VERSION ""

NS_ :

BS_:

BU_: L_3HKBD L_FHPTC L_ATCU L_2HKBD L_PCM L_ATCU_vMON L_EVNT L_HKBD L_RHPTC

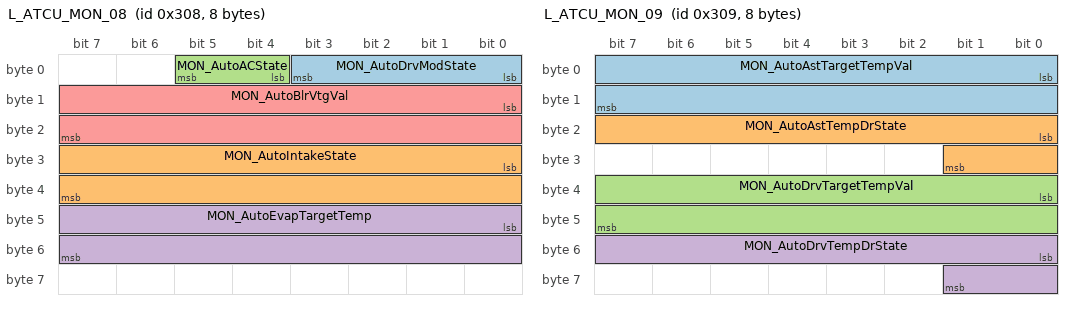
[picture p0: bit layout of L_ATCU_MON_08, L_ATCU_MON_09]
BO_ 776 L_ATCU_MON_08: 8 L_ATCU_vMON
 SG_ MON_AutoDrvModState : 0|4@1+ (1,0) [0|15] ""  L_ATCU
 SG_ MON_AutoIntakeState : 24|16@1+ (1,0) [0|65535] ""  L_ATCU
 SG_ MON_AutoACState : 4|2@1+ (1,0) [0|3] ""  L_ATCU
 SG_ MON_AutoEvapTargetTemp : 40|16@1+ (0.1,-20) [-20|40] ""  L_ATCU
 SG_ MON_AutoBlrVtgVal : 8|16@1+ (1,0) [0|65535] ""  L_ATCU

BO_ 777 L_ATCU_MON_09: 8 L_ATCU_vMON
 SG_ MON_AutoAstTargetTempVal : 0|16@1+ (0.1,-40) [-40|60] ""  L_ATCU
 SG_ MON_AutoAstTempDrState : 16|10@1+ (1,0) [0|1023] ""  L_ATCU
 SG_ MON_AutoDrvTargetTempVal : 32|16@1+ (0.1,-40) [-40|60] ""  L_ATCU
 SG_ MON_AutoDrvTempDrState : 48|10@1+ (1,0) [0|1023] "%"  L_ATCU

BO_ 68 L_HKBD_04: 8 L_HKBD
 SG_ HKBD_Fr_DrTempDnSw : 0|1@1+ (1,0) [0|0] ""  L_ATCU
 SG_ HKBD_Fr_DrTempUpSw : 1|1@1+ (1,0) [0|0] ""  L_ATCU
 SG_ HKBD_Fr_PsBlwDnSw : 11|1@1+ (1,0) [0|0] ""  L_ATCU
 SG_ HKBD_Fr_PsBlwDnOffSw : 12|1@1+ (1,0) [0|0] ""  L_ATCU
 SG_ HKBD_Fr_PsBlwUpSw : 13|1@1+ (1,0) [0|0] ""  L_ATCU
 SG_ HKBD_Fr_PsBlwSet : 14|4@1+ (1,0) [0|0] ""  L_ATCU
 SG_ HKBD_Fr_RrDrTempDnSw : 18|1@1+ (1,0) [0|0] ""  L_ATCU
 SG_ HKBD_Fr_RrDrTempUpSw : 19|1@1+ (1,0) [0|0] ""  L_ATCU
 SG_ HKBD_Fr_PsTempDnSw : 2|1@1+ (1,0) [0|0] ""  L_ATCU
 SG_ HKBD_Fr_RrDrBlwDnSw : 20|1@1+ (1,0) [0|0] ""  L_ATCU
 SG_ HKBD_Fr_RrDrBlwDnOffSw : 21|1@1+ (1,0) [0|0] ""  L_ATCU
 SG_ HKBD_Fr_RrDrBlwUpSw : 22|1@1+ (1,0) [0|0] ""  L_ATCU
 SG_ HKBD_Fr_RrDrBlwSet : 23|4@1+ (1,0) [0|0] ""  L_ATCU
 SG_ HKBD_Fr_RrDrModDnSw : 27|1@1+ (1,0) [0|0] ""  L_ATCU
 SG_ HKBD_Fr_RrDrModUpSw : 28|1@1+ (1,0) [0|0] ""  L_ATCU
 SG_ HKBD_Fr_RrDrModVntSw : 29|1@1+ (1,0) [0|0] ""  L_ATCU
 SG_ HKBD_Fr_PsTempUpSw : 3|1@1+ (1,0) [0|0] ""  L_ATCU
 SG_ HKBD_Fr_RrDrModFlrSw : 30|1@1+ (1,0) [0|0] ""  L_ATCU
 SG_ HKBD_Fr_RrDrModBiLvlSw : 31|1@1+ (1,0) [0|0] ""  L_ATCU
 SG_ HKBD_Fr_RrDrAutoSw : 32|1@1+ (1,0) [0|0] ""  L_ATCU
 SG_ HKBD_Fr_RrDrMultiAutoSw : 33|3@1+ (1,0) [0|0] ""  L_ATCU
 SG_ HKBD_Fr_RrOffSw : 36|1@1+ (1,0) [0|0] ""  L_ATCU
 SG_ HKBD_Fr_RrSyncSw : 37|1@1+ (1,0) [0|0] ""  L_ATCU
 SG_ HKBD_Fr_RLStHeatSw : 38|1@1+ (1,0) [0|0] ""  L_ATCU
 SG_ HKBD_Fr_RLStVentSw : 39|1@1+ (1,0) [0|0] ""  L_ATCU
 SG_ HKBD_Fr_DrBlwDnSw : 4|1@1+ (1,0) [0|0] ""  L_ATCU
 SG_ HKBD_Fr_RRStHeatSw : 40|1@1+ (1,0) [0|0] ""  L_ATCU
 SG_ HKBD_Fr_RRStVentSw : 41|1@1+ (1,0) [0|0] ""  L_ATCU
 SG_ HKBD_Fr_RLStTumblrSw : 42|2@1+ (1,0) [0|0] ""  L_ATCU
 SG_ HKBD_Fr_RRStTumblrSw : 44|2@1+ (1,0) [0|0] ""  L_ATCU
 SG_ HKBD_Fr_RrPsModDnSw : 46|1@1+ (1,0) [0|0] ""  L_ATCU
 SG_ HKBD_Fr_RrPsModUpSw : 47|1@1+ (1,0) [0|0] ""  L_ATCU
 SG_ HKBD_Fr_RrPsModVntSw : 48|1@1+ (1,0) [0|0] ""  L_ATCU
 SG_ HKBD_Fr_RrPsModFlrSw : 49|1@1+ (1,0) [0|0] ""  L_ATCU
 SG_ HKBD_Fr_DrBlwDnOffSw : 5|1@1+ (1,0) [0|0] ""  L_ATCU
 SG_ HKBD_Fr_RrLockSw : 50|1@1+ (1,0) [0|0] ""  L_ATCU
 SG_ HKBD_Fr_RrPsModBiLvlSw : 51|1@1+ (1,0) [0|0] ""  L_ATCU
 SG_ HKBD_Fr_RrDrModSw : 52|1@1+ (1,0) [0|0] ""  L_ATCU
 SG_ HKBD_Fr_RrPsModSw : 53|1@1+ (1,0) [0|0] ""  L_ATCU
 SG_ HKBD_Fr_RrPsBlwSet : 54|4@1+ (1,0) [0|0] ""  L_ATCU
 SG_ HKBD_Fr_RrPsBlwUpSw : 58|1@1+ (1,0) [0|0] ""  L_ATCU
 SG_ HKBD_Fr_RrPsBlwDnSw : 59|1@1+ (1,0) [0|0] ""  L_ATCU
 SG_ HKBD_Fr_DrBlwUpSw : 6|1@1+ (1,0) [0|0] ""  L_ATCU
 SG_ HKBD_Fr_RrPsBlwDnOffSw : 60|1@1+ (1,0) [0|0] ""  L_ATCU
 SG_ HKBD_Fr_RrPsTempDnSw : 61|1@1+ (1,0) [0|0] ""  L_ATCU
 SG_ HKBD_Fr_RrPsTempUpSw : 62|1@1+ (1,0) [0|0] ""  L_ATCU
 SG_ HKBD_Fr_DrBlwSet : 7|4@1+ (1,0) [0|0] ""  L_ATCU

BO_ 1032 L_EVNT_08: 8 L_EVNT
 SG_ L_EVNT_ATCUComFlt : 0|2@1+ (1,0) [0|0] ""  L_ATCU
 SG_ L_EVNT_DrvCntrHorComFlt : 10|2@1+ (1,0) [0|0] ""  L_ATCU
 SG_ L_EVNT_AstSdVertComFlt : 12|2@1+ (1,0) [0|0] ""  L_ATCU
 SG_ L_EVNT_AstSdHorComFlt : 14|2@1+ (1,0) [0|0] ""  L_ATCU
 SG_ L_EVNT_AstCntrVertComFlt : 16|2@1+ (1,0) [0|0] ""  L_ATCU
 SG_ L_EVNT_AstCntrHorComFlt : 18|2@1+ (1,0) [0|0] ""  L_ATCU
 SG_ L_EVNT_EVNTFlt : 2|2@1+ (1,0) [0|0] ""  L_ATCU
 SG_ L_EVNT_RrDrvCnslVertComFlt : 20|2@1+ (1,0) [0|0] ""  L_ATCU
 SG_ L_EVNT_RrDrvCnslHorComFlt : 22|2@1+ (1,0) [0|0] ""  L_ATCU
 SG_ L_EVNT_RrAstCnslVertComFlt : 24|2@1+ (1,0) [0|0] ""  L_ATCU
 SG_ L_EVNT_RrAstCnslHorComFlt : 26|2@1+ (1,0) [0|0] ""  L_ATCU
 SG_ L_EVNT_DrvSdVertIntFlt : 28|2@1+ (1,0) [0|0] ""  L_ATCU
 SG_ L_EVNT_DrvSdHorIntFlt : 30|2@1+ (1,0) [0|0] ""  L_ATCU
 SG_ L_EVNT_DrvCntrVertIntFlt : 32|2@1+ (1,0) [0|0] ""  L_ATCU
 SG_ L_EVNT_DrvCntrHorIntFlt : 34|2@1+ (1,0) [0|0] ""  L_ATCU
 SG_ L_EVNT_AstSdVertIntFlt : 36|2@1+ (1,0) [0|0] ""  L_ATCU
 SG_ L_EVNT_AstSdHorIntFlt : 38|2@1+ (1,0) [0|0] ""  L_ATCU
 SG_ L_EVNT_DrvSdVertComFlt : 4|2@1+ (1,0) [0|0] ""  L_ATCU
 SG_ L_EVNT_AstCntrVertIntFlt : 40|2@1+ (1,0) [0|0] ""  L_ATCU
 SG_ L_EVNT_AstCntrHorIntFlt : 42|2@1+ (1,0) [0|0] ""  L_ATCU
 SG_ L_EVNT_RrDrvCnslVertIntFlt : 44|2@1+ (1,0) [0|0] ""  L_ATCU
 SG_ L_EVNT_RrDrvCnslHorIntFlt : 46|2@1+ (1,0) [0|0] ""  L_ATCU
 SG_ L_EVNT_RrAstCnslVertIntFlt : 48|2@1+ (1,0) [0|0] ""  L_ATCU
 SG_ L_EVNT_RrAstCnslHorIntFlt : 50|2@1+ (1,0) [0|0] ""  L_ATCU
 SG_ L_EVNT_DrvSdVertExtFlt : 52|2@1+ (1,0) [0|0] ""  L_ATCU
 SG_ L_EVNT_DrvSdHorExtFlt : 54|2@1+ (1,0) [0|0] ""  L_ATCU
 SG_ L_EVNT_DrvCntrVertExtFlt : 56|2@1+ (1,0) [0|0] ""  L_ATCU
 SG_ L_EVNT_DrvCntrHorExtFlt : 58|2@1+ (1,0) [0|0] ""  L_ATCU
 SG_ L_EVNT_DrvSdHorComFlt : 6|2@1+ (1,0) [0|0] ""  L_ATCU
 SG_ L_EVNT_AstSdVertExtFlt : 60|2@1+ (1,0) [0|0] ""  L_ATCU
 SG_ L_EVNT_AstSdHorExtFlt : 62|2@1+ (1,0) [0|0] ""  L_ATCU
 SG_ L_EVNT_DrvCntrVertComFlt : 8|2@1+ (1,0) [0|0] ""  L_ATCU

BO_ 881 L_ATCU_Lib_33: 8 L_ATCU
 SG_ L_ATCU_Lib_StatMngr_2ndMngr : 0|64@1+ (1,0) [0|0] ""  L_ATCU_vMON

BO_ 69 L_HKBD_05: 8 L_HKBD
 SG_ HKBD_Fr_3rdRrTempDnSw : 0|1@1+ (1,0) [0|0] ""  L_ATCU
 SG_ HKBD_Fr_3rdRrTempUpSw : 1|1@1+ (1,0) [0|0] ""  L_ATCU
 SG_ HKBD_Fr_3rdRrModUpSw : 10|1@1+ (1,0) [0|0] ""  L_ATCU
 SG_ HKBD_Fr_3rdRrModVntSw : 11|1@1+ (1,0) [0|0] ""  L_ATCU
 SG_ HKBD_Fr_3rdRrModFlrSw : 12|1@1+ (1,0) [0|0] ""  L_ATCU
 SG_ HKBD_Fr_3rdRrAutoSw : 13|1@1+ (1,0) [0|0] ""  L_ATCU
 SG_ HKBD_Fr_3rdRrMultiAutoSw : 14|3@1+ (1,0) [0|0] ""  L_ATCU
 SG_ HKBD_Fr_3rdRrOffSw : 17|1@1+ (1,0) [0|0] ""  L_ATCU
 SG_ HKBD_Fr_3rdRrSyncSw : 18|1@1+ (1,0) [0|0] ""  L_ATCU
 SG_ HKBD_Fr_3rdRrLockSw : 19|1@1+ (1,0) [0|0] ""  L_ATCU
 SG_ HKBD_Fr_3rdRrBlwDnSw : 2|1@1+ (1,0) [0|0] ""  L_ATCU
 SG_ HKBD_Fr_3rdRrModBiLvlSw : 20|1@1+ (1,0) [0|0] ""  L_ATCU
 SG_ HKBD_FrRrTglSet : 21|2@1+ (1,0) [0|0] ""  L_ATCU
 SG_ HKBD_Fr_RrScrnSet : 23|2@1+ (1,0) [0|0] ""  L_ATCU
 SG_ HKBD_Fr_OnOffSet : 25|2@1+ (1,0) [0|0] ""  L_ATCU
 SG_ HKBD_Fr_RrOnOffSet : 27|2@1+ (1,0) [0|0] ""  L_ATCU
 SG_ HKBD_Fr_3rdRrOnOffSet : 29|2@1+ (1,0) [0|0] ""  L_ATCU
 SG_ HKBD_Fr_3rdRrBlwDnOffSw : 3|1@1+ (1,0) [0|0] ""  L_ATCU
 SG_ HKBD_Fr_RrPsAutoSw : 31|1@1+ (1,0) [0|0] ""  L_ATCU
 SG_ HKBD_Fr_RrPsMultiAutoSw : 32|3@1+ (1,0) [0|0] ""  L_ATCU
 SG_ HKBD_Fr_3rdRrModSw : 35|1@1+ (1,0) [0|0] ""  L_ATCU
 SG_ HKBD_Fr_RrModSet : 36|4@1+ (1,0) [0|0] ""  L_ATCU
 SG_ HKBD_Fr_3rdRrBlwUpSw : 4|1@1+ (1,0) [0|0] ""  L_ATCU
 SG_ HKBD_Fr_3rdModSet : 40|4@1+ (1,0) [0|0] ""  L_ATCU
 SG_ HKBD_Fr_DrblwUpMaxSw : 44|1@1+ (1,0) [0|0] ""  L_ATCU
 SG_ HKBD_Fr_PsblwUpMaxSw : 45|1@1+ (1,0) [0|0] ""  L_ATCU
 SG_ HKBD_Fr_3rdRrBlwSet : 5|4@1+ (1,0) [0|0] ""  L_ATCU
 SG_ HKBD_Fr_3rdRrModDnSw : 9|1@1+ (1,0) [0|0] ""  L_ATCU

BO_ 1033 L_EVNT_09: 8 L_EVNT
 SG_ L_EVNT_AstCntrVertExtFlt : 0|2@1+ (1,0) [0|0] ""  L_ATCU
 SG_ L_EVNT_RrAstCnslHorExtFlt : 10|2@1+ (1,0) [0|0] ""  L_ATCU
 SG_ L_EVNT_AstCntrHorExtFlt : 2|2@1+ (1,0) [0|0] ""  L_ATCU
 SG_ L_EVNT_AllResetOpSta : 36|2@1+ (1,0) [0|0] ""  L_ATCU
 SG_ L_EVNT_DrvSdVertResetOpSta : 38|2@1+ (1,0) [0|0] ""  L_ATCU
 SG_ L_EVNT_RrDrvCnslVertExtFlt : 4|2@1+ (1,0) [0|0] ""  L_ATCU
 SG_ L_EVNT_DrvSdHorResetOpSta : 40|2@1+ (1,0) [0|0] ""  L_ATCU
 SG_ L_EVNT_DrvCntrVertResetOpSta : 42|2@1+ (1,0) [0|0] ""  L_ATCU
 SG_ L_EVNT_DrvCntrHorResetOpSta : 44|2@1+ (1,0) [0|0] ""  L_ATCU
 SG_ L_EVNT_AstSdVertResetOpSta : 46|2@1+ (1,0) [0|0] ""  L_ATCU
 SG_ L_EVNT_AstSdHorResetOpSta : 48|2@1+ (1,0) [0|0] ""  L_ATCU
 SG_ L_EVNT_AstCntrVertResetOpSta : 50|2@1+ (1,0) [0|0] ""  L_ATCU
 SG_ L_EVNT_AstCntrHorResetOpSta : 52|2@1+ (1,0) [0|0] ""  L_ATCU
 SG_ L_EVNT_RrDrvCnslVertResetOpSta : 54|2@1+ (1,0) [0|0] ""  L_ATCU
 SG_ L_EVNT_RrDrvCnslHorResetOpSta : 56|2@1+ (1,0) [0|0] ""  L_ATCU
 SG_ L_EVNT_RrAstCnslVertResetOpSta : 58|2@1+ (1,0) [0|0] ""  L_ATCU
 SG_ L_EVNT_RrDrvCnslHorExtFlt : 6|2@1+ (1,0) [0|0] ""  L_ATCU
 SG_ L_EVNT_RrAstCnslHorResetOpSta : 60|2@1+ (1,0) [0|0] ""  L_ATCU
 SG_ L_EVNT_ResetOpSta : 62|2@1+ (1,0) [0|0] ""  L_ATCU
 SG_ L_EVNT_RrAstCnslVertExtFlt : 8|2@1+ (1,0) [0|0] ""  L_ATCU

BO_ 880 L_ATCU_Lib_32: 8 L_ATCU
 SG_ L_ATCU_Lib_StatMngr_2ndSafetynCool : 0|64@1+ (1,0) [0|0] ""  L_ATCU_vMON

BO_ 70 L_HKBD_06: 8 L_HKBD
 SG_ HKBD_SwBtnTyp : 0|40@1+ (1,0) [0|0] ""  L_ATCU
 SG_ L_HKBD_ResetOpSta : 62|2@1+ (1,0) [0|0] ""  L_ATCU

BO_ 883 L_ATCU_Lib_35: 8 L_ATCU
 SG_ L_ATCU_Lib_StatMngr_2ndAirQuality : 0|64@1+ (1,0) [0|0] ""  L_ATCU_vMON

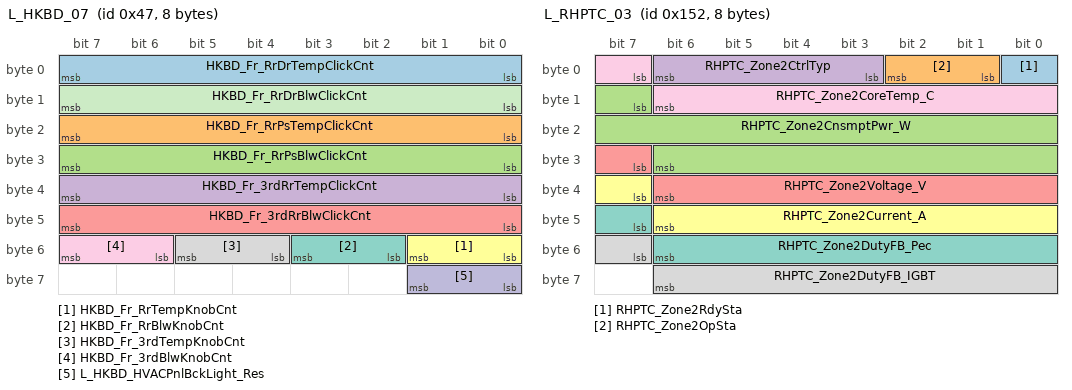
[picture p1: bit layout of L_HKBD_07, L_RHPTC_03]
BO_ 71 L_HKBD_07: 8 L_HKBD
 SG_ HKBD_Fr_RrDrTempClickCnt : 0|8@1+ (1,0) [0|0] ""  L_ATCU
 SG_ HKBD_Fr_RrPsTempClickCnt : 16|8@1+ (1,0) [0|0] ""  L_ATCU
 SG_ HKBD_Fr_RrPsBlwClickCnt : 24|8@1+ (1,0) [0|0] ""  L_ATCU
 SG_ HKBD_Fr_3rdRrTempClickCnt : 32|8@1+ (1,0) [0|0] ""  L_ATCU
 SG_ HKBD_Fr_3rdRrBlwClickCnt : 40|8@1+ (1,0) [0|0] ""  L_ATCU
 SG_ HKBD_Fr_RrTempKnobCnt : 48|2@1+ (1,0) [0|0] ""  L_ATCU
 SG_ HKBD_Fr_RrBlwKnobCnt : 50|2@1+ (1,0) [0|0] ""  L_ATCU
 SG_ HKBD_Fr_3rdTempKnobCnt : 52|2@1+ (1,0) [0|0] ""  L_ATCU
 SG_ HKBD_Fr_3rdBlwKnobCnt : 54|2@1+ (1,0) [0|0] ""  L_ATCU
 SG_ L_HKBD_HVACPnlBckLight_Res : 56|2@1+ (1,0) [0|0] ""  L_ATCU
 SG_ HKBD_Fr_RrDrBlwClickCnt : 8|8@1+ (1,0) [0|0] ""  L_ATCU

BO_ 882 L_ATCU_Lib_34: 8 L_ATCU
 SG_ L_ATCU_Lib_StatMngr_2ndConvenience : 0|64@1+ (1,0) [0|0] ""  L_ATCU_vMON

BO_ 339 L_RHPTC_04: 8 L_RHPTC
 SG_ RHPTC_Zone2Flt : 0|1@1+ (1,0) [0|0] ""  L_ATCU
 SG_ RHPTC_Zone2FltLVLow : 1|1@1+ (1,0) [0|0] ""  L_ATCU
 SG_ RHPTC_Zone2FailLVSnr : 10|1@1+ (1,0) [0|0] ""  L_ATCU
 SG_ RHPTC_Zone2FailCurrentSnr : 11|1@1+ (1,0) [0|0] ""  L_ATCU
 SG_ RHPTC_Zone2FailCoreTempSnr : 12|1@1+ (1,0) [0|0] ""  L_ATCU
 SG_ RHPTC_Zone2FailPcbTempSnr : 13|1@1+ (1,0) [0|0] ""  L_ATCU
 SG_ RHPTC_Zone2FailIGBT : 14|1@1+ (1,0) [0|0] ""  L_ATCU
 SG_ RHPTC_Zone2FailOpenLoad : 15|1@1+ (1,0) [0|0] ""  L_ATCU
 SG_ RHPTC_Zone2LtdOpCause : 16|8@1+ (1,0) [0|0] ""  L_ATCU
 SG_ RHPTC_Zone2FltLVHigh : 2|1@1+ (1,0) [0|0] ""  L_ATCU
 SG_ RHPTC_Zone2SwrVer : 24|8@1+ (1,0) [0|255] ""  L_ATCU
 SG_ RHPTC_Zone2FltHVLow : 3|1@1+ (1,0) [0|0] ""  L_ATCU
 SG_ RHPTC_Zone2FltHVHigh : 4|1@1+ (1,0) [0|0] ""  L_ATCU
 SG_ RHPTC_Zone2FltOverCurrent : 5|1@1+ (1,0) [0|0] ""  L_ATCU
 SG_ RHPTC_Zone2FltThermalShutDn : 6|1@1+ (1,0) [0|0] ""  L_ATCU
 SG_ RHPTC_Zone2FltPcbThermalShutDn : 7|1@1+ (1,0) [0|0] ""  L_ATCU
 SG_ RHPTC_Zone2FltMsgTmOutATCU : 8|1@1+ (1,0) [0|0] ""  L_ATCU
 SG_ RHPTC_Zone2FailHVSnr : 9|1@1+ (1,0) [0|0] ""  L_ATCU

BO_ 885 L_ATCU_Lib_37: 8 L_ATCU
 SG_ L_ATCU_Lib_StatMngr_2ndFuelEfficiency : 0|64@1+ (1,0) [0|0] ""  L_ATCU_vMON

BO_ 338 L_RHPTC_03: 8 L_RHPTC
 SG_ RHPTC_Zone2RdySta : 0|1@1+ (1,0) [0|0] ""  L_ATCU
 SG_ RHPTC_Zone2OpSta : 1|2@1+ (1,0) [0|0] ""  L_ATCU
 SG_ RHPTC_Zone2CnsmptPwr_W : 15|16@1+ (1,0) [0|10000] "W"  L_ATCU
 SG_ RHPTC_Zone2CtrlTyp : 3|4@1+ (1,0) [0|0] ""  L_ATCU
 SG_ RHPTC_Zone2Voltage_V : 31|8@1+ (4,0) [0|1000] "V"  L_ATCU
 SG_ RHPTC_Zone2Current_A : 39|8@1+ (0.2,0) [0|50] "A"  L_ATCU
 SG_ RHPTC_Zone2DutyFB_Pec : 47|8@1+ (0.5,0) [0|100] "%"  L_ATCU
 SG_ RHPTC_Zone2DutyFB_IGBT : 55|8@1+ (0.5,0) [0|100] "%"  L_ATCU
 SG_ RHPTC_Zone2CoreTemp_C : 7|8@1+ (1,-40) [-40|200] "¡É"  L_ATCU

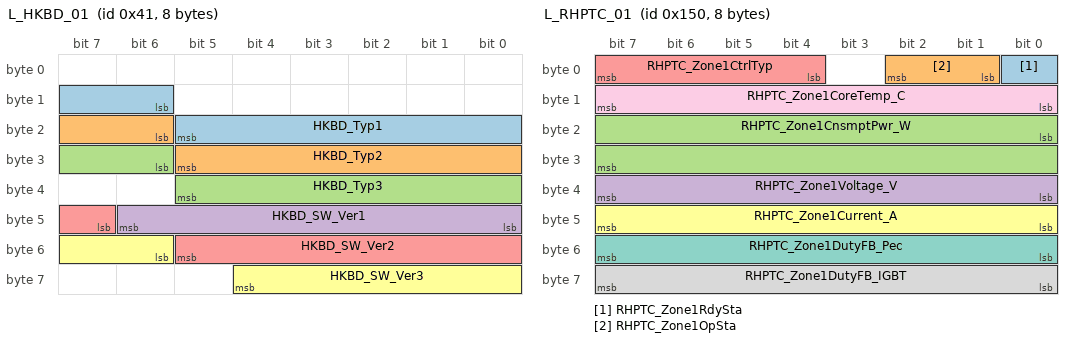
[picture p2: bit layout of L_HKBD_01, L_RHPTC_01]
BO_ 65 L_HKBD_01: 8 L_HKBD
 SG_ HKBD_Typ1 : 14|8@1+ (1,0) [0|0] ""  L_ATCU
 SG_ HKBD_Typ2 : 22|8@1+ (1,0) [0|0] ""  L_ATCU
 SG_ HKBD_Typ3 : 30|8@1+ (1,0) [0|0] ""  L_ATCU
 SG_ HKBD_SW_Ver1 : 40|7@1+ (1,0) [0|0] ""  L_ATCU_vMON
 SG_ HKBD_SW_Ver2 : 47|7@1+ (1,0) [0|0] ""  L_ATCU_vMON
 SG_ HKBD_SW_Ver3 : 54|7@1+ (1,0) [0|0] ""  L_ATCU_vMON

BO_ 884 L_ATCU_Lib_36: 8 L_ATCU
 SG_ L_ATCU_Lib_StatMngr_2ndETC : 0|64@1+ (1,0) [0|0] ""  L_ATCU_vMON

BO_ 337 L_RHPTC_02: 8 L_RHPTC
 SG_ RHPTC_Zone1Flt : 0|1@1+ (1,0) [0|0] ""  L_ATCU
 SG_ RHPTC_Zone1FltLVLow : 1|1@1+ (1,0) [0|0] ""  L_ATCU
 SG_ RHPTC_Zone1FailLVSnr : 10|1@1+ (1,0) [0|0] ""  L_ATCU
 SG_ RHPTC_Zone1FailCurrentSnr : 11|1@1+ (1,0) [0|0] ""  L_ATCU
 SG_ RHPTC_Zone1FailCoreTempSnr : 12|1@1+ (1,0) [0|0] ""  L_ATCU
 SG_ RHPTC_Zone1FailPcbTempSnr : 13|1@1+ (1,0) [0|0] ""  L_ATCU
 SG_ RHPTC_Zone1FailIGBT : 14|1@1+ (1,0) [0|0] ""  L_ATCU
 SG_ RHPTC_Zone1FailOpenLoad : 15|1@1+ (1,0) [0|0] ""  L_ATCU
 SG_ RHPTC_Zone1LtdOpCause : 16|8@1+ (1,0) [0|0] ""  L_ATCU
 SG_ RHPTC_Zone1FltLVHigh : 2|1@1+ (1,0) [0|0] ""  L_ATCU
 SG_ RHPTC_Zone1SwVer : 24|8@1+ (1,0) [0|255] ""  L_ATCU
 SG_ RHPTC_Zone1FltHVLow : 3|1@1+ (1,0) [0|0] ""  L_ATCU
 SG_ RHPTC_CnsmptPwrTtl_W : 32|16@1+ (1,0) [0|10000] "W"  L_ATCU
 SG_ RHPTC_Zone1FltHVHigh : 4|1@1+ (1,0) [0|0] ""  L_ATCU
 SG_ RHPTC_IntlkSta : 48|2@1+ (1,0) [0|0] ""  L_ATCU
 SG_ RHPTC_Zone1FltOverCurrent : 5|1@1+ (1,0) [0|0] ""  L_ATCU
 SG_ RHPTC_Zone1FltThermalShutDn : 6|1@1+ (1,0) [0|0] ""  L_ATCU
 SG_ RHPTC_Zone1FltPcbThermalShutDn : 7|1@1+ (1,0) [0|0] ""  L_ATCU
 SG_ RHPTC_Zone1FltMsgTmOutATCU : 8|1@1+ (1,0) [0|0] ""  L_ATCU
 SG_ RHPTC_Zone1FailHVSnr : 9|1@1+ (1,0) [0|0] ""  L_ATCU

BO_ 66 L_HKBD_02: 8 L_HKBD
 SG_ HKBD_Fr_DrModDnSw : 0|1@1+ (1,0) [0|0] ""  L_ATCU
 SG_ HKBD_Fr_DrModUpSw : 1|1@1+ (1,0) [0|0] ""  L_ATCU
 SG_ HKBD_Fr_DrMultiAutoSw : 10|3@1+ (1,0) [0|0] ""  L_ATCU
 SG_ HKBD_Fr_PsAutoSw : 13|1@1+ (1,0) [0|0] ""  L_ATCU
 SG_ HKBD_Fr_PsMultiAutoSw : 14|3@1+ (1,0) [0|0] ""  L_ATCU
 SG_ HKBD_Fr_AcSw : 17|1@1+ (1,0) [0|0] ""  L_ATCU
 SG_ HKBD_Fr_DefSw : 18|1@1+ (1,0) [0|0] ""  L_ATCU
 SG_ HKBD_Fr_RecSw : 19|1@1+ (1,0) [0|0] ""  L_ATCU
 SG_ HKBD_Fr_DrModVntSw : 2|1@1+ (1,0) [0|0] ""  L_ATCU
 SG_ HKBD_Fr_FreSw : 20|1@1+ (1,0) [0|0] ""  L_ATCU
 SG_ HKBD_Fr_IntakeTglSw : 21|1@1+ (1,0) [0|0] ""  L_ATCU
 SG_ HKBD_Fr_OffSw : 22|1@1+ (1,0) [0|0] ""  L_ATCU
 SG_ HKBD_Fr_SyncSw : 23|1@1+ (1,0) [0|0] ""  L_ATCU
 SG_ HKBD_Fr_RrDefInd : 24|1@1+ (1,0) [0|0] ""  L_ATCU
 SG_ HKBD_Fr_RrDefSw : 25|1@1+ (1,0) [0|0] ""  L_ATCU
 SG_ HKBD_Fr_ArclnSw : 26|1@1+ (1,0) [0|0] ""  L_ATCU
 SG_ HKBD_Fr_DrOnlySw : 27|1@1+ (1,0) [0|0] ""  L_ATCU
 SG_ HKBD_Fr_ClimateSw : 28|1@1+ (1,0) [0|0] ""  L_ATCU
 SG_ HKBD_Fr_PerfumeSw : 29|1@1+ (1,0) [0|0] ""  L_ATCU
 SG_ HKBD_Fr_DrModFlrSw : 3|1@1+ (1,0) [0|0] ""  L_ATCU
 SG_ HKBD_Fr_HptIntnstySta : 30|4@1+ (1,0) [0|0] ""  L_ATCU
 SG_ HKBD_Fr_StrWhlHeatSw : 34|1@1+ (1,0) [0|0] ""  L_ATCU
 SG_ HKBD_FLStHeatSw : 35|1@1+ (1,0) [0|0] ""  L_ATCU
 SG_ HKBD_FLStVentSw : 36|1@1+ (1,0) [0|0] ""  L_ATCU
 SG_ HKBD_FRStHeatSw : 37|1@1+ (1,0) [0|0] ""  L_ATCU
 SG_ HKBD_FRStVentSw : 38|1@1+ (1,0) [0|0] ""  L_ATCU
 SG_ HKBD_FLStTumblrSw : 39|2@1+ (1,0) [0|0] ""  L_ATCU
 SG_ HKBD_Fr_DrModDefSw : 4|1@1+ (1,0) [0|0] ""  L_ATCU
 SG_ HKBD_FRStTumblrSw : 41|2@1+ (1,0) [0|0] ""  L_ATCU
 SG_ HKBD_Fr_FrWndShldHtSw : 43|1@1+ (1,0) [0|0] ""  L_ATCU
 SG_ HKBD_Fr_DrAutoDnSw : 44|1@1+ (1,0) [0|0] ""  L_ATCU
 SG_ HKBD_Fr_DrAutoUpSw : 45|1@1+ (1,0) [0|0] ""  L_ATCU
 SG_ HKBD_Fr_DrModSw : 46|1@1+ (1,0) [0|0] ""  L_ATCU
 SG_ HKBD_Fr_PsModSw : 47|1@1+ (1,0) [0|0] ""  L_ATCU
 SG_ HKBD_DisplayTheme : 48|2@1+ (1,0) [0|0] ""  L_ATCU
 SG_ HKBD_Fr_PsModDnSw : 5|1@1+ (1,0) [0|0] ""  L_ATCU
 SG_ HKBD_Fr_SmartZoneSW : 50|1@1+ (1,0) [0|0] ""  L_ATCU
 SG_ HKBD_Fr_ModSet : 51|4@1+ (1,0) [0|0] ""  L_ATCU
 SG_ HKBD_Fr_MTCTempLvlSet : 55|5@1+ (1,0) [0|0] ""  L_ATCU
 SG_ HKBD_Fr_PsModUpSw : 6|1@1+ (1,0) [0|0] ""  L_ATCU
 SG_ HKBD_Fr_PsModVntSw : 7|1@1+ (1,0) [0|0] ""  L_ATCU
 SG_ HKBD_Fr_PsModFlrSw : 8|1@1+ (1,0) [0|0] ""  L_ATCU
 SG_ HKBD_Fr_DrAutoSw : 9|1@1+ (1,0) [0|0] ""  L_ATCU

BO_ 336 L_RHPTC_01: 8 L_RHPTC
 SG_ RHPTC_Zone1RdySta : 0|1@1+ (1,0) [0|0] ""  L_ATCU
 SG_ RHPTC_Zone1OpSta : 1|2@1+ (1,0) [0|0] ""  L_ATCU
 SG_ RHPTC_Zone1CnsmptPwr_W : 16|16@1+ (1,0) [0|10000] "W"  L_ATCU
 SG_ RHPTC_Zone1Voltage_V : 32|8@1+ (4,0) [0|1000] "V"  L_ATCU
 SG_ RHPTC_Zone1CtrlTyp : 4|4@1+ (1,0) [0|0] ""  L_ATCU
 SG_ RHPTC_Zone1Current_A : 40|8@1+ (0.2,0) [0|50] "A"  L_ATCU
 SG_ RHPTC_Zone1DutyFB_Pec : 48|8@1+ (0.5,0) [0|100] "%"  L_ATCU
 SG_ RHPTC_Zone1DutyFB_IGBT : 56|8@1+ (0.5,0) [0|100] "%"  L_ATCU
 SG_ RHPTC_Zone1CoreTemp_C : 8|8@1+ (1,-40) [-40|200] "¡É"  L_ATCU

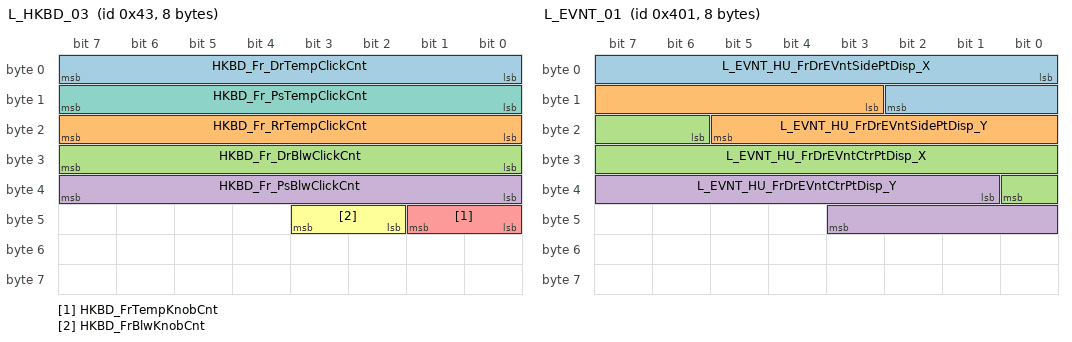
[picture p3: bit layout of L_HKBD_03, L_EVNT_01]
BO_ 67 L_HKBD_03: 8 L_HKBD
 SG_ HKBD_Fr_DrTempClickCnt : 0|8@1+ (1,0) [0|0] ""  L_ATCU
 SG_ HKBD_Fr_RrTempClickCnt : 16|8@1+ (1,0) [0|0] ""  L_ATCU
 SG_ HKBD_Fr_DrBlwClickCnt : 24|8@1+ (1,0) [0|0] ""  L_ATCU
 SG_ HKBD_Fr_PsBlwClickCnt : 32|8@1+ (1,0) [0|0] ""  L_ATCU
 SG_ HKBD_FrTempKnobCnt : 40|2@1+ (1,0) [0|0] ""  L_ATCU
 SG_ HKBD_FrBlwKnobCnt : 42|2@1+ (1,0) [0|0] ""  L_ATCU
 SG_ HKBD_Fr_PsTempClickCnt : 8|8@1+ (1,0) [0|0] ""  L_ATCU

BO_ 886 L_ATCU_Lib_38: 8 L_ATCU
 SG_ L_ATCU_Lib_MEM_ROMWriteCnt : 0|32@1+ (1,0) [0|0] ""  L_ATCU_vMON

BO_ 1025 L_EVNT_01: 8 L_EVNT
 SG_ L_EVNT_HU_FrDrEVntSidePtDisp_X : 0|11@1+ (1,0) [0|0] ""  L_ATCU
 SG_ L_EVNT_HU_FrDrEVntSidePtDisp_Y : 11|11@1+ (1,0) [0|0] ""  L_ATCU
 SG_ L_EVNT_HU_FrDrEVntCtrPtDisp_X : 22|11@1+ (1,0) [0|0] ""  L_ATCU
 SG_ L_EVNT_HU_FrDrEVntCtrPtDisp_Y : 33|11@1+ (1,0) [0|0] ""  L_ATCU

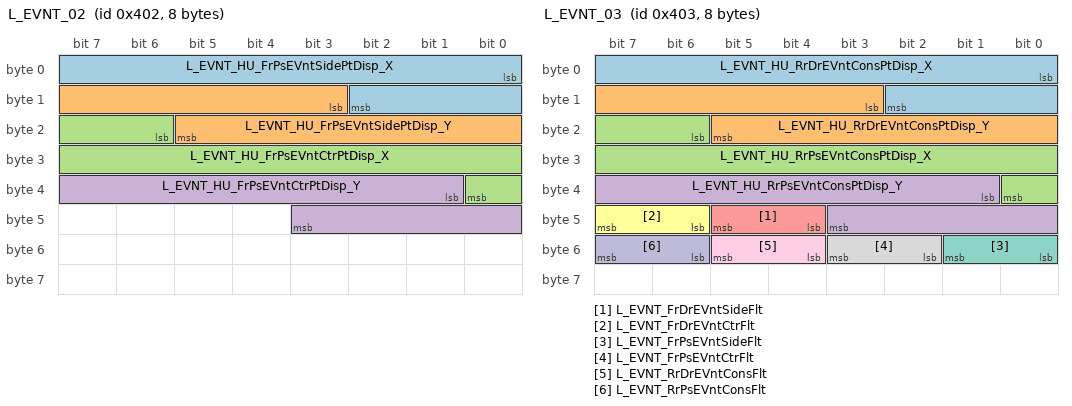
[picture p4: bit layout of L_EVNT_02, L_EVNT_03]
BO_ 1026 L_EVNT_02: 8 L_EVNT
 SG_ L_EVNT_HU_FrPsEVntSidePtDisp_X : 0|11@1+ (1,0) [0|0] ""  L_ATCU
 SG_ L_EVNT_HU_FrPsEVntSidePtDisp_Y : 11|11@1+ (1,0) [0|0] ""  L_ATCU
 SG_ L_EVNT_HU_FrPsEVntCtrPtDisp_X : 22|11@1+ (1,0) [0|0] ""  L_ATCU
 SG_ L_EVNT_HU_FrPsEVntCtrPtDisp_Y : 33|11@1+ (1,0) [0|0] ""  L_ATCU

BO_ 1027 L_EVNT_03: 8 L_EVNT
 SG_ L_EVNT_HU_RrDrEVntConsPtDisp_X : 0|11@1+ (1,0) [0|0] ""  L_ATCU
 SG_ L_EVNT_HU_RrDrEVntConsPtDisp_Y : 11|11@1+ (1,0) [0|0] ""  L_ATCU
 SG_ L_EVNT_HU_RrPsEVntConsPtDisp_X : 22|11@1+ (1,0) [0|0] ""  L_ATCU
 SG_ L_EVNT_HU_RrPsEVntConsPtDisp_Y : 33|11@1+ (1,0) [0|0] ""  L_ATCU
 SG_ L_EVNT_FrDrEVntSideFlt : 44|2@1+ (1,0) [0|0] ""  L_ATCU
 SG_ L_EVNT_FrDrEVntCtrFlt : 46|2@1+ (1,0) [0|0] ""  L_ATCU
 SG_ L_EVNT_FrPsEVntSideFlt : 48|2@1+ (1,0) [0|0] ""  L_ATCU
 SG_ L_EVNT_FrPsEVntCtrFlt : 50|2@1+ (1,0) [0|0] ""  L_ATCU
 SG_ L_EVNT_RrDrEVntConsFlt : 52|2@1+ (1,0) [0|0] ""  L_ATCU
 SG_ L_EVNT_RrPsEVntConsFlt : 54|2@1+ (1,0) [0|0] ""  L_ATCU

BO_ 72 L_HKBD_08: 8 L_HKBD
 SG_ HKBD_Fr_IncarRaw : 0|10@1+ (0.01,0) [0|0] "V"  L_ATCU

BO_ 1028 L_EVNT_04: 8 L_EVNT
 SG_ L_EVNT_FrDrEVntModeSet_Disp : 0|4@1+ (1,0) [0|0] ""  L_ATCU
 SG_ L_EVNT_RrPsEVntModeSet_Disp : 12|4@1+ (1,0) [0|0] ""  L_ATCU
 SG_ L_EVNT_FrDrEVntSideOpnClsDisp : 16|2@1+ (1,0) [0|0] ""  L_ATCU
 SG_ L_EVNT_FrDrEVntCtrOpnClsDisp : 18|2@1+ (1,0) [0|0] ""  L_ATCU
 SG_ L_EVNT_FrPsEVntSideOpnClsDisp : 20|2@1+ (1,0) [0|0] ""  L_ATCU
 SG_ L_EVNT_FrPsEVntCtrOpnClsDisp : 22|2@1+ (1,0) [0|0] ""  L_ATCU
 SG_ L_EVNT_RrDrEVntConsOpnClsDisp : 24|2@1+ (1,0) [0|0] ""  L_ATCU
 SG_ L_EVNT_RrPsEVntConsOpnClsDisp : 26|2@1+ (1,0) [0|0] ""  L_ATCU
 SG_ L_EVNT_EVntTouchInform_HU : 28|2@1+ (1,0) [0|0] ""  L_ATCU
 SG_ L_EVNT_EVntTouchInform_CTS : 30|2@1+ (1,0) [0|0] ""  L_ATCU
 SG_ L_EVNT_FrtEvntFocusLvlSta : 32|3@1+ (1,0) [0|0] ""  L_ATCU
 SG_ L_EVNT_RrEvntFocusLvlSta : 35|3@1+ (1,0) [0|0] ""  L_ATCU
 SG_ L_EVNT_DrVntOpt : 38|2@1+ (1,0) [0|0] ""  L_ATCU
 SG_ L_EVNT_FrPsEVntModeSet_Disp : 4|4@1+ (1,0) [0|0] ""  L_ATCU
 SG_ L_EVNT_AstVntOpt : 40|2@1+ (1,0) [0|0] ""  L_ATCU
 SG_ L_EVNT_RrDrVntOpt : 42|2@1+ (1,0) [0|0] ""  L_ATCU
 SG_ L_EVNT_RrAstVntOpt : 44|2@1+ (1,0) [0|0] ""  L_ATCU
 SG_ L_EVNT_EVntAutoAirFlowHotKeyOpt : 46|2@1+ (1,0) [0|0] ""  L_ATCU
 SG_ L_EVNT_RrDrEVntModeSet_Disp : 8|4@1+ (1,0) [0|0] ""  L_ATCU

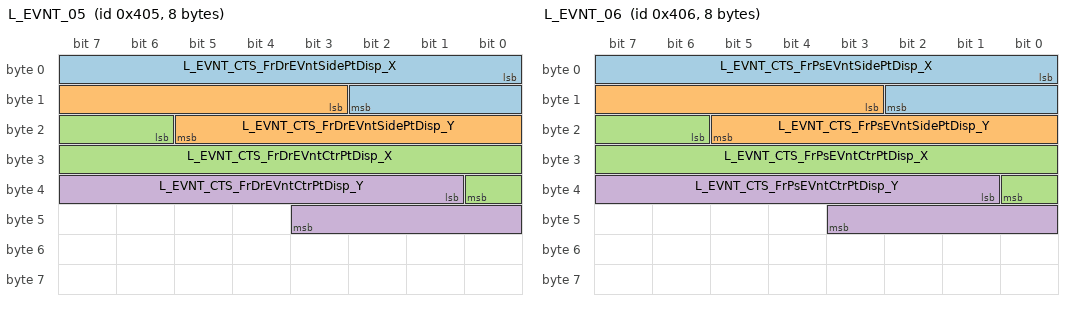
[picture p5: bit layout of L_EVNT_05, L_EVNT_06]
BO_ 1029 L_EVNT_05: 8 L_EVNT
 SG_ L_EVNT_CTS_FrDrEVntSidePtDisp_X : 0|11@1+ (1,0) [0|0] ""  L_ATCU
 SG_ L_EVNT_CTS_FrDrEVntSidePtDisp_Y : 11|11@1+ (1,0) [0|0] ""  L_ATCU
 SG_ L_EVNT_CTS_FrDrEVntCtrPtDisp_X : 22|11@1+ (1,0) [0|0] ""  L_ATCU
 SG_ L_EVNT_CTS_FrDrEVntCtrPtDisp_Y : 33|11@1+ (1,0) [0|0] ""  L_ATCU

BO_ 1030 L_EVNT_06: 8 L_EVNT
 SG_ L_EVNT_CTS_FrPsEVntSidePtDisp_X : 0|11@1+ (1,0) [0|0] ""  L_ATCU
 SG_ L_EVNT_CTS_FrPsEVntSidePtDisp_Y : 11|11@1+ (1,0) [0|0] ""  L_ATCU
 SG_ L_EVNT_CTS_FrPsEVntCtrPtDisp_X : 22|11@1+ (1,0) [0|0] ""  L_ATCU
 SG_ L_EVNT_CTS_FrPsEVntCtrPtDisp_Y : 33|11@1+ (1,0) [0|0] ""  L_ATCU

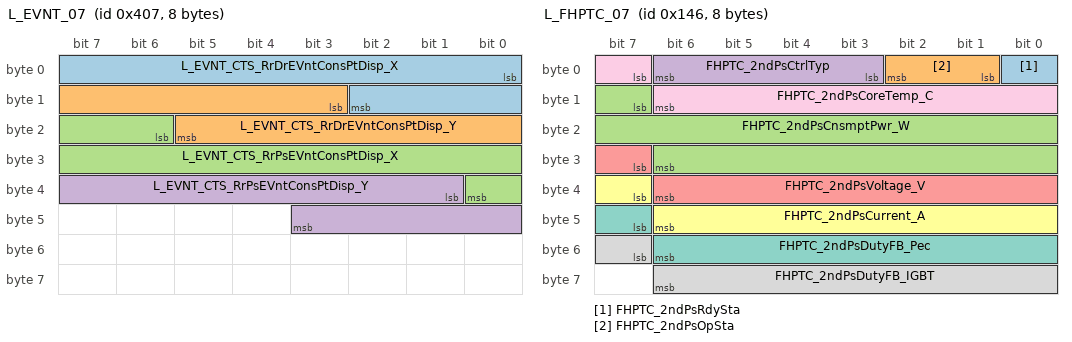
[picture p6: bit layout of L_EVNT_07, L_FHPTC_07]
BO_ 1031 L_EVNT_07: 8 L_EVNT
 SG_ L_EVNT_CTS_RrDrEVntConsPtDisp_X : 0|11@1+ (1,0) [0|0] ""  L_ATCU
 SG_ L_EVNT_CTS_RrDrEVntConsPtDisp_Y : 11|11@1+ (1,0) [0|0] ""  L_ATCU
 SG_ L_EVNT_CTS_RrPsEVntConsPtDisp_X : 22|11@1+ (1,0) [0|0] ""  L_ATCU
 SG_ L_EVNT_CTS_RrPsEVntConsPtDisp_Y : 33|11@1+ (1,0) [0|0] ""  L_ATCU

BO_ 326 L_FHPTC_07: 8 L_FHPTC
 SG_ FHPTC_2ndPsRdySta : 0|1@1+ (1,0) [0|0] ""  L_ATCU
 SG_ FHPTC_2ndPsOpSta : 1|2@1+ (1,0) [0|0] ""  L_ATCU
 SG_ FHPTC_2ndPsCnsmptPwr_W : 15|16@1+ (1,0) [0|10000] "W"  L_ATCU
 SG_ FHPTC_2ndPsCtrlTyp : 3|4@1+ (1,0) [0|0] ""  L_ATCU
 SG_ FHPTC_2ndPsVoltage_V : 31|8@1+ (4,0) [0|1000] "V"  L_ATCU
 SG_ FHPTC_2ndPsCurrent_A : 39|8@1+ (0.2,0) [0|50] "A"  L_ATCU
 SG_ FHPTC_2ndPsDutyFB_Pec : 47|8@1+ (0.5,0) [0|100] "%"  L_ATCU
 SG_ FHPTC_2ndPsDutyFB_IGBT : 55|8@1+ (0.5,0) [0|100] "%"  L_ATCU
 SG_ FHPTC_2ndPsCoreTemp_C : 7|8@1+ (1,-40) [-40|200] "¡É"  L_ATCU

BO_ 864 L_ATCU_Lib_16: 8 L_ATCU
 SG_ L_ATCU_Lib_MngrDEFBuf0 : 0|3@1+ (1,0) [0|7] ""  L_ATCU_vMON
 SG_ L_ATCU_Lib_MngrACBuf0 : 11|4@1+ (1,0) [0|15] ""  L_ATCU_vMON
 SG_ L_ATCU_Lib_MngrACBuf1 : 16|4@1+ (1,0) [0|15] ""  L_ATCU_vMON
 SG_ L_ATCU_Lib_MngrACBuf2 : 20|4@1+ (1,0) [0|15] ""  L_ATCU_vMON
 SG_ L_ATCU_Lib_MngrACBuf3 : 24|4@1+ (1,0) [0|15] ""  L_ATCU_vMON
 SG_ L_ATCU_Lib_MngrACBuf4 : 28|4@1+ (1,0) [0|15] ""  L_ATCU_vMON
 SG_ L_ATCU_Lib_MngrDEFBuf1 : 3|3@1+ (1,0) [0|7] ""  L_ATCU_vMON
 SG_ L_ATCU_Lib_MngrACBuf5 : 32|4@1+ (1,0) [0|15] ""  L_ATCU_vMON
 SG_ L_ATCU_Lib_MngrACBuf6 : 36|4@1+ (1,0) [0|15] ""  L_ATCU_vMON
 SG_ L_ATCU_Lib_MngrACBuf7 : 40|4@1+ (1,0) [0|15] ""  L_ATCU_vMON
 SG_ L_ATCU_Lib_MngrDEFBufLow1 : 44|2@1+ (1,0) [0|3] ""  L_ATCU_vMON
 SG_ L_ATCU_Lib_MngrTempBufLow1 : 48|2@1+ (1,0) [0|3] ""  L_ATCU_vMON
 SG_ L_ATCU_Lib_MngrTempBufLow0 : 50|2@1+ (1,0) [0|3] ""  L_ATCU_vMON
 SG_ L_ATCU_Lib_MngrIntakeBufHi0 : 52|2@1+ (1,0) [0|3] ""  L_ATCU_vMON
 SG_ L_ATCU_Lib_MngrIntakeBufHi1 : 54|2@1+ (1,0) [0|3] ""  L_ATCU_vMON
 SG_ L_ATCU_Lib_MngrIntakeBufLow2 : 56|2@1+ (1,0) [0|3] ""  L_ATCU_vMON
 SG_ L_ATCU_Lib_MngrDEFBufLow0 : 6|2@1+ (1,0) [0|3] ""  L_ATCU_vMON
 SG_ L_ATCU_Lib_MngrDEFBuf2 : 8|3@1+ (1,0) [0|7] ""  L_ATCU_vMON

CM_ BO_ 864 "[PE] Periodic and On Event";
CM_ SG_ 864 L_ATCU_Lib_MngrDEFBuf0 "ATCU Library DEF Manager Buffer 0";
CM_ SG_ 864 L_ATCU_Lib_MngrACBuf0 "ATCU Library AC Manager Buffer 0";
CM_ SG_ 864 L_ATCU_Lib_MngrACBuf1 "ATCU Library AC Manager Buffer 1";
CM_ SG_ 864 L_ATCU_Lib_MngrACBuf2 "ATCU Library AC Manager Buffer 2";
CM_ SG_ 864 L_ATCU_Lib_MngrACBuf3 "ATCU Library AC Manager Buffer 3";
CM_ SG_ 864 L_ATCU_Lib_MngrACBuf4 "ATCU Library AC Manager Buffer 4";
CM_ SG_ 864 L_ATCU_Lib_MngrDEFBuf1 "ATCU Library DEF Manager Buffer 1";
CM_ SG_ 864 L_ATCU_Lib_MngrACBuf5 "ATCU Library AC Manager Buffer 5";
CM_ SG_ 864 L_ATCU_Lib_MngrACBuf6 "ATCU Library AC Manager Buffer 6";
CM_ SG_ 864 L_ATCU_Lib_MngrACBuf7 "ATCU Library AC Manager Buffer 7";
CM_ SG_ 864 L_ATCU_Lib_MngrDEFBufLow1 "ATCU Library DEF Manager Lower Limit Buffer 1";
CM_ SG_ 864 L_ATCU_Lib_MngrTempBufLow1 "ATCU Library Temp Manager Lower Limit Buffer 1";
CM_ SG_ 864 L_ATCU_Lib_MngrTempBufLow0 "ATCU Library Temp Manager Lower Limit Buffer 0";
CM_ SG_ 864 L_ATCU_Lib_MngrIntakeBufHi0 "ATCU Library Intake Manager Upper Limit Buffer 0";
CM_ SG_ 864 L_ATCU_Lib_MngrIntakeBufHi1 "ATCU Library Intake Manager Upper Limit Buffer 1";
CM_ SG_ 864 L_ATCU_Lib_MngrIntakeBufLow2 "ATCU Library Intake Manager Lower Limit Buffer 2";
CM_ SG_ 864 L_ATCU_Lib_MngrDEFBufLow0 "ATCU Library DEF Manager Lower Limit Buffer 0";
CM_ SG_ 864 L_ATCU_Lib_MngrDEFBuf2 "ATCU Library DEF Manager Buffer 2";
CM_ BO_ 880 "[PE] Periodic and On Event";
CM_ SG_ 880 L_ATCU_Lib_StatMngr_2ndSafetynCool "ATCU StateManagement Control Data (2ndSafetynCool)";
CM_ BO_ 881 "[PE] Periodic and On Event";
CM_ SG_ 881 L_ATCU_Lib_StatMngr_2ndMngr "ATCU StateManagement Control Data (2ndMngr)";
CM_ BO_ 882 "[PE] Periodic and On Event";
CM_ SG_ 882 L_ATCU_Lib_StatMngr_2ndConvenience "ATCU StateManagement Control Data (2ndConvenience)";
CM_ BO_ 883 "[PE] Periodic and On Event";
CM_ SG_ 883 L_ATCU_Lib_StatMngr_2ndAirQuality "ATCU StateManagement Control Data (2ndAirQuality)";
CM_ BO_ 884 "[PE] Periodic and On Event";
CM_ SG_ 884 L_ATCU_Lib_StatMngr_2ndETC "ATCU StateManagement Control Data (2ndETC)";
CM_ BO_ 885 "[PE] Periodic and On Event";
CM_ SG_ 885 L_ATCU_Lib_StatMngr_2ndFuelEfficiency "ATCU StateManagement Control Data (2ndFuelEfficiency)";
CM_ BO_ 886 "[PE] Periodic and On Event";
CM_ SG_ 886 L_ATCU_Lib_MEM_ROMWriteCnt "ATCU Memory ROM Write Count Data";
CM_ BO_ 776 "[PE] Periodic and On Event";
CM_ SG_ 776 MON_AutoDrvModState "ATCU Monitoring Test mode AutoLogic:Mode";
CM_ SG_ 776 MON_AutoIntakeState "ATCU Monitoring Test mode AutoLogic:Intake";
CM_ SG_ 776 MON_AutoACState "ATCU Monitoring Test mode AutoLogic:AC";
CM_ SG_ 776 MON_AutoEvapTargetTemp "ATCU Monitoring Test mode AutoLogic:Evap Target Temp";
CM_ SG_ 776 MON_AutoBlrVtgVal "ATCU Monitoring Test mode AutoLogic:Blower Voltage";
CM_ BO_ 777 "[PE] Periodic and On Event";
CM_ SG_ 777 MON_AutoAstTargetTempVal "ATCU Monitoring Test mode AutoLogic:Assistside Target Temp";
CM_ SG_ 777 MON_AutoAstTempDrState "ATCU Monitoring Test mode AutoLogic:Assistside Temp Door";
CM_ SG_ 777 MON_AutoDrvTargetTempVal "ATCU Monitoring Test mode AutoLogic:Driverside Target Temp";
CM_ SG_ 777 MON_AutoDrvTempDrState "ATCU Monitoring Test mode AutoLogic:Driverside Temp Door";
CM_ BO_ 1025 "[PE] Periodic and On Event";
CM_ SG_ 1025 L_EVNT_HU_FrDrEVntSidePtDisp_X "Front Driver Electric Vent Side Touch Point  X Value Display Feedback";
CM_ SG_ 1025 L_EVNT_HU_FrDrEVntSidePtDisp_Y "Front Driver Electric Vent Side Touch Point  Y Value Display Feedback";
CM_ SG_ 1025 L_EVNT_HU_FrDrEVntCtrPtDisp_X "Front Driver Electric Vent Center Touch Point  X Value Display Feedback";
CM_ SG_ 1025 L_EVNT_HU_FrDrEVntCtrPtDisp_Y "Front Driver Electric Vent Center Touch Point  Y Value Display Feedback";
CM_ BO_ 1026 "[PE] Periodic and On Event";
CM_ SG_ 1026 L_EVNT_HU_FrPsEVntSidePtDisp_X "Front Passenger Electric Vent Side Touch Point  X Value Display Feedback";
CM_ SG_ 1026 L_EVNT_HU_FrPsEVntSidePtDisp_Y "Front Passenger Electric Vent Side Touch Point  Y Value Display Feedback";
CM_ SG_ 1026 L_EVNT_HU_FrPsEVntCtrPtDisp_X "Front Passenger Electric Center Vent Touch Point  X Value Display Feedback";
CM_ SG_ 1026 L_EVNT_HU_FrPsEVntCtrPtDisp_Y "Front Passenger Electric Center Vent Touch Point  Y Value Display Feedback";
CM_ BO_ 1027 "[PE] Periodic and On Event";
CM_ SG_ 1027 L_EVNT_HU_RrDrEVntConsPtDisp_X "Rear Driver Electric Vent Console Touch Point  X Value Display Feedback";
CM_ SG_ 1027 L_EVNT_HU_RrDrEVntConsPtDisp_Y "Rear Driver Electric Vent Console Touch Point  Y Value Display Feedback";
CM_ SG_ 1027 L_EVNT_HU_RrPsEVntConsPtDisp_X "Rear Passenger Electric Vent Console Touch Point  X Value Display Feedback";
CM_ SG_ 1027 L_EVNT_HU_RrPsEVntConsPtDisp_Y "Rear Passenger Electric Vent Console Touch Point  Y Value Display Feedback";
CM_ SG_ 1027 L_EVNT_FrDrEVntSideFlt "Front Driver Electric Vent Side Fault Status";
CM_ SG_ 1027 L_EVNT_FrDrEVntCtrFlt "Front Driver Electric Vent Center Fault Status";
CM_ SG_ 1027 L_EVNT_FrPsEVntSideFlt "Front Passenger Electric Vent Side Fault Status";
CM_ SG_ 1027 L_EVNT_FrPsEVntCtrFlt "Front Passenger Electric Vent Center Fault Status";
CM_ SG_ 1027 L_EVNT_RrDrEVntConsFlt "Front Rear (2nd) Driver Electric Vent Console Fault Status";
CM_ SG_ 1027 L_EVNT_RrPsEVntConsFlt "Front Rear (2nd) Passenger Electric Vent Console Fault Status";
CM_ BO_ 1028 "[PE] Periodic and On Event";
CM_ SG_ 1028 L_EVNT_FrDrEVntModeSet_Disp "Front Driver Electric Vent Mode Display";
CM_ SG_ 1028 L_EVNT_RrPsEVntModeSet_Disp "Rear Passenger Electric Vent Mode Display";
CM_ SG_ 1028 L_EVNT_FrDrEVntSideOpnClsDisp "Front Driver Electric Vent Side Open Close Display";
CM_ SG_ 1028 L_EVNT_FrDrEVntCtrOpnClsDisp "Front Driver Electric Vent Center Open Close Display";
CM_ SG_ 1028 L_EVNT_FrPsEVntSideOpnClsDisp "Front Passenger Electric Vent Side Open Close Display";
CM_ SG_ 1028 L_EVNT_FrPsEVntCtrOpnClsDisp "Front Passenger Electric Vent Center Open Close Display";
CM_ SG_ 1028 L_EVNT_RrDrEVntConsOpnClsDisp "Rear Driver Electric Vent Console Open Close Display";
CM_ SG_ 1028 L_EVNT_RrPsEVntConsOpnClsDisp "Rear Passenger Electric Vent Open Console Close Display";
CM_ SG_ 1028 L_EVNT_EVntTouchInform_HU "Reply signal indicating whether to allow duplicate input signals for preventing overlapping of electric vent input signals";
CM_ SG_ 1028 L_EVNT_EVntTouchInform_CTS "Reply signal indicating whether to allow duplicate input signals for preventing overlapping of electric vent input signals";
CM_ SG_ 1028 L_EVNT_FrtEvntFocusLvlSta "status setting of front Electric Vent focus mode height level";
CM_ SG_ 1028 L_EVNT_RrEvntFocusLvlSta "status feedback of Rear Electric Vent focus mode height level";
CM_ SG_ 1028 L_EVNT_DrVntOpt "L_EVNT_DriverVentOption";
CM_ SG_ 1028 L_EVNT_FrPsEVntModeSet_Disp "Front Passenger Electric Vent Mode Display";
CM_ SG_ 1028 L_EVNT_AstVntOpt "L_EVNT_AssistVentOption";
CM_ SG_ 1028 L_EVNT_RrDrVntOpt "L_EVNT_RearDriverVentOption";
CM_ SG_ 1028 L_EVNT_RrAstVntOpt "L_EVNT_RearAssistVentOption";
CM_ SG_ 1028 L_EVNT_EVntAutoAirFlowHotKeyOpt "L_EVNT_EVntAutoAirFlowHotKeyOpt";
CM_ SG_ 1028 L_EVNT_RrDrEVntModeSet_Disp "Rear Driver Electric Vent Mode Display";
CM_ BO_ 1029 "[PE] Periodic and On Event";
CM_ SG_ 1029 L_EVNT_CTS_FrDrEVntSidePtDisp_X "Front Driver Electric Vent Side Touch Point  X Value Display Feedback";
CM_ SG_ 1029 L_EVNT_CTS_FrDrEVntSidePtDisp_Y "Front Driver Electric Vent Side Touch Point  Y Value Display Feedback";
CM_ SG_ 1029 L_EVNT_CTS_FrDrEVntCtrPtDisp_X "Front Driver Electric Vent Center Touch Point  X Value Display Feedback";
CM_ SG_ 1029 L_EVNT_CTS_FrDrEVntCtrPtDisp_Y "Front Driver Electric Vent Center Touch Point  Y Value Display Feedback";
CM_ BO_ 1030 "[PE] Periodic and On Event";
CM_ SG_ 1030 L_EVNT_CTS_FrPsEVntSidePtDisp_X "Front Passenger Electric Vent Side Touch Point  X Value Display Feedback";
CM_ SG_ 1030 L_EVNT_CTS_FrPsEVntSidePtDisp_Y "Front Passenger Electric Vent Side Touch Point  Y Value Display Feedback";
CM_ SG_ 1030 L_EVNT_CTS_FrPsEVntCtrPtDisp_X "Front Passenger Electric Center Vent Touch Point  X Value Display Feedback";
CM_ SG_ 1030 L_EVNT_CTS_FrPsEVntCtrPtDisp_Y "Front Passenger Electric Center Vent Touch Point  Y Value Display Feedback";
CM_ BO_ 1031 "[PE] Periodic and On Event";
CM_ SG_ 1031 L_EVNT_CTS_RrDrEVntConsPtDisp_X "Rear Driver Electric Vent Console Touch Point  X Value Display Feedback";
CM_ SG_ 1031 L_EVNT_CTS_RrDrEVntConsPtDisp_Y "Rear Driver Electric Vent Console Touch Point  Y Value Display Feedback";
CM_ SG_ 1031 L_EVNT_CTS_RrPsEVntConsPtDisp_X "Rear Passenger Electric Vent Console Touch Point  X Value Display Feedback";
CM_ SG_ 1031 L_EVNT_CTS_RrPsEVntConsPtDisp_Y "Rear Passenger Electric Vent Console Touch Point  Y Value Display Feedback";
CM_ BO_ 1032 "[PE] Periodic and On Event";
CM_ SG_ 1032 L_EVNT_ATCUComFlt "ATCU fault decision of EVNT";
CM_ SG_ 1032 L_EVNT_DrvCntrHorComFlt "LIN-Bus Off DrvierCenter Left/Right - Actuator";
CM_ SG_ 1032 L_EVNT_AstSdVertComFlt "LIN-Bus Off PassengerSide Up/Down -Actuator";
CM_ SG_ 1032 L_EVNT_AstSdHorComFlt "LIN-Bus Off PassengerSide Left/Right - Actuator";
CM_ SG_ 1032 L_EVNT_AstCntrVertComFlt "LIN-Bus Off PassengerCenter Up/Down - Actuator";
CM_ SG_ 1032 L_EVNT_AstCntrHorComFlt "LIN-Bus Off PassengerCenter Left/Right - Actuator";
CM_ SG_ 1032 L_EVNT_EVNTFlt "EVNT fault decision of ATCU";
CM_ SG_ 1032 L_EVNT_RrDrvCnslVertComFlt "LIN-Bus Off RearDrvierCenter Up/Down -Actuator";
CM_ SG_ 1032 L_EVNT_RrDrvCnslHorComFlt "LIN-Bus Off RearDrvierCenter Left/Right -Actuator";
CM_ SG_ 1032 L_EVNT_RrAstCnslVertComFlt "LIN-Bus Off RearPassengerCenter Up/Down -Actuator";
CM_ SG_ 1032 L_EVNT_RrAstCnslHorComFlt "LIN-Bus Off RearPassengerCenter Left/Right -Actuator";
CM_ SG_ 1032 L_EVNT_DrvSdVertIntFlt "DrvierSide Up/Down - Actuator(Internal Error Flag)";
CM_ SG_ 1032 L_EVNT_DrvSdHorIntFlt "DrvierSide Left/Right -Actuator(Internal Error Flag)";
CM_ SG_ 1032 L_EVNT_DrvCntrVertIntFlt "DrvierCenter Up/Down -Actuator(Internal Error Flag)";
CM_ SG_ 1032 L_EVNT_DrvCntrHorIntFlt "DrvierCenter Left/Right - Actuator(Internal Error Flag)";
CM_ SG_ 1032 L_EVNT_AstSdVertIntFlt "PassengerSide Up/Down -Actuator(Internal Error Flag)";
CM_ SG_ 1032 L_EVNT_AstSdHorIntFlt "PassengerSide Left/Right - Actuator(Internal Error Flag)";
CM_ SG_ 1032 L_EVNT_DrvSdVertComFlt "LIN-Bus Off DrvierSide Up/Down - Actuator";
CM_ SG_ 1032 L_EVNT_AstCntrVertIntFlt "PassengerCenter Up/Down - Actuator(Internal Error Flag)";
CM_ SG_ 1032 L_EVNT_AstCntrHorIntFlt "PassengerCenter Left/Right - Actuator(Internal Error Flag)";
CM_ SG_ 1032 L_EVNT_RrDrvCnslVertIntFlt "RearDrvierCenter Up/Down -Actuator(Internal Error Flag)";
CM_ SG_ 1032 L_EVNT_RrDrvCnslHorIntFlt "RearDrvierCenter Left/Right -Actuator(Internal Error Flag)";
CM_ SG_ 1032 L_EVNT_RrAstCnslVertIntFlt "RearPassengerCenter Up/Down -Actuator(Internal Error Flag)";
CM_ SG_ 1032 L_EVNT_RrAstCnslHorIntFlt "RearPassengerCenter Left/Right -Actuator(Internal Error Flag)";
CM_ SG_ 1032 L_EVNT_DrvSdVertExtFlt "DrvierSide Up/Down - Actuator(External Error Flag)";
CM_ SG_ 1032 L_EVNT_DrvSdHorExtFlt "DrvierSide Left/Right -Actuator(External Error Flag)";
CM_ SG_ 1032 L_EVNT_DrvCntrVertExtFlt "DrvierCenter Up/Down -Actuator(External Error Flag)";
CM_ SG_ 1032 L_EVNT_DrvCntrHorExtFlt "DrvierCenter Left/Right - Actuator(External Error Flag)";
CM_ SG_ 1032 L_EVNT_DrvSdHorComFlt "LIN-Bus Off DrvierSide Left/Right -Actuator";
CM_ SG_ 1032 L_EVNT_AstSdVertExtFlt "PassengerSide Up/Down -Actuator(External Error Flag)";
CM_ SG_ 1032 L_EVNT_AstSdHorExtFlt "PassengerSide Left/Right - Actuator(External Error Flag)";
CM_ SG_ 1032 L_EVNT_DrvCntrVertComFlt "LIN-Bus Off DrvierCenter Up/Down -Actuator";
CM_ BO_ 1033 "[PE] Periodic and On Event";
CM_ SG_ 1033 L_EVNT_AstCntrVertExtFlt "PassengerCenter Up/Down - Actuator(External Error Flag)";
CM_ SG_ 1033 L_EVNT_RrAstCnslHorExtFlt "RearPassengerCenter Left/Right -Actuator(External Error Flag)";
CM_ SG_ 1033 L_EVNT_AstCntrHorExtFlt "PassengerCenter Left/Right - Actuator(External Error Flag)";
CM_ SG_ 1033 L_EVNT_AllResetOpSta "This signal indicates whether the reset operation has been completed or not";
CM_ SG_ 1033 L_EVNT_DrvSdVertResetOpSta "This signal indicates whether the reset operation has been completed or not";
CM_ SG_ 1033 L_EVNT_RrDrvCnslVertExtFlt "RearDrvierCenter Up/Down -Actuator(External Error Flag)";
CM_ SG_ 1033 L_EVNT_DrvSdHorResetOpSta "This signal indicates whether the reset operation has been completed or not";
CM_ SG_ 1033 L_EVNT_DrvCntrVertResetOpSta "This signal indicates whether the reset operation has been completed or not";
CM_ SG_ 1033 L_EVNT_DrvCntrHorResetOpSta "This signal indicates whether the reset operation has been completed or not";
CM_ SG_ 1033 L_EVNT_AstSdVertResetOpSta "This signal indicates whether the reset operation has been completed or not";
CM_ SG_ 1033 L_EVNT_AstSdHorResetOpSta "This signal indicates whether the reset operation has been completed or not";
CM_ SG_ 1033 L_EVNT_AstCntrVertResetOpSta "This signal indicates whether the reset operation has been completed or not";
CM_ SG_ 1033 L_EVNT_AstCntrHorResetOpSta "This signal indicates whether the reset operation has been completed or not";
CM_ SG_ 1033 L_EVNT_RrDrvCnslVertResetOpSta "This signal indicates whether the reset operation has been completed or not";
CM_ SG_ 1033 L_EVNT_RrDrvCnslHorResetOpSta "This signal indicates whether the reset operation has been completed or not";
CM_ SG_ 1033 L_EVNT_RrAstCnslVertResetOpSta "This signal indicates whether the reset operation has been completed or not";
CM_ SG_ 1033 L_EVNT_RrDrvCnslHorExtFlt "RearDrvierCenter Left/Right -Actuator(External Error Flag)";
CM_ SG_ 1033 L_EVNT_RrAstCnslHorResetOpSta "This signal indicates whether the reset operation has been completed or not";
CM_ SG_ 1033 L_EVNT_ResetOpSta "This signal indicates whether the reset operation has been completed or not";
CM_ SG_ 1033 L_EVNT_RrAstCnslVertExtFlt "RearPassengerCenter Up/Down -Actuator(External Error Flag)";
CM_ BO_ 326 "[P] Periodic";
CM_ SG_ 326 FHPTC_2ndPsRdySta "FHPTC_2ndPassengerReadyStatus";
CM_ SG_ 326 FHPTC_2ndPsOpSta "FHPTC_2ndPassengerOperationStatus";
CM_ SG_ 326 FHPTC_2ndPsCnsmptPwr_W "FHPTC_2ndPassengerConsumptionPower_W";
CM_ SG_ 326 FHPTC_2ndPsCtrlTyp "FHPTC_2ndPassengerControlType";
CM_ SG_ 326 FHPTC_2ndPsVoltage_V "FHPTC_2ndPassengerVoltage_V";
CM_ SG_ 326 FHPTC_2ndPsCurrent_A "FHPTC_2ndPassengerCurrent_A";
CM_ SG_ 326 FHPTC_2ndPsDutyFB_Pec "FHPTC_2ndPassengerDutyFB_Percentile";
CM_ SG_ 326 FHPTC_2ndPsDutyFB_IGBT "FHPTC_2ndPassengerDutyFeedBack_IGBT";
CM_ SG_ 326 FHPTC_2ndPsCoreTemp_C "FHPTC_2ndPassengerCoreTemp_C";
CM_ BO_ 65 "[PE] Periodic and On Event";
CM_ SG_ 65 HKBD_Typ1 "HKBD_Type1";
CM_ SG_ 65 HKBD_Typ2 "HKBD_Type2";
CM_ SG_ 65 HKBD_Typ3 "HKBD_Type3";
CM_ SG_ 65 HKBD_SW_Ver1 "HKBD_SoftWare_Version1";
CM_ SG_ 65 HKBD_SW_Ver2 "HKBD_SoftWare_Version2";
CM_ SG_ 65 HKBD_SW_Ver3 "HKBD_SoftWare_Version3";
CM_ BO_ 66 "[PE] Periodic and On Event";
CM_ SG_ 66 HKBD_Fr_DrModDnSw "HKBD_Front_DriverModeDownSwitch";
CM_ SG_ 66 HKBD_Fr_DrModUpSw "HKBD_Front_DriverModeUpSwitch";
CM_ SG_ 66 HKBD_Fr_DrMultiAutoSw "HKBD_Front_DriverMultiAutoSiwtch";
CM_ SG_ 66 HKBD_Fr_PsAutoSw "HKBD_Front_PassengerAutoSwitch";
CM_ SG_ 66 HKBD_Fr_PsMultiAutoSw "HKBD_Front_PassengerMultiAutoSwitch";
CM_ SG_ 66 HKBD_Fr_AcSw "HKBD_Front_ACSwitch";
CM_ SG_ 66 HKBD_Fr_DefSw "HKBD_Front_DEFSwitch";
CM_ SG_ 66 HKBD_Fr_RecSw "HKBD_Front_RecirculationSwitch";
CM_ SG_ 66 HKBD_Fr_DrModVntSw "HKBD_Front_DriverModeVentSwitch";
CM_ SG_ 66 HKBD_Fr_FreSw "HKBD_Front_FreshSwitch";
CM_ SG_ 66 HKBD_Fr_IntakeTglSw "HKBD_Front_IntakeToggleSwitch";
CM_ SG_ 66 HKBD_Fr_OffSw "HKBD_Front_OffSwitch";
CM_ SG_ 66 HKBD_Fr_SyncSw "HKBD_Front_SyncSwitch";
CM_ SG_ 66 HKBD_Fr_RrDefInd "HKBD_Front_RearDEFIndicator";
CM_ SG_ 66 HKBD_Fr_RrDefSw "HKBD_Front_RearDEFSwitch";
CM_ SG_ 66 HKBD_Fr_ArclnSw "HKBD_Front_AirCleaningIndicatorSwitch";
CM_ SG_ 66 HKBD_Fr_DrOnlySw "HKBD_Front_DriverOnlySwitch";
CM_ SG_ 66 HKBD_Fr_ClimateSw "HKBD_Front_ClimateSwitch";
CM_ SG_ 66 HKBD_Fr_PerfumeSw "HKBD_Front_PerfumeSwitch";
CM_ SG_ 66 HKBD_Fr_DrModFlrSw "HKBD_Front_DriverModeFloorSwitch";
CM_ SG_ 66 HKBD_Fr_HptIntnstySta "HKBD_Front_HapticIntensityState";
CM_ SG_ 66 HKBD_Fr_StrWhlHeatSw "HKBD_Front_SteeringWheelHeatSwitch";
CM_ SG_ 66 HKBD_FLStHeatSw "HKBD_FrontLeftSeatHeatSwitch";
CM_ SG_ 66 HKBD_FLStVentSw "HKBD_FrontLeftSeatVentSwitch";
CM_ SG_ 66 HKBD_FRStHeatSw "HBKD_FrontRightSeatHeatSwitch";
CM_ SG_ 66 HKBD_FRStVentSw "HKBD_FrontRightSeatVentSwitch";
CM_ SG_ 66 HKBD_FLStTumblrSw "HKBD_FrontLeftSeatTumblerSwitch";
CM_ SG_ 66 HKBD_Fr_DrModDefSw "HKBD_Front_DriverModeDEFSwitch";
CM_ SG_ 66 HKBD_FRStTumblrSw "HKBD_FrontRightSeatTumblerSwitch";
CM_ SG_ 66 HKBD_Fr_FrWndShldHtSw "HKBD_Front_FrontWindShieldHeatSwitch";
CM_ SG_ 66 HKBD_Fr_DrAutoDnSw "HKBD_Front_DriverAutoDownSwitch";
CM_ SG_ 66 HKBD_Fr_DrAutoUpSw "HKBD_Front_DriverAutoUpSwitch";
CM_ SG_ 66 HKBD_Fr_DrModSw "HKBD_Front_DriverModeSwitch";
CM_ SG_ 66 HKBD_Fr_PsModSw "HKBD_Front_PassengerModeSwitch";
CM_ SG_ 66 HKBD_DisplayTheme "HKBD_DisplayTheme (Black/White)";
CM_ SG_ 66 HKBD_Fr_PsModDnSw "HKBD_Front_PassengerModeDownSwitch";
CM_ SG_ 66 HKBD_Fr_SmartZoneSW "HKBD_Fr_SmartZoneSwitch";
CM_ SG_ 66 HKBD_Fr_ModSet "HKBD_Front_ModeSet";
CM_ SG_ 66 HKBD_Fr_MTCTempLvlSet "HKBD_Front_MTCTempLevelSet";
CM_ SG_ 66 HKBD_Fr_PsModUpSw "HKBD_Front_PassengerModeUpSwitch";
CM_ SG_ 66 HKBD_Fr_PsModVntSw "HKBD_Front_PassengerModeVentSwitch";
CM_ SG_ 66 HKBD_Fr_PsModFlrSw "HKBD_Front_PasengerModeFloorSwitch";
CM_ SG_ 66 HKBD_Fr_DrAutoSw "HKBD_Front_DriverAutoSwitch";
CM_ BO_ 67 "[EC] On Event and On Change";
CM_ SG_ 67 HKBD_Fr_DrTempClickCnt "HKBD_Front_DriverTemperatureClickCount";
CM_ SG_ 67 HKBD_Fr_RrTempClickCnt "HKBD_Front_RearTemperatureClickCount";
CM_ SG_ 67 HKBD_Fr_DrBlwClickCnt "HKBD_Front_DriverBlowerClickCount";
CM_ SG_ 67 HKBD_Fr_PsBlwClickCnt "HKBD_Front_PassengerBlowerClickCount";
CM_ SG_ 67 HKBD_FrTempKnobCnt "HKBD_FrontTempKnobCount (for knobs rotate count)";
CM_ SG_ 67 HKBD_FrBlwKnobCnt "HKBD_FrontBlowerKnobCount (for knobs rotate count)";
CM_ SG_ 67 HKBD_Fr_PsTempClickCnt "HKBD_Front_PassengerTemperatureClickCount";
CM_ BO_ 68 "[PE] Periodic and On Event";
CM_ SG_ 68 HKBD_Fr_DrTempDnSw "HKBD_Front_DriverTemperatureDownSwitch";
CM_ SG_ 68 HKBD_Fr_DrTempUpSw "HKBD_Front_DriverTemperatureUpSwitch";
CM_ SG_ 68 HKBD_Fr_PsBlwDnSw "HKBD_Front_PassengerBlowerDownSwitch";
CM_ SG_ 68 HKBD_Fr_PsBlwDnOffSw "HKBD_Front_PasengerBlowerDownOffSwitch";
CM_ SG_ 68 HKBD_Fr_PsBlwUpSw "HKBD_Front_PassengerBlowerUpSwitch";
CM_ SG_ 68 HKBD_Fr_PsBlwSet "HKBD_Front_PassengerBlowerSet";
CM_ SG_ 68 HKBD_Fr_RrDrTempDnSw "HKBD_Front_RearDriverTemperatureDownSwitch";
CM_ SG_ 68 HKBD_Fr_RrDrTempUpSw "HKBD_Front_RearDriverTemperatureUpSwitch";
CM_ SG_ 68 HKBD_Fr_PsTempDnSw "HKBD_Front_PassengerTemperatureDownSwitch";
CM_ SG_ 68 HKBD_Fr_RrDrBlwDnSw "HKBD_Front_RearDriverBlowerDownSwitch";
CM_ SG_ 68 HKBD_Fr_RrDrBlwDnOffSw "HKBD_Front_RearDriverBlowerDownOffSwitch";
CM_ SG_ 68 HKBD_Fr_RrDrBlwUpSw "HKBD_Front_RearDriverBlowerUpSwitch";
CM_ SG_ 68 HKBD_Fr_RrDrBlwSet "HKBD_Front_RearDriverBlowerSet";
CM_ SG_ 68 HKBD_Fr_RrDrModDnSw "HKBD_Front_RearDriverModeDownSiwtch";
CM_ SG_ 68 HKBD_Fr_RrDrModUpSw "HKBD_Front_RearDriverModeUpSwitch";
CM_ SG_ 68 HKBD_Fr_RrDrModVntSw "HKBD_Front_RearDriverModeVentSwitch";
CM_ SG_ 68 HKBD_Fr_PsTempUpSw "HKBD_Front_PassengerTemperatureUpSwitch";
CM_ SG_ 68 HKBD_Fr_RrDrModFlrSw "HKBD_Front_RearDriverModeFloorSwitch";
CM_ SG_ 68 HKBD_Fr_RrDrModBiLvlSw "HKBD_Front_RearDriverModeBiLevelSwitch";
CM_ SG_ 68 HKBD_Fr_RrDrAutoSw "HKBD_Front_RearDriverAutoSwitch";
CM_ SG_ 68 HKBD_Fr_RrDrMultiAutoSw "HKBD_Front_RearDriverMultiAutoSwitch";
CM_ SG_ 68 HKBD_Fr_RrOffSw "HKBD_Front_RearOffSwitch";
CM_ SG_ 68 HKBD_Fr_RrSyncSw "HKBD_Front_RearSyncSwitch";
CM_ SG_ 68 HKBD_Fr_RLStHeatSw "HKBD_Front_RearLeftSeatHeatSwitch";
CM_ SG_ 68 HKBD_Fr_RLStVentSw "HKBD_Front_RearLeftSeatVentSwitch";
CM_ SG_ 68 HKBD_Fr_DrBlwDnSw "HKBD_Front_DriverBLowerDownSwitch";
CM_ SG_ 68 HKBD_Fr_RRStHeatSw "HKBD_Front_RearRightSeatHeatSwitch";
CM_ SG_ 68 HKBD_Fr_RRStVentSw "HKBD_Front_RearRightSeatVentSwitch";
CM_ SG_ 68 HKBD_Fr_RLStTumblrSw "HKBD_Front_RearLeftSeatTumblerSwitch";
CM_ SG_ 68 HKBD_Fr_RRStTumblrSw "HKBD_Front_RearRightSeatTumblerSwitch";
CM_ SG_ 68 HKBD_Fr_RrPsModDnSw "HKBD_Front_RearPassengerModeDownSwitch";
CM_ SG_ 68 HKBD_Fr_RrPsModUpSw "HKBD_Front_RearPassengerModeUpSwitch";
CM_ SG_ 68 HKBD_Fr_RrPsModVntSw "HKBD_Front_RearPassengerModeVentSwitch";
CM_ SG_ 68 HKBD_Fr_RrPsModFlrSw "HKBD_Front_RearPassengerModeFloorSwitch";
CM_ SG_ 68 HKBD_Fr_DrBlwDnOffSw "HKBD_Front_DriverBlowerDownOffSwitch";
CM_ SG_ 68 HKBD_Fr_RrLockSw "HKBD_Front_RearLockSwitch";
CM_ SG_ 68 HKBD_Fr_RrPsModBiLvlSw "HKBD_Front_RearPassengerrModeBiLevelSwitch";
CM_ SG_ 68 HKBD_Fr_RrDrModSw "HKBD_Front_RearDriverModeSwitch";
CM_ SG_ 68 HKBD_Fr_RrPsModSw "HKBD_Front_RearPassengerModeSwitch";
CM_ SG_ 68 HKBD_Fr_RrPsBlwSet "HKBD_Front_RearPassengerBlowerSet";
CM_ SG_ 68 HKBD_Fr_RrPsBlwUpSw "HKBD_Front_RearPassengerBlowerUpSwitch";
CM_ SG_ 68 HKBD_Fr_RrPsBlwDnSw "HKBD_Front_RearPassengerBlowerDownSwitch";
CM_ SG_ 68 HKBD_Fr_DrBlwUpSw "HKBD_Front_DriverBlowerUpSwitch";
CM_ SG_ 68 HKBD_Fr_RrPsBlwDnOffSw "HKBD_Front_RearPassengerBlowerDownOffSwitch";
CM_ SG_ 68 HKBD_Fr_RrPsTempDnSw "HKBD_Front_RearPassengerTemperatureDownSwitch";
CM_ SG_ 68 HKBD_Fr_RrPsTempUpSw "HKBD_Front_RearPassengerTemperatureUpSwitch";
CM_ SG_ 68 HKBD_Fr_DrBlwSet "HKBD_Front_DriverBlowerSet";
CM_ BO_ 69 "[PE] Periodic and On Event";
CM_ SG_ 69 HKBD_Fr_3rdRrTempDnSw "HKBD_Front_3rdRearTemperatureDownSwitch";
CM_ SG_ 69 HKBD_Fr_3rdRrTempUpSw "HKBD_Front_3rdRearTemperatureUpSwitch";
CM_ SG_ 69 HKBD_Fr_3rdRrModUpSw "HKBD_Front_3rdRearModeUpSwitch";
CM_ SG_ 69 HKBD_Fr_3rdRrModVntSw "HKBD_Front_3rdRearModeVentSwitch";
CM_ SG_ 69 HKBD_Fr_3rdRrModFlrSw "HKBD_Front_3rdRearModeFloorSwitch";
CM_ SG_ 69 HKBD_Fr_3rdRrAutoSw "HKBD_Front_3rdRearAutoSwitch";
CM_ SG_ 69 HKBD_Fr_3rdRrMultiAutoSw "HKBD_Front_3rdRearMultiAutoSwitch";
CM_ SG_ 69 HKBD_Fr_3rdRrOffSw "HKBD_Front_3rdRearOffSwitch";
CM_ SG_ 69 HKBD_Fr_3rdRrSyncSw "HKBD_Front_3rdRearSyncSwitch";
CM_ SG_ 69 HKBD_Fr_3rdRrLockSw "HKBD_Front_3rdRearLockSwitch";
CM_ SG_ 69 HKBD_Fr_3rdRrBlwDnSw "HKBD_Front_3rdRearBlowerDownSwitch";
CM_ SG_ 69 HKBD_Fr_3rdRrModBiLvlSw "HKBD_Front_3rdRearModeBiLevelSwitch";
CM_ SG_ 69 HKBD_FrRrTglSet "HKBD_FrontRearToggleSet";
CM_ SG_ 69 HKBD_Fr_RrScrnSet "HKBD_FrontRearScreenSet";
CM_ SG_ 69 HKBD_Fr_OnOffSet "HKBD_Front_OnOffSet";
CM_ SG_ 69 HKBD_Fr_RrOnOffSet "HKBD_Front_RearOnOffSet";
CM_ SG_ 69 HKBD_Fr_3rdRrOnOffSet "HKBD_Front_3rdRearOnOffSet";
CM_ SG_ 69 HKBD_Fr_3rdRrBlwDnOffSw "HKBD_Front_3rdRearBlowerDownOffSwitch";
CM_ SG_ 69 HKBD_Fr_RrPsAutoSw "HKBD_Front_RearPassengerAutoSwitch";
CM_ SG_ 69 HKBD_Fr_RrPsMultiAutoSw "HKBD_Front_RearPassengerMultiAutoSwitch";
CM_ SG_ 69 HKBD_Fr_3rdRrModSw "HKBD_Front_3rdRearModeSwitch";
CM_ SG_ 69 HKBD_Fr_RrModSet "HKBD_Front_ModeSet";
CM_ SG_ 69 HKBD_Fr_3rdRrBlwUpSw "HKBD_Front_3rdRearBlowerUpSwitch";
CM_ SG_ 69 HKBD_Fr_3rdModSet "HKBD_Front_ModeSet";
CM_ SG_ 69 HKBD_Fr_DrblwUpMaxSw "HKBD_Fr_DrblwUpMaxSw";
CM_ SG_ 69 HKBD_Fr_PsblwUpMaxSw "HKBD_Fr_PsblwUpMaxSw";
CM_ SG_ 69 HKBD_Fr_3rdRrBlwSet "HKBD_Front_3rdRearBlowerSet";
CM_ SG_ 69 HKBD_Fr_3rdRrModDnSw "HKBD_Front_3rdRearModeDownSwitch";
CM_ BO_ 70 "[PE] Periodic and On Event";
CM_ SG_ 70 HKBD_SwBtnTyp "HKBD_SwitchButtonType";
CM_ SG_ 70 L_HKBD_ResetOpSta "This signal indicates whether the reset operation has been completed or not";
CM_ BO_ 71 "[EC] On Event and On Change";
CM_ SG_ 71 HKBD_Fr_RrDrTempClickCnt "HKBD_Front_RearDriverTemperatureClickCount";
CM_ SG_ 71 HKBD_Fr_RrPsTempClickCnt "HKBD_Front_RearPassengerTemperatureClickCount";
CM_ SG_ 71 HKBD_Fr_RrPsBlwClickCnt "HKBD_Front_RearPassengerBlowerClickCount";
CM_ SG_ 71 HKBD_Fr_3rdRrTempClickCnt "HKBD_Front_3rdRearTepmperatureClickCount";
CM_ SG_ 71 HKBD_Fr_3rdRrBlwClickCnt "HKBD_Front_3rdRearBlowerClickCount";
CM_ SG_ 71 HKBD_Fr_RrTempKnobCnt "HKBD_Front_RearTemperatureKnobCount (for knobs rotate count)";
CM_ SG_ 71 HKBD_Fr_RrBlwKnobCnt "HKBD_Front_RearBlowerKnobCount (for knobs rotate count)";
CM_ SG_ 71 HKBD_Fr_3rdTempKnobCnt "HKBD_Front_3rdTemperatureKnobCount (for knobs rotate count)";
CM_ SG_ 71 HKBD_Fr_3rdBlwKnobCnt "HKBD_Front_3rdBlowerKnobCount (for knobs rotate count)";
CM_ SG_ 71 L_HKBD_HVACPnlBckLight_Res "Vehicle API HVAC Control Panel BackLight Response";
CM_ SG_ 71 HKBD_Fr_RrDrBlwClickCnt "HKBD_Front_RearDriverBlowerClickCount";
CM_ BO_ 72 "[P] Periodic";
CM_ SG_ 72 HKBD_Fr_IncarRaw "HKBD_Front_IncarSensorRawValue";
CM_ BO_ 336 "[P] Periodic";
CM_ SG_ 336 RHPTC_Zone1RdySta "RHPTC_Zone1ReadyStatus (Zone1 : Dr or Roof)";
CM_ SG_ 336 RHPTC_Zone1OpSta "RHPTC_Zone1OperationStatus (Zone1 : Dr or Roof)";
CM_ SG_ 336 RHPTC_Zone1CnsmptPwr_W "RHPTC_Zone1ConsumptionPower_W (Zone1 : Dr or Roof)";
CM_ SG_ 336 RHPTC_Zone1Voltage_V "RHPTC_Zone1Voltage_V (Zone1 : Dr or Roof)";
CM_ SG_ 336 RHPTC_Zone1CtrlTyp "RHPTC_Zone1ControlType (Zone1 : Dr or Roof)";
CM_ SG_ 336 RHPTC_Zone1Current_A "RHPTC_Zone1Current_A (Zone1 : Dr or Roof)";
CM_ SG_ 336 RHPTC_Zone1DutyFB_Pec "RHPTC_Zone1DutyFeedBack_Percentile (Zone1 : Dr or Roof)";
CM_ SG_ 336 RHPTC_Zone1DutyFB_IGBT "RHPTC_Zone1DutyFeedBack_IGBT (Zone1 : Dr or Roof)";
CM_ SG_ 336 RHPTC_Zone1CoreTemp_C "RHPTC_Zone1CoreTemp_C (Zone1 : Dr or Roof)";
CM_ BO_ 337 "[P] Periodic";
CM_ SG_ 337 RHPTC_Zone1Flt "RHPTC_Zone1Fault (Zone1 : Dr or Roof)";
CM_ SG_ 337 RHPTC_Zone1FltLVLow "RHPTC_Zone1FaultLVLow (Zone1 : Dr or Roof)";
CM_ SG_ 337 RHPTC_Zone1FailLVSnr "RHPTC_Zone1FailLowVoltageSensor (Zone1 : Dr or Roof)";
CM_ SG_ 337 RHPTC_Zone1FailCurrentSnr "RHPTC_Zone1FailCurrentSensor (Zone1 : Dr or Roof)";
CM_ SG_ 337 RHPTC_Zone1FailCoreTempSnr "RHPTC_Zone1FailCoreTempSensor (Zone1 : Dr or Roof)";
CM_ SG_ 337 RHPTC_Zone1FailPcbTempSnr "RHPTC_Zone1FailPcbTempSensor (Zone1 : Dr or Roof)";
CM_ SG_ 337 RHPTC_Zone1FailIGBT "RHPTC_Zone1FailIGBT (Zone1 : Dr or Roof)";
CM_ SG_ 337 RHPTC_Zone1FailOpenLoad "RHPTC_Zone1FailOpenLoad (Zone1 : Dr or Roof)";
CM_ SG_ 337 RHPTC_Zone1LtdOpCause "RHPTC_Zone1LtdOperationCauseFlag (Zone1 : Dr or Roof)";
CM_ SG_ 337 RHPTC_Zone1FltLVHigh "RHPTC_Zone1FaultLVHigh (Zone1 : Dr or Roof)";
CM_ SG_ 337 RHPTC_Zone1SwVer "RHPTC_Zone1SoftwareVer (Zone1 : Dr or Roof)";
CM_ SG_ 337 RHPTC_Zone1FltHVLow "RHPTC_Zone1FaultHVLow (Zone1 : Dr or Roof)";
CM_ SG_ 337 RHPTC_CnsmptPwrTtl_W "RHPTC_ConsumptionPowerTotal_W";
CM_ SG_ 337 RHPTC_Zone1FltHVHigh "RHPTC_Zone1FaultHVHigh (Zone1 : Dr or Roof)";
CM_ SG_ 337 RHPTC_IntlkSta "RHPTC_InterlockStatus";
CM_ SG_ 337 RHPTC_Zone1FltOverCurrent "RHPTC_Zone1FaultOverCurrent (Zone1 : Dr or Roof)";
CM_ SG_ 337 RHPTC_Zone1FltThermalShutDn "RHPTC_Zone1FltThermalShutDn (Zone1 : Dr or Roof)";
CM_ SG_ 337 RHPTC_Zone1FltPcbThermalShutDn "RHPTC_Zone1FltPcbThermalShutDn (Zone1 : Dr or Roof)";
CM_ SG_ 337 RHPTC_Zone1FltMsgTmOutATCU "RHPTC_Zone1FltMsgTmOutATCU (Zone1 : Dr or Roof)";
CM_ SG_ 337 RHPTC_Zone1FailHVSnr "RHPTC_Zone1FailHighVoltageSensor (Zone1 : Dr or Roof)";
CM_ BO_ 338 "[P] Periodic";
CM_ SG_ 338 RHPTC_Zone2RdySta "RHPTC_Zone2ReadyStatus (Zone2 : Ps or Floor) (Zone2 : Ps or Floor)";
CM_ SG_ 338 RHPTC_Zone2OpSta "RHPTC_Zone2OperationStatus (Zone2 : Ps or Floor)";
CM_ SG_ 338 RHPTC_Zone2CnsmptPwr_W "RHPTC_Zone2ConsumptionPower_W (Zone2 : Ps or Floor)";
CM_ SG_ 338 RHPTC_Zone2CtrlTyp "RHPTC_Zone2ControlType  (Zone2 : Ps or Floor)";
CM_ SG_ 338 RHPTC_Zone2Voltage_V "RHPTC_Zone2Voltage_V (Zone2 : Ps or Floor)";
CM_ SG_ 338 RHPTC_Zone2Current_A "RHPTC_Zone2Current_A (Zone2 : Ps or Floor)";
CM_ SG_ 338 RHPTC_Zone2DutyFB_Pec "RHPTC_Zone2DutyFeedBack_Percentile (Zone2 : Ps or Floor)";
CM_ SG_ 338 RHPTC_Zone2DutyFB_IGBT "RHPTC_Zone2DutyFeedBack_IGBT (Zone2 : Ps or Floor)";
CM_ SG_ 338 RHPTC_Zone2CoreTemp_C "RHPTC_Zone2CoreTemp_C (Zone2 : Ps or Floor)";
CM_ BO_ 339 "[P] Periodic";
CM_ SG_ 339 RHPTC_Zone2Flt "RHPTC_Zone2Fault (Zone2 : Ps or Floor)";
CM_ SG_ 339 RHPTC_Zone2FltLVLow "RHPTC_Zone2FaultLVLow (Zone2 : Ps or Floor)";
CM_ SG_ 339 RHPTC_Zone2FailLVSnr "RHPTC_Zone2FailLowVoltageSensor (Zone2 : Ps or Floor)";
CM_ SG_ 339 RHPTC_Zone2FailCurrentSnr "RHPTC_Zone2FailCurrentSensor (Zone2 : Ps or Floor)";
CM_ SG_ 339 RHPTC_Zone2FailCoreTempSnr "RHPTC_Zone2FailCoreTempSensor (Zone2 : Ps or Floor)";
CM_ SG_ 339 RHPTC_Zone2FailPcbTempSnr "RHPTC_Zone2FailPcbTempSensor (Zone2 : Ps or Floor)";
CM_ SG_ 339 RHPTC_Zone2FailIGBT "RHPTC_Zone2FailIGBT (Zone2 : Ps or Floor)";
CM_ SG_ 339 RHPTC_Zone2FailOpenLoad "RHPTC_Zone2FailOpenLoad (Zone2 : Ps or Floor)";
CM_ SG_ 339 RHPTC_Zone2LtdOpCause "RHPTC_Zone2LtdOperationCauseFlag (Zone2 : Ps or Floor)";
CM_ SG_ 339 RHPTC_Zone2FltLVHigh "RHPTC_Zone2FaultLVHigh (Zone2 : Ps or Floor)";
CM_ SG_ 339 RHPTC_Zone2SwrVer "RHPTC_Zone2SoftwareVer (Zone2 : Ps or Floor)";
CM_ SG_ 339 RHPTC_Zone2FltHVLow "RHPTC_Zone2FaultHVLow (Zone2 : Ps or Floor)";
CM_ SG_ 339 RHPTC_Zone2FltHVHigh "RHPTC_Zone2FaultHVHigh (Zone2 : Ps or Floor)";
CM_ SG_ 339 RHPTC_Zone2FltOverCurrent "RHPTC_Zone2FaultOverCurrent (Zone2 : Ps or Floor)";
CM_ SG_ 339 RHPTC_Zone2FltThermalShutDn "RHPTC_Zone2FltThermalShutDn (Zone2 : Ps or Floor)";
CM_ SG_ 339 RHPTC_Zone2FltPcbThermalShutDn "RHPTC_Zone2FltPcbThermalShutDn (Zone2 : Ps or Floor)";
CM_ SG_ 339 RHPTC_Zone2FltMsgTmOutATCU "RHPTC_Zone2FltMsgTmOutATCU (Zone2 : Ps or Floor)";
CM_ SG_ 339 RHPTC_Zone2FailHVSnr "RHPTC_Zone2FailHighVoltageSensor (Zone2 : Ps or Floor)";
BA_DEF_ BO_ "UsrMsgIDSforwardDeviation" INT 0 100 ;
BA_DEF_ BO_ "UsrMsgIDSbackwardDeviation" INT 50 1000 ;
BA_DEF_ BO_ "GenMsgCycleTime" INT 0 2000 ;
BA_DEF_ BO_ "GenMsgStartDelayTime" INT 0 2000 ;
BA_DEF_ BO_ "GenMsgSendType" ENUM "Cyclic","NoMsgSendType" ;
BA_DEF_ BO_ "GenMsgCycleTimeFast" INT 0 500 ;
BA_DEF_ BO_ "GenMsgDelayTime" INT 0 20 ;
BA_DEF_ BO_ "GenMsgILSupport" ENUM "No","Yes" ;
BA_DEF_ BO_ "GenMsgNrOfRepetition" INT 0 3 ;
BA_DEF_ BO_ "VFrameFormat" ENUM "StandardCAN","ExtendedCAN","reserved","reserved","reserved","reserved","reserved","reserved","reserved","reserved","reserved","reserved","reserved","reserved","StandardCAN_FD","ExtendedCAN_FD" ;
BA_DEF_ SG_ "UserSigValidity" ENUM "B+","ACC","IG","IG1","IG2","IG3","IG1 or IG2","IG1 or IG3","Undef" ;
BA_DEF_ SG_ "UsrSigPurpose" ENUM "Undef","FN","DIAG","DIAG(Req)","DIAG(Res)","DIAG(Phy)","DEV","CCP(Req)","CCP(Res)","NM","TP" ;
BA_DEF_ SG_ "GenSigStartValue" INT 0 1215752192 ;
BA_DEF_ SG_ "NetworkRequestHoldingTime" INT 0 65535 ;
BA_DEF_ SG_ "Description" STRING ;
BA_DEF_ SG_ "Version" STRING ;
BA_DEF_ SG_ "GenSigEnvVarType" ENUM "Int","Float","Undef" ;
BA_DEF_ SG_ "GenSigSendType" ENUM "Cyclic","OnWrite","OnWriteWithRepetition","OnChange","OnChangeWithRepetition","IfActive","IfActiveWithRepetition","NoSigSendType","OnChangeAndIfActive","OnChangeAndIfActiveWithRepetition" ;
BA_DEF_ SG_ "GwSigLatencyTime" INT 0 65536 ;
BA_DEF_ SG_ "GwSigMissingSourceType" ENUM "Undef","OldValue","DefaultValue","InitialValue" ;
BA_DEF_ SG_ "NWM-WakeupAllowed" ENUM "<n.a.>" ;
BA_DEF_ SG_ "RoutingFactor" INT 1 1215752192 ;
BA_DEF_REL_ BU_SG_REL_ "GenSigTimeoutTime" INT 0 7000 ;
BA_DEF_DEF_ "UsrMsgIDSforwardDeviation" 10 ;
BA_DEF_DEF_ "UsrMsgIDSbackwardDeviation" 100 ;
BA_DEF_DEF_ "GenMsgCycleTime" 200 ;
BA_DEF_DEF_ "GenMsgStartDelayTime" 0 ;
BA_DEF_DEF_ "GenMsgSendType" "NoMsgSendType" ;
BA_DEF_DEF_ "GenMsgCycleTimeFast" 40 ;
BA_DEF_DEF_ "GenMsgDelayTime" 20 ;
BA_DEF_DEF_ "GenMsgILSupport" "Yes" ;
BA_DEF_DEF_ "GenMsgNrOfRepetition" 3 ;
BA_DEF_DEF_ "VFrameFormat" "StandardCAN" ;
BA_DEF_DEF_ "UserSigValidity" "IG" ;
BA_DEF_DEF_ "UsrSigPurpose" "FN" ;
BA_DEF_DEF_ "GenSigStartValue" 0 ;
BA_DEF_DEF_ "NetworkRequestHoldingTime" 0 ;
BA_DEF_DEF_ "Description" "" ;
BA_DEF_DEF_ "Version" "" ;
BA_DEF_DEF_ "GenSigEnvVarType" "Undef" ;
BA_DEF_DEF_ "GenSigSendType" "NoSigSendType" ;
BA_DEF_DEF_ "GwSigLatencyTime" 40 ;
BA_DEF_DEF_ "GwSigMissingSourceType" "Undef" ;
BA_DEF_DEF_ "NWM-WakeupAllowed" "<n.a.>" ;
BA_DEF_DEF_ "RoutingFactor" 1 ;
BA_DEF_DEF_REL_ "GenSigTimeoutTime" 500 ;
BA_ "GenMsgSendType" BO_ 864 0;
BA_ "GenMsgCycleTime" BO_ 864 500;
BA_ "Description" SG_ 864 L_ATCU_Lib_MngrDEFBuf0 "This value only use for ATCU Library data monitoring (Only use before SOP)";
BA_ "GenSigSendType" SG_ 864 L_ATCU_Lib_MngrDEFBuf0 4;
BA_ "UserSigValidity" SG_ 864 L_ATCU_Lib_MngrDEFBuf0 0;
BA_REL_ "GenSigTimeoutTime" BU_SG_REL_ L_ATCU_vMON SG_ 864 L_ATCU_Lib_MngrDEFBuf0 5000;
BA_ "Version" SG_ 864 L_ATCU_Lib_MngrDEFBuf0 "23.11.10";
BA_ "Description" SG_ 864 L_ATCU_Lib_MngrACBuf0 "This value only use for ATCU Library data monitoring (Only use before SOP)";
BA_ "GenSigSendType" SG_ 864 L_ATCU_Lib_MngrACBuf0 4;
BA_ "UserSigValidity" SG_ 864 L_ATCU_Lib_MngrACBuf0 0;
BA_REL_ "GenSigTimeoutTime" BU_SG_REL_ L_ATCU_vMON SG_ 864 L_ATCU_Lib_MngrACBuf0 5000;
BA_ "Version" SG_ 864 L_ATCU_Lib_MngrACBuf0 "23.11.10";
BA_ "Description" SG_ 864 L_ATCU_Lib_MngrACBuf1 "This value only use for ATCU Library data monitoring (Only use before SOP)";
BA_ "GenSigSendType" SG_ 864 L_ATCU_Lib_MngrACBuf1 4;
BA_ "UserSigValidity" SG_ 864 L_ATCU_Lib_MngrACBuf1 0;
BA_REL_ "GenSigTimeoutTime" BU_SG_REL_ L_ATCU_vMON SG_ 864 L_ATCU_Lib_MngrACBuf1 5000;
BA_ "Version" SG_ 864 L_ATCU_Lib_MngrACBuf1 "23.11.10";
BA_ "Description" SG_ 864 L_ATCU_Lib_MngrACBuf2 "This value only use for ATCU Library data monitoring (Only use before SOP)";
BA_ "GenSigSendType" SG_ 864 L_ATCU_Lib_MngrACBuf2 4;
BA_ "UserSigValidity" SG_ 864 L_ATCU_Lib_MngrACBuf2 0;
BA_REL_ "GenSigTimeoutTime" BU_SG_REL_ L_ATCU_vMON SG_ 864 L_ATCU_Lib_MngrACBuf2 5000;
BA_ "Version" SG_ 864 L_ATCU_Lib_MngrACBuf2 "23.11.10";
BA_ "Description" SG_ 864 L_ATCU_Lib_MngrACBuf3 "This value only use for ATCU Library data monitoring (Only use before SOP)";
BA_ "GenSigSendType" SG_ 864 L_ATCU_Lib_MngrACBuf3 4;
BA_ "UserSigValidity" SG_ 864 L_ATCU_Lib_MngrACBuf3 0;
BA_REL_ "GenSigTimeoutTime" BU_SG_REL_ L_ATCU_vMON SG_ 864 L_ATCU_Lib_MngrACBuf3 5000;
BA_ "Version" SG_ 864 L_ATCU_Lib_MngrACBuf3 "23.11.10";
BA_ "Description" SG_ 864 L_ATCU_Lib_MngrACBuf4 "This value only use for ATCU Library data monitoring (Only use before SOP)";
BA_ "GenSigSendType" SG_ 864 L_ATCU_Lib_MngrACBuf4 4;
BA_ "UserSigValidity" SG_ 864 L_ATCU_Lib_MngrACBuf4 0;
BA_REL_ "GenSigTimeoutTime" BU_SG_REL_ L_ATCU_vMON SG_ 864 L_ATCU_Lib_MngrACBuf4 5000;
BA_ "Version" SG_ 864 L_ATCU_Lib_MngrACBuf4 "23.11.10";
BA_ "Description" SG_ 864 L_ATCU_Lib_MngrDEFBuf1 "This value only use for ATCU Library data monitoring (Only use before SOP)";
BA_ "GenSigSendType" SG_ 864 L_ATCU_Lib_MngrDEFBuf1 4;
BA_ "UserSigValidity" SG_ 864 L_ATCU_Lib_MngrDEFBuf1 0;
BA_REL_ "GenSigTimeoutTime" BU_SG_REL_ L_ATCU_vMON SG_ 864 L_ATCU_Lib_MngrDEFBuf1 5000;
BA_ "Version" SG_ 864 L_ATCU_Lib_MngrDEFBuf1 "23.11.10";
BA_ "Description" SG_ 864 L_ATCU_Lib_MngrACBuf5 "This value only use for ATCU Library data monitoring (Only use before SOP)";
BA_ "GenSigSendType" SG_ 864 L_ATCU_Lib_MngrACBuf5 4;
BA_ "UserSigValidity" SG_ 864 L_ATCU_Lib_MngrACBuf5 0;
BA_REL_ "GenSigTimeoutTime" BU_SG_REL_ L_ATCU_vMON SG_ 864 L_ATCU_Lib_MngrACBuf5 5000;
BA_ "Version" SG_ 864 L_ATCU_Lib_MngrACBuf5 "23.11.10";
BA_ "Description" SG_ 864 L_ATCU_Lib_MngrACBuf6 "This value only use for ATCU Library data monitoring (Only use before SOP)";
BA_ "GenSigSendType" SG_ 864 L_ATCU_Lib_MngrACBuf6 4;
BA_ "UserSigValidity" SG_ 864 L_ATCU_Lib_MngrACBuf6 0;
BA_REL_ "GenSigTimeoutTime" BU_SG_REL_ L_ATCU_vMON SG_ 864 L_ATCU_Lib_MngrACBuf6 5000;
BA_ "Version" SG_ 864 L_ATCU_Lib_MngrACBuf6 "23.11.10";
BA_ "Description" SG_ 864 L_ATCU_Lib_MngrACBuf7 "This value only use for ATCU Library data monitoring (Only use before SOP)";
BA_ "GenSigSendType" SG_ 864 L_ATCU_Lib_MngrACBuf7 4;
BA_ "UserSigValidity" SG_ 864 L_ATCU_Lib_MngrACBuf7 0;
BA_REL_ "GenSigTimeoutTime" BU_SG_REL_ L_ATCU_vMON SG_ 864 L_ATCU_Lib_MngrACBuf7 5000;
BA_ "Version" SG_ 864 L_ATCU_Lib_MngrACBuf7 "23.11.10";
BA_ "Description" SG_ 864 L_ATCU_Lib_MngrDEFBufLow1 "This value only use for ATCU Library data monitoring (Only use before SOP)";
BA_ "GenSigSendType" SG_ 864 L_ATCU_Lib_MngrDEFBufLow1 4;
BA_ "UserSigValidity" SG_ 864 L_ATCU_Lib_MngrDEFBufLow1 0;
BA_REL_ "GenSigTimeoutTime" BU_SG_REL_ L_ATCU_vMON SG_ 864 L_ATCU_Lib_MngrDEFBufLow1 5000;
BA_ "Version" SG_ 864 L_ATCU_Lib_MngrDEFBufLow1 "23.11.10";
BA_ "Description" SG_ 864 L_ATCU_Lib_MngrTempBufLow1 "This value only use for ATCU Library data monitoring (Only use before SOP)";
BA_ "GenSigSendType" SG_ 864 L_ATCU_Lib_MngrTempBufLow1 4;
BA_ "UserSigValidity" SG_ 864 L_ATCU_Lib_MngrTempBufLow1 0;
BA_REL_ "GenSigTimeoutTime" BU_SG_REL_ L_ATCU_vMON SG_ 864 L_ATCU_Lib_MngrTempBufLow1 5000;
BA_ "Version" SG_ 864 L_ATCU_Lib_MngrTempBufLow1 "23.11.10";
BA_ "Description" SG_ 864 L_ATCU_Lib_MngrTempBufLow0 "This value only use for ATCU Library data monitoring (Only use before SOP)";
BA_ "GenSigSendType" SG_ 864 L_ATCU_Lib_MngrTempBufLow0 4;
BA_ "UserSigValidity" SG_ 864 L_ATCU_Lib_MngrTempBufLow0 0;
BA_REL_ "GenSigTimeoutTime" BU_SG_REL_ L_ATCU_vMON SG_ 864 L_ATCU_Lib_MngrTempBufLow0 5000;
BA_ "Version" SG_ 864 L_ATCU_Lib_MngrTempBufLow0 "23.11.10";
BA_ "Description" SG_ 864 L_ATCU_Lib_MngrIntakeBufHi0 "This value only use for ATCU Library data monitoring (Only use before SOP)";
BA_ "GenSigSendType" SG_ 864 L_ATCU_Lib_MngrIntakeBufHi0 4;
BA_ "UserSigValidity" SG_ 864 L_ATCU_Lib_MngrIntakeBufHi0 0;
BA_REL_ "GenSigTimeoutTime" BU_SG_REL_ L_ATCU_vMON SG_ 864 L_ATCU_Lib_MngrIntakeBufHi0 5000;
BA_ "Version" SG_ 864 L_ATCU_Lib_MngrIntakeBufHi0 "23.11.10";
BA_ "Description" SG_ 864 L_ATCU_Lib_MngrIntakeBufHi1 "This value only use for ATCU Library data monitoring (Only use before SOP)";
BA_ "GenSigSendType" SG_ 864 L_ATCU_Lib_MngrIntakeBufHi1 4;
BA_ "UserSigValidity" SG_ 864 L_ATCU_Lib_MngrIntakeBufHi1 0;
BA_REL_ "GenSigTimeoutTime" BU_SG_REL_ L_ATCU_vMON SG_ 864 L_ATCU_Lib_MngrIntakeBufHi1 5000;
BA_ "Version" SG_ 864 L_ATCU_Lib_MngrIntakeBufHi1 "23.11.10";
BA_ "Description" SG_ 864 L_ATCU_Lib_MngrIntakeBufLow2 "This value only use for ATCU Library data monitoring (Only use before SOP)";
BA_ "GenSigSendType" SG_ 864 L_ATCU_Lib_MngrIntakeBufLow2 4;
BA_ "UserSigValidity" SG_ 864 L_ATCU_Lib_MngrIntakeBufLow2 0;
BA_REL_ "GenSigTimeoutTime" BU_SG_REL_ L_ATCU_vMON SG_ 864 L_ATCU_Lib_MngrIntakeBufLow2 5000;
BA_ "Version" SG_ 864 L_ATCU_Lib_MngrIntakeBufLow2 "24.09.00";
BA_ "Description" SG_ 864 L_ATCU_Lib_MngrDEFBufLow0 "This value only use for ATCU Library data monitoring (Only use before SOP)";
BA_ "GenSigSendType" SG_ 864 L_ATCU_Lib_MngrDEFBufLow0 4;
BA_ "UserSigValidity" SG_ 864 L_ATCU_Lib_MngrDEFBufLow0 0;
BA_REL_ "GenSigTimeoutTime" BU_SG_REL_ L_ATCU_vMON SG_ 864 L_ATCU_Lib_MngrDEFBufLow0 5000;
BA_ "Version" SG_ 864 L_ATCU_Lib_MngrDEFBufLow0 "23.11.10";
BA_ "Description" SG_ 864 L_ATCU_Lib_MngrDEFBuf2 "This value only use for ATCU Library data monitoring (Only use before SOP)";
BA_ "GenSigSendType" SG_ 864 L_ATCU_Lib_MngrDEFBuf2 4;
BA_ "UserSigValidity" SG_ 864 L_ATCU_Lib_MngrDEFBuf2 0;
BA_REL_ "GenSigTimeoutTime" BU_SG_REL_ L_ATCU_vMON SG_ 864 L_ATCU_Lib_MngrDEFBuf2 5000;
BA_ "Version" SG_ 864 L_ATCU_Lib_MngrDEFBuf2 "23.11.10";
BA_ "GenMsgSendType" BO_ 880 0;
BA_ "GenMsgCycleTime" BO_ 880 2000;
BA_ "Description" SG_ 880 L_ATCU_Lib_StatMngr_2ndSafetynCool "This value only use for ATCU Library data monitoring (Only use before SOP)";
BA_ "GenSigSendType" SG_ 880 L_ATCU_Lib_StatMngr_2ndSafetynCool 4;
BA_ "UserSigValidity" SG_ 880 L_ATCU_Lib_StatMngr_2ndSafetynCool 0;
BA_REL_ "GenSigTimeoutTime" BU_SG_REL_ L_ATCU_vMON SG_ 880 L_ATCU_Lib_StatMngr_2ndSafetynCool 5000;
BA_ "Version" SG_ 880 L_ATCU_Lib_StatMngr_2ndSafetynCool "24.09.01";
BA_ "GenMsgSendType" BO_ 881 0;
BA_ "GenMsgCycleTime" BO_ 881 2000;
BA_ "Description" SG_ 881 L_ATCU_Lib_StatMngr_2ndMngr "This value only use for ATCU Library data monitoring (Only use before SOP)";
BA_ "GenSigSendType" SG_ 881 L_ATCU_Lib_StatMngr_2ndMngr 4;
BA_ "UserSigValidity" SG_ 881 L_ATCU_Lib_StatMngr_2ndMngr 0;
BA_REL_ "GenSigTimeoutTime" BU_SG_REL_ L_ATCU_vMON SG_ 881 L_ATCU_Lib_StatMngr_2ndMngr 5000;
BA_ "Version" SG_ 881 L_ATCU_Lib_StatMngr_2ndMngr "24.09.01";
BA_ "GenMsgSendType" BO_ 882 0;
BA_ "GenMsgCycleTime" BO_ 882 2000;
BA_ "Description" SG_ 882 L_ATCU_Lib_StatMngr_2ndConvenience "This value only use for ATCU Library data monitoring (Only use before SOP)";
BA_ "GenSigSendType" SG_ 882 L_ATCU_Lib_StatMngr_2ndConvenience 4;
BA_ "UserSigValidity" SG_ 882 L_ATCU_Lib_StatMngr_2ndConvenience 0;
BA_REL_ "GenSigTimeoutTime" BU_SG_REL_ L_ATCU_vMON SG_ 882 L_ATCU_Lib_StatMngr_2ndConvenience 5000;
BA_ "Version" SG_ 882 L_ATCU_Lib_StatMngr_2ndConvenience "24.09.01";
BA_ "GenMsgSendType" BO_ 883 0;
BA_ "GenMsgCycleTime" BO_ 883 2000;
BA_ "Description" SG_ 883 L_ATCU_Lib_StatMngr_2ndAirQuality "This value only use for ATCU Library data monitoring (Only use before SOP)";
BA_ "GenSigSendType" SG_ 883 L_ATCU_Lib_StatMngr_2ndAirQuality 4;
BA_ "UserSigValidity" SG_ 883 L_ATCU_Lib_StatMngr_2ndAirQuality 0;
BA_REL_ "GenSigTimeoutTime" BU_SG_REL_ L_ATCU_vMON SG_ 883 L_ATCU_Lib_StatMngr_2ndAirQuality 5000;
BA_ "Version" SG_ 883 L_ATCU_Lib_StatMngr_2ndAirQuality "24.09.01";
BA_ "GenMsgSendType" BO_ 884 0;
BA_ "GenMsgCycleTime" BO_ 884 2000;
BA_ "Description" SG_ 884 L_ATCU_Lib_StatMngr_2ndETC "This value only use for ATCU Library data monitoring (Only use before SOP)";
BA_ "GenSigSendType" SG_ 884 L_ATCU_Lib_StatMngr_2ndETC 4;
BA_ "UserSigValidity" SG_ 884 L_ATCU_Lib_StatMngr_2ndETC 0;
BA_REL_ "GenSigTimeoutTime" BU_SG_REL_ L_ATCU_vMON SG_ 884 L_ATCU_Lib_StatMngr_2ndETC 5000;
BA_ "Version" SG_ 884 L_ATCU_Lib_StatMngr_2ndETC "24.09.01";
BA_ "GenMsgSendType" BO_ 885 0;
BA_ "GenMsgCycleTime" BO_ 885 2000;
BA_ "Description" SG_ 885 L_ATCU_Lib_StatMngr_2ndFuelEfficiency "This value only use for ATCU Library data monitoring (Only use before SOP)";
BA_ "GenSigSendType" SG_ 885 L_ATCU_Lib_StatMngr_2ndFuelEfficiency 4;
BA_ "UserSigValidity" SG_ 885 L_ATCU_Lib_StatMngr_2ndFuelEfficiency 0;
BA_REL_ "GenSigTimeoutTime" BU_SG_REL_ L_ATCU_vMON SG_ 885 L_ATCU_Lib_StatMngr_2ndFuelEfficiency 5000;
BA_ "Version" SG_ 885 L_ATCU_Lib_StatMngr_2ndFuelEfficiency "24.09.01";
BA_ "GenMsgSendType" BO_ 886 0;
BA_ "GenMsgCycleTime" BO_ 886 2000;
BA_ "Description" SG_ 886 L_ATCU_Lib_MEM_ROMWriteCnt "ATCU Memory ROM Write Count Data";
BA_ "GenSigSendType" SG_ 886 L_ATCU_Lib_MEM_ROMWriteCnt 4;
BA_ "UserSigValidity" SG_ 886 L_ATCU_Lib_MEM_ROMWriteCnt 0;
BA_REL_ "GenSigTimeoutTime" BU_SG_REL_ L_ATCU_vMON SG_ 886 L_ATCU_Lib_MEM_ROMWriteCnt 5000;
BA_ "Version" SG_ 886 L_ATCU_Lib_MEM_ROMWriteCnt "25.05.03";
BA_ "GenMsgSendType" BO_ 776 0;
BA_ "GenMsgCycleTime" BO_ 776 500;
BA_ "Description" SG_ 776 MON_AutoDrvModState "This value only use for ATCU Library data monitoring (Only use before SOP)";
BA_ "GenSigSendType" SG_ 776 MON_AutoDrvModState 4;
BA_ "UserSigValidity" SG_ 776 MON_AutoDrvModState 0;
BA_REL_ "GenSigTimeoutTime" BU_SG_REL_ L_ATCU SG_ 776 MON_AutoDrvModState 5000;
BA_ "Version" SG_ 776 MON_AutoDrvModState "24.06.02";
BA_ "Description" SG_ 776 MON_AutoIntakeState "This value only use for ATCU Library data monitoring (Only use before SOP)";
BA_ "GenSigSendType" SG_ 776 MON_AutoIntakeState 4;
BA_ "UserSigValidity" SG_ 776 MON_AutoIntakeState 0;
BA_REL_ "GenSigTimeoutTime" BU_SG_REL_ L_ATCU SG_ 776 MON_AutoIntakeState 5000;
BA_ "Version" SG_ 776 MON_AutoIntakeState "24.06.02";
BA_ "Description" SG_ 776 MON_AutoACState "This value only use for ATCU Library data monitoring (Only use before SOP)";
BA_ "GenSigSendType" SG_ 776 MON_AutoACState 4;
BA_ "UserSigValidity" SG_ 776 MON_AutoACState 0;
BA_REL_ "GenSigTimeoutTime" BU_SG_REL_ L_ATCU SG_ 776 MON_AutoACState 5000;
BA_ "Version" SG_ 776 MON_AutoACState "24.06.02";
BA_ "Description" SG_ 776 MON_AutoEvapTargetTemp "This value only use for ATCU Library data monitoring (Only use before SOP)";
BA_ "GenSigSendType" SG_ 776 MON_AutoEvapTargetTemp 4;
BA_ "UserSigValidity" SG_ 776 MON_AutoEvapTargetTemp 0;
BA_REL_ "GenSigTimeoutTime" BU_SG_REL_ L_ATCU SG_ 776 MON_AutoEvapTargetTemp 5000;
BA_ "Version" SG_ 776 MON_AutoEvapTargetTemp "24.06.02";
BA_ "Description" SG_ 776 MON_AutoBlrVtgVal "This value only use for ATCU Library data monitoring (Only use before SOP)";
BA_ "GenSigSendType" SG_ 776 MON_AutoBlrVtgVal 4;
BA_ "UserSigValidity" SG_ 776 MON_AutoBlrVtgVal 0;
BA_REL_ "GenSigTimeoutTime" BU_SG_REL_ L_ATCU SG_ 776 MON_AutoBlrVtgVal 5000;
BA_ "Version" SG_ 776 MON_AutoBlrVtgVal "24.06.02";
BA_ "GenMsgSendType" BO_ 777 0;
BA_ "GenMsgCycleTime" BO_ 777 500;
BA_ "Description" SG_ 777 MON_AutoAstTargetTempVal "This value only use for ATCU Library data monitoring (Only use before SOP)";
BA_ "GenSigSendType" SG_ 777 MON_AutoAstTargetTempVal 4;
BA_ "UserSigValidity" SG_ 777 MON_AutoAstTargetTempVal 0;
BA_REL_ "GenSigTimeoutTime" BU_SG_REL_ L_ATCU SG_ 777 MON_AutoAstTargetTempVal 5000;
BA_ "Version" SG_ 777 MON_AutoAstTargetTempVal "24.06.02";
BA_ "Description" SG_ 777 MON_AutoAstTempDrState "This value only use for ATCU Library data monitoring (Only use before SOP)";
BA_ "GenSigSendType" SG_ 777 MON_AutoAstTempDrState 4;
BA_ "UserSigValidity" SG_ 777 MON_AutoAstTempDrState 0;
BA_REL_ "GenSigTimeoutTime" BU_SG_REL_ L_ATCU SG_ 777 MON_AutoAstTempDrState 5000;
BA_ "Version" SG_ 777 MON_AutoAstTempDrState "24.06.02";
BA_ "Description" SG_ 777 MON_AutoDrvTargetTempVal "This value only use for ATCU Library data monitoring (Only use before SOP)";
BA_ "GenSigSendType" SG_ 777 MON_AutoDrvTargetTempVal 4;
BA_ "UserSigValidity" SG_ 777 MON_AutoDrvTargetTempVal 0;
BA_REL_ "GenSigTimeoutTime" BU_SG_REL_ L_ATCU SG_ 777 MON_AutoDrvTargetTempVal 5000;
BA_ "Version" SG_ 777 MON_AutoDrvTargetTempVal "24.06.02";
BA_ "Description" SG_ 777 MON_AutoDrvTempDrState "This value only use for ATCU Library data monitoring (Only use before SOP)";
BA_ "GenSigSendType" SG_ 777 MON_AutoDrvTempDrState 4;
BA_ "UserSigValidity" SG_ 777 MON_AutoDrvTempDrState 0;
BA_REL_ "GenSigTimeoutTime" BU_SG_REL_ L_ATCU SG_ 777 MON_AutoDrvTempDrState 5000;
BA_ "Version" SG_ 777 MON_AutoDrvTempDrState "24.06.02";
BA_ "GenMsgSendType" BO_ 1025 0;
BA_ "GenMsgCycleTime" BO_ 1025 1000;
BA_ "Description" SG_ 1025 L_EVNT_HU_FrDrEVntSidePtDisp_X "Electric Vent Frt Driver Side Electric Vent Touch Range X Coordinate Display Feedback (To CTS)";
BA_ "GenSigSendType" SG_ 1025 L_EVNT_HU_FrDrEVntSidePtDisp_X 4;
BA_ "UserSigValidity" SG_ 1025 L_EVNT_HU_FrDrEVntSidePtDisp_X 7;
BA_REL_ "GenSigTimeoutTime" BU_SG_REL_ L_ATCU SG_ 1025 L_EVNT_HU_FrDrEVntSidePtDisp_X 5000;
BA_ "Version" SG_ 1025 L_EVNT_HU_FrDrEVntSidePtDisp_X "24.05.11";
BA_ "Description" SG_ 1025 L_EVNT_HU_FrDrEVntSidePtDisp_Y "Electric Vent Frt Driver Side Electric Vent Touch Range Y Coordinate Display Feedback (To CTS)";
BA_ "GenSigSendType" SG_ 1025 L_EVNT_HU_FrDrEVntSidePtDisp_Y 4;
BA_ "UserSigValidity" SG_ 1025 L_EVNT_HU_FrDrEVntSidePtDisp_Y 7;
BA_REL_ "GenSigTimeoutTime" BU_SG_REL_ L_ATCU SG_ 1025 L_EVNT_HU_FrDrEVntSidePtDisp_Y 5000;
BA_ "Version" SG_ 1025 L_EVNT_HU_FrDrEVntSidePtDisp_Y "24.05.11";
BA_ "Description" SG_ 1025 L_EVNT_HU_FrDrEVntCtrPtDisp_X "Electric Vent Frt Driver Center Electric Vent Touch Range X Coordinate Display Feedback (To CTS)";
BA_ "GenSigSendType" SG_ 1025 L_EVNT_HU_FrDrEVntCtrPtDisp_X 4;
BA_ "UserSigValidity" SG_ 1025 L_EVNT_HU_FrDrEVntCtrPtDisp_X 7;
BA_REL_ "GenSigTimeoutTime" BU_SG_REL_ L_ATCU SG_ 1025 L_EVNT_HU_FrDrEVntCtrPtDisp_X 5000;
BA_ "Version" SG_ 1025 L_EVNT_HU_FrDrEVntCtrPtDisp_X "24.05.11";
BA_ "Description" SG_ 1025 L_EVNT_HU_FrDrEVntCtrPtDisp_Y "Electric Vent Frt Driver Center Electric Vent Touch Range Y Coordinate Display Feedback (To CTS)";
BA_ "GenSigSendType" SG_ 1025 L_EVNT_HU_FrDrEVntCtrPtDisp_Y 4;
BA_ "UserSigValidity" SG_ 1025 L_EVNT_HU_FrDrEVntCtrPtDisp_Y 7;
BA_REL_ "GenSigTimeoutTime" BU_SG_REL_ L_ATCU SG_ 1025 L_EVNT_HU_FrDrEVntCtrPtDisp_Y 5000;
BA_ "Version" SG_ 1025 L_EVNT_HU_FrDrEVntCtrPtDisp_Y "24.05.11";
BA_ "GenMsgSendType" BO_ 1026 0;
BA_ "GenMsgCycleTime" BO_ 1026 1000;
BA_ "Description" SG_ 1026 L_EVNT_HU_FrPsEVntSidePtDisp_X "Electric Vent Frt Passenger Side Electric Vent Touch Range X Coordinate Display Feedback (To CTS)";
BA_ "GenSigSendType" SG_ 1026 L_EVNT_HU_FrPsEVntSidePtDisp_X 4;
BA_ "UserSigValidity" SG_ 1026 L_EVNT_HU_FrPsEVntSidePtDisp_X 7;
BA_REL_ "GenSigTimeoutTime" BU_SG_REL_ L_ATCU SG_ 1026 L_EVNT_HU_FrPsEVntSidePtDisp_X 5000;
BA_ "Version" SG_ 1026 L_EVNT_HU_FrPsEVntSidePtDisp_X "24.05.11";
BA_ "Description" SG_ 1026 L_EVNT_HU_FrPsEVntSidePtDisp_Y "Electric Vent Frt Passenger Side Electric Vent Touch Range Y Coordinate Display Feedback (To CTS)";
BA_ "GenSigSendType" SG_ 1026 L_EVNT_HU_FrPsEVntSidePtDisp_Y 4;
BA_ "UserSigValidity" SG_ 1026 L_EVNT_HU_FrPsEVntSidePtDisp_Y 7;
BA_REL_ "GenSigTimeoutTime" BU_SG_REL_ L_ATCU SG_ 1026 L_EVNT_HU_FrPsEVntSidePtDisp_Y 5000;
BA_ "Version" SG_ 1026 L_EVNT_HU_FrPsEVntSidePtDisp_Y "24.05.11";
BA_ "Description" SG_ 1026 L_EVNT_HU_FrPsEVntCtrPtDisp_X "Electric Vent Frt Passenger Center Electric Vent Touch Range X Coordinate Display Feedback (To CTS)";
BA_ "GenSigSendType" SG_ 1026 L_EVNT_HU_FrPsEVntCtrPtDisp_X 4;
BA_ "UserSigValidity" SG_ 1026 L_EVNT_HU_FrPsEVntCtrPtDisp_X 7;
BA_REL_ "GenSigTimeoutTime" BU_SG_REL_ L_ATCU SG_ 1026 L_EVNT_HU_FrPsEVntCtrPtDisp_X 5000;
BA_ "Version" SG_ 1026 L_EVNT_HU_FrPsEVntCtrPtDisp_X "24.05.11";
BA_ "Description" SG_ 1026 L_EVNT_HU_FrPsEVntCtrPtDisp_Y "Electric Vent Frt Passenger Center Electric Vent Touch Range Y Coordinate Display Feedback (To CTS)";
BA_ "GenSigSendType" SG_ 1026 L_EVNT_HU_FrPsEVntCtrPtDisp_Y 4;
BA_ "UserSigValidity" SG_ 1026 L_EVNT_HU_FrPsEVntCtrPtDisp_Y 7;
BA_REL_ "GenSigTimeoutTime" BU_SG_REL_ L_ATCU SG_ 1026 L_EVNT_HU_FrPsEVntCtrPtDisp_Y 5000;
BA_ "Version" SG_ 1026 L_EVNT_HU_FrPsEVntCtrPtDisp_Y "24.05.11";
BA_ "GenMsgSendType" BO_ 1027 0;
BA_ "GenMsgCycleTime" BO_ 1027 1000;
BA_ "Description" SG_ 1027 L_EVNT_HU_RrDrEVntConsPtDisp_X "Electric Vent Rear Driver Console Touch Range X Coordinate Display Feedback (To CTS)";
BA_ "GenSigSendType" SG_ 1027 L_EVNT_HU_RrDrEVntConsPtDisp_X 4;
BA_ "UserSigValidity" SG_ 1027 L_EVNT_HU_RrDrEVntConsPtDisp_X 7;
BA_REL_ "GenSigTimeoutTime" BU_SG_REL_ L_ATCU SG_ 1027 L_EVNT_HU_RrDrEVntConsPtDisp_X 5000;
BA_ "Version" SG_ 1027 L_EVNT_HU_RrDrEVntConsPtDisp_X "24.05.11";
BA_ "Description" SG_ 1027 L_EVNT_HU_RrDrEVntConsPtDisp_Y "Electric Vent Rear Driver Console Touch Range Y Coordinate Display Feedback (To CTS)";
BA_ "GenSigSendType" SG_ 1027 L_EVNT_HU_RrDrEVntConsPtDisp_Y 4;
BA_ "UserSigValidity" SG_ 1027 L_EVNT_HU_RrDrEVntConsPtDisp_Y 7;
BA_REL_ "GenSigTimeoutTime" BU_SG_REL_ L_ATCU SG_ 1027 L_EVNT_HU_RrDrEVntConsPtDisp_Y 5000;
BA_ "Version" SG_ 1027 L_EVNT_HU_RrDrEVntConsPtDisp_Y "24.05.11";
BA_ "Description" SG_ 1027 L_EVNT_HU_RrPsEVntConsPtDisp_X "Electric Vent Rear Passenger Console Touch Range X Coordinate Display Feedback (To CTS)";
BA_ "GenSigSendType" SG_ 1027 L_EVNT_HU_RrPsEVntConsPtDisp_X 4;
BA_ "UserSigValidity" SG_ 1027 L_EVNT_HU_RrPsEVntConsPtDisp_X 7;
BA_REL_ "GenSigTimeoutTime" BU_SG_REL_ L_ATCU SG_ 1027 L_EVNT_HU_RrPsEVntConsPtDisp_X 5000;
BA_ "Version" SG_ 1027 L_EVNT_HU_RrPsEVntConsPtDisp_X "24.05.11";
BA_ "Description" SG_ 1027 L_EVNT_HU_RrPsEVntConsPtDisp_Y "Electric Vent Rear Passenger Console Touch Range Y Coordinate Display Feedback (To CTS)";
BA_ "GenSigSendType" SG_ 1027 L_EVNT_HU_RrPsEVntConsPtDisp_Y 4;
BA_ "UserSigValidity" SG_ 1027 L_EVNT_HU_RrPsEVntConsPtDisp_Y 7;
BA_REL_ "GenSigTimeoutTime" BU_SG_REL_ L_ATCU SG_ 1027 L_EVNT_HU_RrPsEVntConsPtDisp_Y 5000;
BA_ "Version" SG_ 1027 L_EVNT_HU_RrPsEVntConsPtDisp_Y "24.05.11";
BA_ "Description" SG_ 1027 L_EVNT_FrDrEVntSideFlt "Front Driver Electric Vent Side Fault Status";
BA_ "GenSigSendType" SG_ 1027 L_EVNT_FrDrEVntSideFlt 4;
BA_ "UserSigValidity" SG_ 1027 L_EVNT_FrDrEVntSideFlt 7;
BA_REL_ "GenSigTimeoutTime" BU_SG_REL_ L_ATCU SG_ 1027 L_EVNT_FrDrEVntSideFlt 5000;
BA_ "Version" SG_ 1027 L_EVNT_FrDrEVntSideFlt "24.05.11";
BA_ "Description" SG_ 1027 L_EVNT_FrDrEVntCtrFlt "Front Driver Electric Vent Center Fault Status";
BA_ "GenSigSendType" SG_ 1027 L_EVNT_FrDrEVntCtrFlt 4;
BA_ "UserSigValidity" SG_ 1027 L_EVNT_FrDrEVntCtrFlt 7;
BA_REL_ "GenSigTimeoutTime" BU_SG_REL_ L_ATCU SG_ 1027 L_EVNT_FrDrEVntCtrFlt 5000;
BA_ "Version" SG_ 1027 L_EVNT_FrDrEVntCtrFlt "24.05.11";
BA_ "Description" SG_ 1027 L_EVNT_FrPsEVntSideFlt "Front Passenger Electric Vent Side Fault Status";
BA_ "GenSigSendType" SG_ 1027 L_EVNT_FrPsEVntSideFlt 4;
BA_ "UserSigValidity" SG_ 1027 L_EVNT_FrPsEVntSideFlt 7;
BA_REL_ "GenSigTimeoutTime" BU_SG_REL_ L_ATCU SG_ 1027 L_EVNT_FrPsEVntSideFlt 5000;
BA_ "Version" SG_ 1027 L_EVNT_FrPsEVntSideFlt "24.05.11";
BA_ "Description" SG_ 1027 L_EVNT_FrPsEVntCtrFlt "Front Passenger Electric Vent Center Fault Status";
BA_ "GenSigSendType" SG_ 1027 L_EVNT_FrPsEVntCtrFlt 4;
BA_ "UserSigValidity" SG_ 1027 L_EVNT_FrPsEVntCtrFlt 7;
BA_REL_ "GenSigTimeoutTime" BU_SG_REL_ L_ATCU SG_ 1027 L_EVNT_FrPsEVntCtrFlt 5000;
BA_ "Version" SG_ 1027 L_EVNT_FrPsEVntCtrFlt "24.05.11";
BA_ "Description" SG_ 1027 L_EVNT_RrDrEVntConsFlt "Front Rear (2nd) Driver Electric Vent Console Fault Status";
BA_ "GenSigSendType" SG_ 1027 L_EVNT_RrDrEVntConsFlt 4;
BA_ "UserSigValidity" SG_ 1027 L_EVNT_RrDrEVntConsFlt 7;
BA_REL_ "GenSigTimeoutTime" BU_SG_REL_ L_ATCU SG_ 1027 L_EVNT_RrDrEVntConsFlt 5000;
BA_ "Version" SG_ 1027 L_EVNT_RrDrEVntConsFlt "24.05.11";
BA_ "Description" SG_ 1027 L_EVNT_RrPsEVntConsFlt "Front Rear (2nd) Passenger Electric Vent Console Fault Status";
BA_ "GenSigSendType" SG_ 1027 L_EVNT_RrPsEVntConsFlt 4;
BA_ "UserSigValidity" SG_ 1027 L_EVNT_RrPsEVntConsFlt 7;
BA_REL_ "GenSigTimeoutTime" BU_SG_REL_ L_ATCU SG_ 1027 L_EVNT_RrPsEVntConsFlt 5000;
BA_ "Version" SG_ 1027 L_EVNT_RrPsEVntConsFlt "24.05.11";
BA_ "GenMsgSendType" BO_ 1028 0;
BA_ "GenMsgCycleTime" BO_ 1028 1000;
BA_ "Description" SG_ 1028 L_EVNT_FrDrEVntModeSet_Disp "Electric Vent Frt Driver Mode Signal Display Feedback";
BA_ "GenSigSendType" SG_ 1028 L_EVNT_FrDrEVntModeSet_Disp 4;
BA_ "UserSigValidity" SG_ 1028 L_EVNT_FrDrEVntModeSet_Disp 7;
BA_REL_ "GenSigTimeoutTime" BU_SG_REL_ L_ATCU SG_ 1028 L_EVNT_FrDrEVntModeSet_Disp 5000;
BA_ "Version" SG_ 1028 L_EVNT_FrDrEVntModeSet_Disp "25.04.02";
BA_ "Description" SG_ 1028 L_EVNT_RrPsEVntModeSet_Disp "Electric Vent Rear Passenger Mode Signal Display Feedback";
BA_ "GenSigSendType" SG_ 1028 L_EVNT_RrPsEVntModeSet_Disp 4;
BA_ "UserSigValidity" SG_ 1028 L_EVNT_RrPsEVntModeSet_Disp 7;
BA_REL_ "GenSigTimeoutTime" BU_SG_REL_ L_ATCU SG_ 1028 L_EVNT_RrPsEVntModeSet_Disp 5000;
BA_ "Version" SG_ 1028 L_EVNT_RrPsEVntModeSet_Disp "25.04.02";
BA_ "Description" SG_ 1028 L_EVNT_FrDrEVntSideOpnClsDisp "Electric Vent Frt Driver Side Vent Open/Close Signal Display Feedback";
BA_ "GenSigSendType" SG_ 1028 L_EVNT_FrDrEVntSideOpnClsDisp 4;
BA_ "UserSigValidity" SG_ 1028 L_EVNT_FrDrEVntSideOpnClsDisp 7;
BA_REL_ "GenSigTimeoutTime" BU_SG_REL_ L_ATCU SG_ 1028 L_EVNT_FrDrEVntSideOpnClsDisp 5000;
BA_ "Version" SG_ 1028 L_EVNT_FrDrEVntSideOpnClsDisp "24.05.11";
BA_ "Description" SG_ 1028 L_EVNT_FrDrEVntCtrOpnClsDisp "Electric Vent Frt Driver Center Vent Open/Close Signal Display Feedback";
BA_ "GenSigSendType" SG_ 1028 L_EVNT_FrDrEVntCtrOpnClsDisp 4;
BA_ "UserSigValidity" SG_ 1028 L_EVNT_FrDrEVntCtrOpnClsDisp 7;
BA_REL_ "GenSigTimeoutTime" BU_SG_REL_ L_ATCU SG_ 1028 L_EVNT_FrDrEVntCtrOpnClsDisp 5000;
BA_ "Version" SG_ 1028 L_EVNT_FrDrEVntCtrOpnClsDisp "24.05.11";
BA_ "Description" SG_ 1028 L_EVNT_FrPsEVntSideOpnClsDisp "Electric Vent Frt Passenger Side Vent Open/Close Signal Display Feedback";
BA_ "GenSigSendType" SG_ 1028 L_EVNT_FrPsEVntSideOpnClsDisp 4;
BA_ "UserSigValidity" SG_ 1028 L_EVNT_FrPsEVntSideOpnClsDisp 7;
BA_REL_ "GenSigTimeoutTime" BU_SG_REL_ L_ATCU SG_ 1028 L_EVNT_FrPsEVntSideOpnClsDisp 5000;
BA_ "Version" SG_ 1028 L_EVNT_FrPsEVntSideOpnClsDisp "24.05.11";
BA_ "Description" SG_ 1028 L_EVNT_FrPsEVntCtrOpnClsDisp "Electric Vent Frt Passenger Center Vent Open/Close Signal Display Feedback";
BA_ "GenSigSendType" SG_ 1028 L_EVNT_FrPsEVntCtrOpnClsDisp 4;
BA_ "UserSigValidity" SG_ 1028 L_EVNT_FrPsEVntCtrOpnClsDisp 7;
BA_REL_ "GenSigTimeoutTime" BU_SG_REL_ L_ATCU SG_ 1028 L_EVNT_FrPsEVntCtrOpnClsDisp 5000;
BA_ "Version" SG_ 1028 L_EVNT_FrPsEVntCtrOpnClsDisp "24.05.11";
BA_ "Description" SG_ 1028 L_EVNT_RrDrEVntConsOpnClsDisp "Electric Vent Rear Driver Console Vent Open/Close Signal Display Feedback";
BA_ "GenSigSendType" SG_ 1028 L_EVNT_RrDrEVntConsOpnClsDisp 4;
BA_ "UserSigValidity" SG_ 1028 L_EVNT_RrDrEVntConsOpnClsDisp 7;
BA_REL_ "GenSigTimeoutTime" BU_SG_REL_ L_ATCU SG_ 1028 L_EVNT_RrDrEVntConsOpnClsDisp 5000;
BA_ "Version" SG_ 1028 L_EVNT_RrDrEVntConsOpnClsDisp "24.05.11";
BA_ "Description" SG_ 1028 L_EVNT_RrPsEVntConsOpnClsDisp "Electric Vent Rear Passenger Console Vent Open/Close Signal Display Feedback";
BA_ "GenSigSendType" SG_ 1028 L_EVNT_RrPsEVntConsOpnClsDisp 4;
BA_ "UserSigValidity" SG_ 1028 L_EVNT_RrPsEVntConsOpnClsDisp 7;
BA_REL_ "GenSigTimeoutTime" BU_SG_REL_ L_ATCU SG_ 1028 L_EVNT_RrPsEVntConsOpnClsDisp 5000;
BA_ "Version" SG_ 1028 L_EVNT_RrPsEVntConsOpnClsDisp "24.05.11";
BA_ "Description" SG_ 1028 L_EVNT_EVntTouchInform_HU "Electric Vent touch available information to HU_MM (prevent input from CTS)";
BA_ "GenSigSendType" SG_ 1028 L_EVNT_EVntTouchInform_HU 4;
BA_ "UserSigValidity" SG_ 1028 L_EVNT_EVntTouchInform_HU 7;
BA_REL_ "GenSigTimeoutTime" BU_SG_REL_ L_ATCU SG_ 1028 L_EVNT_EVntTouchInform_HU 5000;
BA_ "Version" SG_ 1028 L_EVNT_EVntTouchInform_HU "24.05.11";
BA_ "Description" SG_ 1028 L_EVNT_EVntTouchInform_CTS "Electric Vent touch available information to CTS (prevent input from HU_MM)";
BA_ "GenSigSendType" SG_ 1028 L_EVNT_EVntTouchInform_CTS 4;
BA_ "UserSigValidity" SG_ 1028 L_EVNT_EVntTouchInform_CTS 7;
BA_REL_ "GenSigTimeoutTime" BU_SG_REL_ L_ATCU SG_ 1028 L_EVNT_EVntTouchInform_CTS 5000;
BA_ "Version" SG_ 1028 L_EVNT_EVntTouchInform_CTS "24.05.11";
BA_ "GenSigSendType" SG_ 1028 L_EVNT_FrtEvntFocusLvlSta 4;
BA_ "UserSigValidity" SG_ 1028 L_EVNT_FrtEvntFocusLvlSta 7;
BA_REL_ "GenSigTimeoutTime" BU_SG_REL_ L_ATCU SG_ 1028 L_EVNT_FrtEvntFocusLvlSta 5000;
BA_ "Version" SG_ 1028 L_EVNT_FrtEvntFocusLvlSta "25.05.04";
BA_ "GenSigSendType" SG_ 1028 L_EVNT_RrEvntFocusLvlSta 4;
BA_ "UserSigValidity" SG_ 1028 L_EVNT_RrEvntFocusLvlSta 7;
BA_REL_ "GenSigTimeoutTime" BU_SG_REL_ L_ATCU SG_ 1028 L_EVNT_RrEvntFocusLvlSta 5000;
BA_ "Version" SG_ 1028 L_EVNT_RrEvntFocusLvlSta "25.05.04";
BA_ "GenSigSendType" SG_ 1028 L_EVNT_DrVntOpt 4;
BA_ "UserSigValidity" SG_ 1028 L_EVNT_DrVntOpt 7;
BA_REL_ "GenSigTimeoutTime" BU_SG_REL_ L_ATCU SG_ 1028 L_EVNT_DrVntOpt 5000;
BA_ "Version" SG_ 1028 L_EVNT_DrVntOpt "25.06.00";
BA_ "Description" SG_ 1028 L_EVNT_FrPsEVntModeSet_Disp "Electric Vent Frt Passenger Mode Signal Display Feedback";
BA_ "GenSigSendType" SG_ 1028 L_EVNT_FrPsEVntModeSet_Disp 4;
BA_ "UserSigValidity" SG_ 1028 L_EVNT_FrPsEVntModeSet_Disp 7;
BA_REL_ "GenSigTimeoutTime" BU_SG_REL_ L_ATCU SG_ 1028 L_EVNT_FrPsEVntModeSet_Disp 5000;
BA_ "Version" SG_ 1028 L_EVNT_FrPsEVntModeSet_Disp "25.04.02";
BA_ "GenSigSendType" SG_ 1028 L_EVNT_AstVntOpt 4;
BA_ "UserSigValidity" SG_ 1028 L_EVNT_AstVntOpt 7;
BA_REL_ "GenSigTimeoutTime" BU_SG_REL_ L_ATCU SG_ 1028 L_EVNT_AstVntOpt 5000;
BA_ "Version" SG_ 1028 L_EVNT_AstVntOpt "25.06.00";
BA_ "GenSigSendType" SG_ 1028 L_EVNT_RrDrVntOpt 4;
BA_ "UserSigValidity" SG_ 1028 L_EVNT_RrDrVntOpt 7;
BA_REL_ "GenSigTimeoutTime" BU_SG_REL_ L_ATCU SG_ 1028 L_EVNT_RrDrVntOpt 5000;
BA_ "Version" SG_ 1028 L_EVNT_RrDrVntOpt "25.06.00";
BA_ "GenSigSendType" SG_ 1028 L_EVNT_RrAstVntOpt 4;
BA_ "UserSigValidity" SG_ 1028 L_EVNT_RrAstVntOpt 7;
BA_REL_ "GenSigTimeoutTime" BU_SG_REL_ L_ATCU SG_ 1028 L_EVNT_RrAstVntOpt 5000;
BA_ "Version" SG_ 1028 L_EVNT_RrAstVntOpt "25.06.00";
BA_ "Description" SG_ 1028 L_EVNT_EVntAutoAirFlowHotKeyOpt "Main can option routing / EVntAutoAirFlowHotKeyOpt";
BA_ "GenSigSendType" SG_ 1028 L_EVNT_EVntAutoAirFlowHotKeyOpt 4;
BA_ "UserSigValidity" SG_ 1028 L_EVNT_EVntAutoAirFlowHotKeyOpt 7;
BA_REL_ "GenSigTimeoutTime" BU_SG_REL_ L_ATCU SG_ 1028 L_EVNT_EVntAutoAirFlowHotKeyOpt 5000;
BA_ "Version" SG_ 1028 L_EVNT_EVntAutoAirFlowHotKeyOpt "25.08.06";
BA_ "Description" SG_ 1028 L_EVNT_RrDrEVntModeSet_Disp "Electric Vent Rear Driver Mode Signal Display Feedback";
BA_ "GenSigSendType" SG_ 1028 L_EVNT_RrDrEVntModeSet_Disp 4;
BA_ "UserSigValidity" SG_ 1028 L_EVNT_RrDrEVntModeSet_Disp 7;
BA_REL_ "GenSigTimeoutTime" BU_SG_REL_ L_ATCU SG_ 1028 L_EVNT_RrDrEVntModeSet_Disp 5000;
BA_ "Version" SG_ 1028 L_EVNT_RrDrEVntModeSet_Disp "25.04.02";
BA_ "GenMsgSendType" BO_ 1029 0;
BA_ "GenMsgCycleTime" BO_ 1029 1000;
BA_ "Description" SG_ 1029 L_EVNT_CTS_FrDrEVntSidePtDisp_X "Electric Vent Frt Driver Side Electric Vent Touch Range X Coordinate Display Feedback (To CTS)";
BA_ "GenSigSendType" SG_ 1029 L_EVNT_CTS_FrDrEVntSidePtDisp_X 4;
BA_ "UserSigValidity" SG_ 1029 L_EVNT_CTS_FrDrEVntSidePtDisp_X 7;
BA_REL_ "GenSigTimeoutTime" BU_SG_REL_ L_ATCU SG_ 1029 L_EVNT_CTS_FrDrEVntSidePtDisp_X 5000;
BA_ "Version" SG_ 1029 L_EVNT_CTS_FrDrEVntSidePtDisp_X "24.05.11";
BA_ "Description" SG_ 1029 L_EVNT_CTS_FrDrEVntSidePtDisp_Y "Electric Vent Frt Driver Side Electric Vent Touch Range Y Coordinate Display Feedback (To CTS)";
BA_ "GenSigSendType" SG_ 1029 L_EVNT_CTS_FrDrEVntSidePtDisp_Y 4;
BA_ "UserSigValidity" SG_ 1029 L_EVNT_CTS_FrDrEVntSidePtDisp_Y 7;
BA_REL_ "GenSigTimeoutTime" BU_SG_REL_ L_ATCU SG_ 1029 L_EVNT_CTS_FrDrEVntSidePtDisp_Y 5000;
BA_ "Version" SG_ 1029 L_EVNT_CTS_FrDrEVntSidePtDisp_Y "24.05.11";
BA_ "Description" SG_ 1029 L_EVNT_CTS_FrDrEVntCtrPtDisp_X "Electric Vent Frt Driver Center Electric Vent Touch Range X Coordinate Display Feedback (To CTS)";
BA_ "GenSigSendType" SG_ 1029 L_EVNT_CTS_FrDrEVntCtrPtDisp_X 4;
BA_ "UserSigValidity" SG_ 1029 L_EVNT_CTS_FrDrEVntCtrPtDisp_X 7;
BA_REL_ "GenSigTimeoutTime" BU_SG_REL_ L_ATCU SG_ 1029 L_EVNT_CTS_FrDrEVntCtrPtDisp_X 5000;
BA_ "Version" SG_ 1029 L_EVNT_CTS_FrDrEVntCtrPtDisp_X "24.05.11";
BA_ "Description" SG_ 1029 L_EVNT_CTS_FrDrEVntCtrPtDisp_Y "Electric Vent Frt Driver Center Electric Vent Touch Range Y Coordinate Display Feedback (To CTS)";
BA_ "GenSigSendType" SG_ 1029 L_EVNT_CTS_FrDrEVntCtrPtDisp_Y 4;
BA_ "UserSigValidity" SG_ 1029 L_EVNT_CTS_FrDrEVntCtrPtDisp_Y 7;
BA_REL_ "GenSigTimeoutTime" BU_SG_REL_ L_ATCU SG_ 1029 L_EVNT_CTS_FrDrEVntCtrPtDisp_Y 5000;
BA_ "Version" SG_ 1029 L_EVNT_CTS_FrDrEVntCtrPtDisp_Y "24.05.11";
BA_ "GenMsgSendType" BO_ 1030 0;
BA_ "GenMsgCycleTime" BO_ 1030 1000;
BA_ "Description" SG_ 1030 L_EVNT_CTS_FrPsEVntSidePtDisp_X "Electric Vent Frt Passenger Side Electric Vent Touch Range X Coordinate Display Feedback (To CTS)";
BA_ "GenSigSendType" SG_ 1030 L_EVNT_CTS_FrPsEVntSidePtDisp_X 4;
BA_ "UserSigValidity" SG_ 1030 L_EVNT_CTS_FrPsEVntSidePtDisp_X 7;
BA_REL_ "GenSigTimeoutTime" BU_SG_REL_ L_ATCU SG_ 1030 L_EVNT_CTS_FrPsEVntSidePtDisp_X 5000;
BA_ "Version" SG_ 1030 L_EVNT_CTS_FrPsEVntSidePtDisp_X "24.05.11";
BA_ "Description" SG_ 1030 L_EVNT_CTS_FrPsEVntSidePtDisp_Y "Electric Vent Frt Passenger Side Electric Vent Touch Range Y Coordinate Display Feedback (To CTS)";
BA_ "GenSigSendType" SG_ 1030 L_EVNT_CTS_FrPsEVntSidePtDisp_Y 4;
BA_ "UserSigValidity" SG_ 1030 L_EVNT_CTS_FrPsEVntSidePtDisp_Y 7;
BA_REL_ "GenSigTimeoutTime" BU_SG_REL_ L_ATCU SG_ 1030 L_EVNT_CTS_FrPsEVntSidePtDisp_Y 5000;
BA_ "Version" SG_ 1030 L_EVNT_CTS_FrPsEVntSidePtDisp_Y "24.05.11";
BA_ "Description" SG_ 1030 L_EVNT_CTS_FrPsEVntCtrPtDisp_X "Electric Vent Frt Passenger Center Electric Vent Touch Range X Coordinate Display Feedback (To CTS)";
BA_ "GenSigSendType" SG_ 1030 L_EVNT_CTS_FrPsEVntCtrPtDisp_X 4;
BA_ "UserSigValidity" SG_ 1030 L_EVNT_CTS_FrPsEVntCtrPtDisp_X 7;
BA_REL_ "GenSigTimeoutTime" BU_SG_REL_ L_ATCU SG_ 1030 L_EVNT_CTS_FrPsEVntCtrPtDisp_X 5000;
BA_ "Version" SG_ 1030 L_EVNT_CTS_FrPsEVntCtrPtDisp_X "24.05.11";
BA_ "Description" SG_ 1030 L_EVNT_CTS_FrPsEVntCtrPtDisp_Y "Electric Vent Frt Passenger Center Electric Vent Touch Range Y Coordinate Display Feedback (To CTS)";
BA_ "GenSigSendType" SG_ 1030 L_EVNT_CTS_FrPsEVntCtrPtDisp_Y 4;
BA_ "UserSigValidity" SG_ 1030 L_EVNT_CTS_FrPsEVntCtrPtDisp_Y 7;
BA_REL_ "GenSigTimeoutTime" BU_SG_REL_ L_ATCU SG_ 1030 L_EVNT_CTS_FrPsEVntCtrPtDisp_Y 5000;
BA_ "Version" SG_ 1030 L_EVNT_CTS_FrPsEVntCtrPtDisp_Y "24.05.11";
BA_ "GenMsgSendType" BO_ 1031 0;
BA_ "GenMsgCycleTime" BO_ 1031 1000;
BA_ "Description" SG_ 1031 L_EVNT_CTS_RrDrEVntConsPtDisp_X "Electric Vent Rear Driver Console Touch Range X Coordinate Display Feedback (To CTS)";
BA_ "GenSigSendType" SG_ 1031 L_EVNT_CTS_RrDrEVntConsPtDisp_X 4;
BA_ "UserSigValidity" SG_ 1031 L_EVNT_CTS_RrDrEVntConsPtDisp_X 7;
BA_REL_ "GenSigTimeoutTime" BU_SG_REL_ L_ATCU SG_ 1031 L_EVNT_CTS_RrDrEVntConsPtDisp_X 5000;
BA_ "Version" SG_ 1031 L_EVNT_CTS_RrDrEVntConsPtDisp_X "24.05.11";
BA_ "Description" SG_ 1031 L_EVNT_CTS_RrDrEVntConsPtDisp_Y "Electric Vent Rear Driver Console Touch Range Y Coordinate Display Feedback (To CTS)";
BA_ "GenSigSendType" SG_ 1031 L_EVNT_CTS_RrDrEVntConsPtDisp_Y 4;
BA_ "UserSigValidity" SG_ 1031 L_EVNT_CTS_RrDrEVntConsPtDisp_Y 7;
BA_REL_ "GenSigTimeoutTime" BU_SG_REL_ L_ATCU SG_ 1031 L_EVNT_CTS_RrDrEVntConsPtDisp_Y 5000;
BA_ "Version" SG_ 1031 L_EVNT_CTS_RrDrEVntConsPtDisp_Y "24.05.11";
BA_ "Description" SG_ 1031 L_EVNT_CTS_RrPsEVntConsPtDisp_X "Electric Vent Rear Passenger Console Touch Range X Coordinate Display Feedback (To CTS)";
BA_ "GenSigSendType" SG_ 1031 L_EVNT_CTS_RrPsEVntConsPtDisp_X 4;
BA_ "UserSigValidity" SG_ 1031 L_EVNT_CTS_RrPsEVntConsPtDisp_X 7;
BA_REL_ "GenSigTimeoutTime" BU_SG_REL_ L_ATCU SG_ 1031 L_EVNT_CTS_RrPsEVntConsPtDisp_X 5000;
BA_ "Version" SG_ 1031 L_EVNT_CTS_RrPsEVntConsPtDisp_X "24.05.11";
BA_ "Description" SG_ 1031 L_EVNT_CTS_RrPsEVntConsPtDisp_Y "Electric Vent Rear Passenger Console Touch Range Y Coordinate Display Feedback (To CTS)";
BA_ "GenSigSendType" SG_ 1031 L_EVNT_CTS_RrPsEVntConsPtDisp_Y 4;
BA_ "UserSigValidity" SG_ 1031 L_EVNT_CTS_RrPsEVntConsPtDisp_Y 7;
BA_REL_ "GenSigTimeoutTime" BU_SG_REL_ L_ATCU SG_ 1031 L_EVNT_CTS_RrPsEVntConsPtDisp_Y 5000;
BA_ "Version" SG_ 1031 L_EVNT_CTS_RrPsEVntConsPtDisp_Y "24.05.11";
BA_ "GenMsgSendType" BO_ 1032 0;
BA_ "GenMsgCycleTime" BO_ 1032 1000;
BA_ "GenSigSendType" SG_ 1032 L_EVNT_ATCUComFlt 4;
BA_ "UserSigValidity" SG_ 1032 L_EVNT_ATCUComFlt 7;
BA_REL_ "GenSigTimeoutTime" BU_SG_REL_ L_ATCU SG_ 1032 L_EVNT_ATCUComFlt 5000;
BA_ "Version" SG_ 1032 L_EVNT_ATCUComFlt "24.05.11";
BA_ "GenSigSendType" SG_ 1032 L_EVNT_DrvCntrHorComFlt 4;
BA_ "UserSigValidity" SG_ 1032 L_EVNT_DrvCntrHorComFlt 7;
BA_REL_ "GenSigTimeoutTime" BU_SG_REL_ L_ATCU SG_ 1032 L_EVNT_DrvCntrHorComFlt 5000;
BA_ "Version" SG_ 1032 L_EVNT_DrvCntrHorComFlt "24.05.11";
BA_ "GenSigSendType" SG_ 1032 L_EVNT_AstSdVertComFlt 4;
BA_ "UserSigValidity" SG_ 1032 L_EVNT_AstSdVertComFlt 7;
BA_REL_ "GenSigTimeoutTime" BU_SG_REL_ L_ATCU SG_ 1032 L_EVNT_AstSdVertComFlt 5000;
BA_ "Version" SG_ 1032 L_EVNT_AstSdVertComFlt "24.05.11";
BA_ "GenSigSendType" SG_ 1032 L_EVNT_AstSdHorComFlt 4;
BA_ "UserSigValidity" SG_ 1032 L_EVNT_AstSdHorComFlt 7;
BA_REL_ "GenSigTimeoutTime" BU_SG_REL_ L_ATCU SG_ 1032 L_EVNT_AstSdHorComFlt 5000;
BA_ "Version" SG_ 1032 L_EVNT_AstSdHorComFlt "24.05.11";
BA_ "GenSigSendType" SG_ 1032 L_EVNT_AstCntrVertComFlt 4;
BA_ "UserSigValidity" SG_ 1032 L_EVNT_AstCntrVertComFlt 7;
BA_REL_ "GenSigTimeoutTime" BU_SG_REL_ L_ATCU SG_ 1032 L_EVNT_AstCntrVertComFlt 5000;
BA_ "Version" SG_ 1032 L_EVNT_AstCntrVertComFlt "24.05.11";
BA_ "GenSigSendType" SG_ 1032 L_EVNT_AstCntrHorComFlt 4;
BA_ "UserSigValidity" SG_ 1032 L_EVNT_AstCntrHorComFlt 7;
BA_REL_ "GenSigTimeoutTime" BU_SG_REL_ L_ATCU SG_ 1032 L_EVNT_AstCntrHorComFlt 5000;
BA_ "Version" SG_ 1032 L_EVNT_AstCntrHorComFlt "24.05.11";
BA_ "GenSigSendType" SG_ 1032 L_EVNT_EVNTFlt 4;
BA_ "UserSigValidity" SG_ 1032 L_EVNT_EVNTFlt 7;
BA_REL_ "GenSigTimeoutTime" BU_SG_REL_ L_ATCU SG_ 1032 L_EVNT_EVNTFlt 5000;
BA_ "Version" SG_ 1032 L_EVNT_EVNTFlt "24.05.11";
BA_ "GenSigSendType" SG_ 1032 L_EVNT_RrDrvCnslVertComFlt 4;
BA_ "UserSigValidity" SG_ 1032 L_EVNT_RrDrvCnslVertComFlt 7;
BA_REL_ "GenSigTimeoutTime" BU_SG_REL_ L_ATCU SG_ 1032 L_EVNT_RrDrvCnslVertComFlt 5000;
BA_ "Version" SG_ 1032 L_EVNT_RrDrvCnslVertComFlt "24.05.11";
BA_ "GenSigSendType" SG_ 1032 L_EVNT_RrDrvCnslHorComFlt 4;
BA_ "UserSigValidity" SG_ 1032 L_EVNT_RrDrvCnslHorComFlt 7;
BA_REL_ "GenSigTimeoutTime" BU_SG_REL_ L_ATCU SG_ 1032 L_EVNT_RrDrvCnslHorComFlt 5000;
BA_ "Version" SG_ 1032 L_EVNT_RrDrvCnslHorComFlt "24.05.11";
BA_ "GenSigSendType" SG_ 1032 L_EVNT_RrAstCnslVertComFlt 4;
BA_ "UserSigValidity" SG_ 1032 L_EVNT_RrAstCnslVertComFlt 7;
BA_REL_ "GenSigTimeoutTime" BU_SG_REL_ L_ATCU SG_ 1032 L_EVNT_RrAstCnslVertComFlt 5000;
BA_ "Version" SG_ 1032 L_EVNT_RrAstCnslVertComFlt "24.05.11";
BA_ "GenSigSendType" SG_ 1032 L_EVNT_RrAstCnslHorComFlt 4;
BA_ "UserSigValidity" SG_ 1032 L_EVNT_RrAstCnslHorComFlt 7;
BA_REL_ "GenSigTimeoutTime" BU_SG_REL_ L_ATCU SG_ 1032 L_EVNT_RrAstCnslHorComFlt 5000;
BA_ "Version" SG_ 1032 L_EVNT_RrAstCnslHorComFlt "24.05.11";
BA_ "GenSigSendType" SG_ 1032 L_EVNT_DrvSdVertIntFlt 4;
BA_ "UserSigValidity" SG_ 1032 L_EVNT_DrvSdVertIntFlt 7;
BA_REL_ "GenSigTimeoutTime" BU_SG_REL_ L_ATCU SG_ 1032 L_EVNT_DrvSdVertIntFlt 5000;
BA_ "Version" SG_ 1032 L_EVNT_DrvSdVertIntFlt "24.05.11";
BA_ "GenSigSendType" SG_ 1032 L_EVNT_DrvSdHorIntFlt 4;
BA_ "UserSigValidity" SG_ 1032 L_EVNT_DrvSdHorIntFlt 7;
BA_REL_ "GenSigTimeoutTime" BU_SG_REL_ L_ATCU SG_ 1032 L_EVNT_DrvSdHorIntFlt 5000;
BA_ "Version" SG_ 1032 L_EVNT_DrvSdHorIntFlt "24.05.11";
BA_ "GenSigSendType" SG_ 1032 L_EVNT_DrvCntrVertIntFlt 4;
BA_ "UserSigValidity" SG_ 1032 L_EVNT_DrvCntrVertIntFlt 7;
BA_REL_ "GenSigTimeoutTime" BU_SG_REL_ L_ATCU SG_ 1032 L_EVNT_DrvCntrVertIntFlt 5000;
BA_ "Version" SG_ 1032 L_EVNT_DrvCntrVertIntFlt "24.05.11";
BA_ "GenSigSendType" SG_ 1032 L_EVNT_DrvCntrHorIntFlt 4;
BA_ "UserSigValidity" SG_ 1032 L_EVNT_DrvCntrHorIntFlt 7;
BA_REL_ "GenSigTimeoutTime" BU_SG_REL_ L_ATCU SG_ 1032 L_EVNT_DrvCntrHorIntFlt 5000;
BA_ "Version" SG_ 1032 L_EVNT_DrvCntrHorIntFlt "24.05.11";
BA_ "GenSigSendType" SG_ 1032 L_EVNT_AstSdVertIntFlt 4;
BA_ "UserSigValidity" SG_ 1032 L_EVNT_AstSdVertIntFlt 7;
BA_REL_ "GenSigTimeoutTime" BU_SG_REL_ L_ATCU SG_ 1032 L_EVNT_AstSdVertIntFlt 5000;
BA_ "Version" SG_ 1032 L_EVNT_AstSdVertIntFlt "24.05.11";
BA_ "GenSigSendType" SG_ 1032 L_EVNT_AstSdHorIntFlt 4;
BA_ "UserSigValidity" SG_ 1032 L_EVNT_AstSdHorIntFlt 7;
BA_REL_ "GenSigTimeoutTime" BU_SG_REL_ L_ATCU SG_ 1032 L_EVNT_AstSdHorIntFlt 5000;
BA_ "Version" SG_ 1032 L_EVNT_AstSdHorIntFlt "24.05.11";
BA_ "GenSigSendType" SG_ 1032 L_EVNT_DrvSdVertComFlt 4;
BA_ "UserSigValidity" SG_ 1032 L_EVNT_DrvSdVertComFlt 7;
BA_REL_ "GenSigTimeoutTime" BU_SG_REL_ L_ATCU SG_ 1032 L_EVNT_DrvSdVertComFlt 5000;
BA_ "Version" SG_ 1032 L_EVNT_DrvSdVertComFlt "24.05.11";
BA_ "GenSigSendType" SG_ 1032 L_EVNT_AstCntrVertIntFlt 4;
BA_ "UserSigValidity" SG_ 1032 L_EVNT_AstCntrVertIntFlt 7;
BA_REL_ "GenSigTimeoutTime" BU_SG_REL_ L_ATCU SG_ 1032 L_EVNT_AstCntrVertIntFlt 5000;
BA_ "Version" SG_ 1032 L_EVNT_AstCntrVertIntFlt "24.05.11";
BA_ "GenSigSendType" SG_ 1032 L_EVNT_AstCntrHorIntFlt 4;
BA_ "UserSigValidity" SG_ 1032 L_EVNT_AstCntrHorIntFlt 7;
BA_REL_ "GenSigTimeoutTime" BU_SG_REL_ L_ATCU SG_ 1032 L_EVNT_AstCntrHorIntFlt 5000;
BA_ "Version" SG_ 1032 L_EVNT_AstCntrHorIntFlt "24.05.11";
BA_ "GenSigSendType" SG_ 1032 L_EVNT_RrDrvCnslVertIntFlt 4;
BA_ "UserSigValidity" SG_ 1032 L_EVNT_RrDrvCnslVertIntFlt 7;
BA_REL_ "GenSigTimeoutTime" BU_SG_REL_ L_ATCU SG_ 1032 L_EVNT_RrDrvCnslVertIntFlt 5000;
BA_ "Version" SG_ 1032 L_EVNT_RrDrvCnslVertIntFlt "24.05.11";
BA_ "GenSigSendType" SG_ 1032 L_EVNT_RrDrvCnslHorIntFlt 4;
BA_ "UserSigValidity" SG_ 1032 L_EVNT_RrDrvCnslHorIntFlt 7;
BA_REL_ "GenSigTimeoutTime" BU_SG_REL_ L_ATCU SG_ 1032 L_EVNT_RrDrvCnslHorIntFlt 5000;
BA_ "Version" SG_ 1032 L_EVNT_RrDrvCnslHorIntFlt "24.05.11";
BA_ "GenSigSendType" SG_ 1032 L_EVNT_RrAstCnslVertIntFlt 4;
BA_ "UserSigValidity" SG_ 1032 L_EVNT_RrAstCnslVertIntFlt 7;
BA_REL_ "GenSigTimeoutTime" BU_SG_REL_ L_ATCU SG_ 1032 L_EVNT_RrAstCnslVertIntFlt 5000;
BA_ "Version" SG_ 1032 L_EVNT_RrAstCnslVertIntFlt "24.05.11";
BA_ "GenSigSendType" SG_ 1032 L_EVNT_RrAstCnslHorIntFlt 4;
BA_ "UserSigValidity" SG_ 1032 L_EVNT_RrAstCnslHorIntFlt 7;
BA_REL_ "GenSigTimeoutTime" BU_SG_REL_ L_ATCU SG_ 1032 L_EVNT_RrAstCnslHorIntFlt 5000;
BA_ "Version" SG_ 1032 L_EVNT_RrAstCnslHorIntFlt "24.05.11";
BA_ "GenSigSendType" SG_ 1032 L_EVNT_DrvSdVertExtFlt 4;
BA_ "UserSigValidity" SG_ 1032 L_EVNT_DrvSdVertExtFlt 7;
BA_REL_ "GenSigTimeoutTime" BU_SG_REL_ L_ATCU SG_ 1032 L_EVNT_DrvSdVertExtFlt 5000;
BA_ "Version" SG_ 1032 L_EVNT_DrvSdVertExtFlt "24.05.11";
BA_ "GenSigSendType" SG_ 1032 L_EVNT_DrvSdHorExtFlt 4;
BA_ "UserSigValidity" SG_ 1032 L_EVNT_DrvSdHorExtFlt 7;
BA_REL_ "GenSigTimeoutTime" BU_SG_REL_ L_ATCU SG_ 1032 L_EVNT_DrvSdHorExtFlt 5000;
BA_ "Version" SG_ 1032 L_EVNT_DrvSdHorExtFlt "24.05.11";
BA_ "GenSigSendType" SG_ 1032 L_EVNT_DrvCntrVertExtFlt 4;
BA_ "UserSigValidity" SG_ 1032 L_EVNT_DrvCntrVertExtFlt 7;
BA_REL_ "GenSigTimeoutTime" BU_SG_REL_ L_ATCU SG_ 1032 L_EVNT_DrvCntrVertExtFlt 5000;
BA_ "Version" SG_ 1032 L_EVNT_DrvCntrVertExtFlt "24.05.11";
BA_ "GenSigSendType" SG_ 1032 L_EVNT_DrvCntrHorExtFlt 4;
BA_ "UserSigValidity" SG_ 1032 L_EVNT_DrvCntrHorExtFlt 7;
BA_REL_ "GenSigTimeoutTime" BU_SG_REL_ L_ATCU SG_ 1032 L_EVNT_DrvCntrHorExtFlt 5000;
BA_ "Version" SG_ 1032 L_EVNT_DrvCntrHorExtFlt "24.05.11";
BA_ "GenSigSendType" SG_ 1032 L_EVNT_DrvSdHorComFlt 4;
BA_ "UserSigValidity" SG_ 1032 L_EVNT_DrvSdHorComFlt 7;
BA_REL_ "GenSigTimeoutTime" BU_SG_REL_ L_ATCU SG_ 1032 L_EVNT_DrvSdHorComFlt 5000;
BA_ "Version" SG_ 1032 L_EVNT_DrvSdHorComFlt "24.05.11";
BA_ "GenSigSendType" SG_ 1032 L_EVNT_AstSdVertExtFlt 4;
BA_ "UserSigValidity" SG_ 1032 L_EVNT_AstSdVertExtFlt 7;
BA_REL_ "GenSigTimeoutTime" BU_SG_REL_ L_ATCU SG_ 1032 L_EVNT_AstSdVertExtFlt 5000;
BA_ "Version" SG_ 1032 L_EVNT_AstSdVertExtFlt "24.05.11";
BA_ "GenSigSendType" SG_ 1032 L_EVNT_AstSdHorExtFlt 4;
BA_ "UserSigValidity" SG_ 1032 L_EVNT_AstSdHorExtFlt 7;
BA_REL_ "GenSigTimeoutTime" BU_SG_REL_ L_ATCU SG_ 1032 L_EVNT_AstSdHorExtFlt 5000;
BA_ "Version" SG_ 1032 L_EVNT_AstSdHorExtFlt "24.05.11";
BA_ "GenSigSendType" SG_ 1032 L_EVNT_DrvCntrVertComFlt 4;
BA_ "UserSigValidity" SG_ 1032 L_EVNT_DrvCntrVertComFlt 7;
BA_REL_ "GenSigTimeoutTime" BU_SG_REL_ L_ATCU SG_ 1032 L_EVNT_DrvCntrVertComFlt 5000;
BA_ "Version" SG_ 1032 L_EVNT_DrvCntrVertComFlt "24.05.11";
BA_ "GenMsgSendType" BO_ 1033 0;
BA_ "GenMsgCycleTime" BO_ 1033 1000;
BA_ "GenSigSendType" SG_ 1033 L_EVNT_AstCntrVertExtFlt 4;
BA_ "UserSigValidity" SG_ 1033 L_EVNT_AstCntrVertExtFlt 7;
BA_REL_ "GenSigTimeoutTime" BU_SG_REL_ L_ATCU SG_ 1033 L_EVNT_AstCntrVertExtFlt 5000;
BA_ "Version" SG_ 1033 L_EVNT_AstCntrVertExtFlt "24.05.11";
BA_ "GenSigSendType" SG_ 1033 L_EVNT_RrAstCnslHorExtFlt 4;
BA_ "UserSigValidity" SG_ 1033 L_EVNT_RrAstCnslHorExtFlt 7;
BA_REL_ "GenSigTimeoutTime" BU_SG_REL_ L_ATCU SG_ 1033 L_EVNT_RrAstCnslHorExtFlt 5000;
BA_ "Version" SG_ 1033 L_EVNT_RrAstCnslHorExtFlt "24.05.11";
BA_ "GenSigSendType" SG_ 1033 L_EVNT_AstCntrHorExtFlt 4;
BA_ "UserSigValidity" SG_ 1033 L_EVNT_AstCntrHorExtFlt 7;
BA_REL_ "GenSigTimeoutTime" BU_SG_REL_ L_ATCU SG_ 1033 L_EVNT_AstCntrHorExtFlt 5000;
BA_ "Version" SG_ 1033 L_EVNT_AstCntrHorExtFlt "24.05.11";
BA_ "Description" SG_ 1033 L_EVNT_AllResetOpSta "This signal indicates whether the reset operation has been completed or not";
BA_ "GenSigSendType" SG_ 1033 L_EVNT_AllResetOpSta 4;
BA_ "UserSigValidity" SG_ 1033 L_EVNT_AllResetOpSta 0;
BA_REL_ "GenSigTimeoutTime" BU_SG_REL_ L_ATCU SG_ 1033 L_EVNT_AllResetOpSta 1000;
BA_ "Version" SG_ 1033 L_EVNT_AllResetOpSta "25.02.03";
BA_ "Description" SG_ 1033 L_EVNT_DrvSdVertResetOpSta "This signal indicates whether the reset operation has been completed or not";
BA_ "GenSigSendType" SG_ 1033 L_EVNT_DrvSdVertResetOpSta 4;
BA_ "UserSigValidity" SG_ 1033 L_EVNT_DrvSdVertResetOpSta 0;
BA_REL_ "GenSigTimeoutTime" BU_SG_REL_ L_ATCU SG_ 1033 L_EVNT_DrvSdVertResetOpSta 1000;
BA_ "Version" SG_ 1033 L_EVNT_DrvSdVertResetOpSta "25.02.03";
BA_ "GenSigSendType" SG_ 1033 L_EVNT_RrDrvCnslVertExtFlt 4;
BA_ "UserSigValidity" SG_ 1033 L_EVNT_RrDrvCnslVertExtFlt 7;
BA_REL_ "GenSigTimeoutTime" BU_SG_REL_ L_ATCU SG_ 1033 L_EVNT_RrDrvCnslVertExtFlt 5000;
BA_ "Version" SG_ 1033 L_EVNT_RrDrvCnslVertExtFlt "24.05.11";
BA_ "Description" SG_ 1033 L_EVNT_DrvSdHorResetOpSta "This signal indicates whether the reset operation has been completed or not";
BA_ "GenSigSendType" SG_ 1033 L_EVNT_DrvSdHorResetOpSta 4;
BA_ "UserSigValidity" SG_ 1033 L_EVNT_DrvSdHorResetOpSta 0;
BA_REL_ "GenSigTimeoutTime" BU_SG_REL_ L_ATCU SG_ 1033 L_EVNT_DrvSdHorResetOpSta 1000;
BA_ "Version" SG_ 1033 L_EVNT_DrvSdHorResetOpSta "25.02.03";
BA_ "Description" SG_ 1033 L_EVNT_DrvCntrVertResetOpSta "This signal indicates whether the reset operation has been completed or not";
BA_ "GenSigSendType" SG_ 1033 L_EVNT_DrvCntrVertResetOpSta 4;
BA_ "UserSigValidity" SG_ 1033 L_EVNT_DrvCntrVertResetOpSta 0;
BA_REL_ "GenSigTimeoutTime" BU_SG_REL_ L_ATCU SG_ 1033 L_EVNT_DrvCntrVertResetOpSta 1000;
BA_ "Version" SG_ 1033 L_EVNT_DrvCntrVertResetOpSta "25.02.03";
BA_ "Description" SG_ 1033 L_EVNT_DrvCntrHorResetOpSta "This signal indicates whether the reset operation has been completed or not";
BA_ "GenSigSendType" SG_ 1033 L_EVNT_DrvCntrHorResetOpSta 4;
BA_ "UserSigValidity" SG_ 1033 L_EVNT_DrvCntrHorResetOpSta 0;
BA_REL_ "GenSigTimeoutTime" BU_SG_REL_ L_ATCU SG_ 1033 L_EVNT_DrvCntrHorResetOpSta 1000;
BA_ "Version" SG_ 1033 L_EVNT_DrvCntrHorResetOpSta "25.02.03";
BA_ "Description" SG_ 1033 L_EVNT_AstSdVertResetOpSta "This signal indicates whether the reset operation has been completed or not";
BA_ "GenSigSendType" SG_ 1033 L_EVNT_AstSdVertResetOpSta 4;
BA_ "UserSigValidity" SG_ 1033 L_EVNT_AstSdVertResetOpSta 0;
BA_REL_ "GenSigTimeoutTime" BU_SG_REL_ L_ATCU SG_ 1033 L_EVNT_AstSdVertResetOpSta 1000;
BA_ "Version" SG_ 1033 L_EVNT_AstSdVertResetOpSta "25.02.03";
BA_ "Description" SG_ 1033 L_EVNT_AstSdHorResetOpSta "This signal indicates whether the reset operation has been completed or not";
BA_ "GenSigSendType" SG_ 1033 L_EVNT_AstSdHorResetOpSta 4;
BA_ "UserSigValidity" SG_ 1033 L_EVNT_AstSdHorResetOpSta 0;
BA_REL_ "GenSigTimeoutTime" BU_SG_REL_ L_ATCU SG_ 1033 L_EVNT_AstSdHorResetOpSta 1000;
BA_ "Version" SG_ 1033 L_EVNT_AstSdHorResetOpSta "25.02.03";
BA_ "Description" SG_ 1033 L_EVNT_AstCntrVertResetOpSta "This signal indicates whether the reset operation has been completed or not";
BA_ "GenSigSendType" SG_ 1033 L_EVNT_AstCntrVertResetOpSta 4;
BA_ "UserSigValidity" SG_ 1033 L_EVNT_AstCntrVertResetOpSta 0;
BA_REL_ "GenSigTimeoutTime" BU_SG_REL_ L_ATCU SG_ 1033 L_EVNT_AstCntrVertResetOpSta 1000;
BA_ "Version" SG_ 1033 L_EVNT_AstCntrVertResetOpSta "25.02.03";
BA_ "Description" SG_ 1033 L_EVNT_AstCntrHorResetOpSta "This signal indicates whether the reset operation has been completed or not";
BA_ "GenSigSendType" SG_ 1033 L_EVNT_AstCntrHorResetOpSta 4;
BA_ "UserSigValidity" SG_ 1033 L_EVNT_AstCntrHorResetOpSta 0;
BA_REL_ "GenSigTimeoutTime" BU_SG_REL_ L_ATCU SG_ 1033 L_EVNT_AstCntrHorResetOpSta 1000;
BA_ "Version" SG_ 1033 L_EVNT_AstCntrHorResetOpSta "25.02.03";
BA_ "Description" SG_ 1033 L_EVNT_RrDrvCnslVertResetOpSta "This signal indicates whether the reset operation has been completed or not";
BA_ "GenSigSendType" SG_ 1033 L_EVNT_RrDrvCnslVertResetOpSta 4;
BA_ "UserSigValidity" SG_ 1033 L_EVNT_RrDrvCnslVertResetOpSta 0;
BA_REL_ "GenSigTimeoutTime" BU_SG_REL_ L_ATCU SG_ 1033 L_EVNT_RrDrvCnslVertResetOpSta 1000;
BA_ "Version" SG_ 1033 L_EVNT_RrDrvCnslVertResetOpSta "25.02.03";
BA_ "Description" SG_ 1033 L_EVNT_RrDrvCnslHorResetOpSta "This signal indicates whether the reset operation has been completed or not";
BA_ "GenSigSendType" SG_ 1033 L_EVNT_RrDrvCnslHorResetOpSta 4;
BA_ "UserSigValidity" SG_ 1033 L_EVNT_RrDrvCnslHorResetOpSta 0;
BA_REL_ "GenSigTimeoutTime" BU_SG_REL_ L_ATCU SG_ 1033 L_EVNT_RrDrvCnslHorResetOpSta 1000;
BA_ "Version" SG_ 1033 L_EVNT_RrDrvCnslHorResetOpSta "25.02.03";
BA_ "Description" SG_ 1033 L_EVNT_RrAstCnslVertResetOpSta "This signal indicates whether the reset operation has been completed or not";
BA_ "GenSigSendType" SG_ 1033 L_EVNT_RrAstCnslVertResetOpSta 4;
BA_ "UserSigValidity" SG_ 1033 L_EVNT_RrAstCnslVertResetOpSta 0;
BA_REL_ "GenSigTimeoutTime" BU_SG_REL_ L_ATCU SG_ 1033 L_EVNT_RrAstCnslVertResetOpSta 1000;
BA_ "Version" SG_ 1033 L_EVNT_RrAstCnslVertResetOpSta "25.02.03";
BA_ "GenSigSendType" SG_ 1033 L_EVNT_RrDrvCnslHorExtFlt 4;
BA_ "UserSigValidity" SG_ 1033 L_EVNT_RrDrvCnslHorExtFlt 7;
BA_REL_ "GenSigTimeoutTime" BU_SG_REL_ L_ATCU SG_ 1033 L_EVNT_RrDrvCnslHorExtFlt 5000;
BA_ "Version" SG_ 1033 L_EVNT_RrDrvCnslHorExtFlt "24.05.11";
BA_ "Description" SG_ 1033 L_EVNT_RrAstCnslHorResetOpSta "This signal indicates whether the reset operation has been completed or not";
BA_ "GenSigSendType" SG_ 1033 L_EVNT_RrAstCnslHorResetOpSta 4;
BA_ "UserSigValidity" SG_ 1033 L_EVNT_RrAstCnslHorResetOpSta 0;
BA_REL_ "GenSigTimeoutTime" BU_SG_REL_ L_ATCU SG_ 1033 L_EVNT_RrAstCnslHorResetOpSta 1000;
BA_ "Version" SG_ 1033 L_EVNT_RrAstCnslHorResetOpSta "25.02.03";
BA_ "Description" SG_ 1033 L_EVNT_ResetOpSta "This signal indicates whether the reset operation has been completed or not";
BA_ "GenSigSendType" SG_ 1033 L_EVNT_ResetOpSta 4;
BA_ "UserSigValidity" SG_ 1033 L_EVNT_ResetOpSta 0;
BA_REL_ "GenSigTimeoutTime" BU_SG_REL_ L_ATCU SG_ 1033 L_EVNT_ResetOpSta 1000;
BA_ "Version" SG_ 1033 L_EVNT_ResetOpSta "24.10.05";
BA_ "GenSigSendType" SG_ 1033 L_EVNT_RrAstCnslVertExtFlt 4;
BA_ "UserSigValidity" SG_ 1033 L_EVNT_RrAstCnslVertExtFlt 7;
BA_REL_ "GenSigTimeoutTime" BU_SG_REL_ L_ATCU SG_ 1033 L_EVNT_RrAstCnslVertExtFlt 5000;
BA_ "Version" SG_ 1033 L_EVNT_RrAstCnslVertExtFlt "24.05.11";
BA_ "GenMsgSendType" BO_ 326 0;
BA_ "GenMsgCycleTime" BO_ 326 20;
BA_ "GenMsgCycleTimeFast" BO_ 326 0;
BA_ "GenMsgNrOfRepetition" BO_ 326 0;
BA_ "GenMsgDelayTime" BO_ 326 0;
BA_ "UserSigValidity" SG_ 326 FHPTC_2ndPsRdySta 7;
BA_ "Version" SG_ 326 FHPTC_2ndPsRdySta "24.02.06";
BA_ "UserSigValidity" SG_ 326 FHPTC_2ndPsOpSta 7;
BA_ "Version" SG_ 326 FHPTC_2ndPsOpSta "24.02.06";
BA_ "UserSigValidity" SG_ 326 FHPTC_2ndPsCnsmptPwr_W 7;
BA_ "Version" SG_ 326 FHPTC_2ndPsCnsmptPwr_W "24.02.06";
BA_ "UserSigValidity" SG_ 326 FHPTC_2ndPsCtrlTyp 7;
BA_ "Version" SG_ 326 FHPTC_2ndPsCtrlTyp "24.02.06";
BA_ "UserSigValidity" SG_ 326 FHPTC_2ndPsVoltage_V 7;
BA_ "Version" SG_ 326 FHPTC_2ndPsVoltage_V "24.02.06";
BA_ "UserSigValidity" SG_ 326 FHPTC_2ndPsCurrent_A 7;
BA_ "Version" SG_ 326 FHPTC_2ndPsCurrent_A "24.02.06";
BA_ "Description" SG_ 326 FHPTC_2ndPsDutyFB_Pec "Duty Conversion to PTC Consumption power value, 40w~6kw -> 10%~95%";
BA_ "UserSigValidity" SG_ 326 FHPTC_2ndPsDutyFB_Pec 7;
BA_ "Version" SG_ 326 FHPTC_2ndPsDutyFB_Pec "24.02.06";
BA_ "Description" SG_ 326 FHPTC_2ndPsDutyFB_IGBT "PWM DUTY of PTC IGBT (0~100%)";
BA_ "UserSigValidity" SG_ 326 FHPTC_2ndPsDutyFB_IGBT 7;
BA_ "Version" SG_ 326 FHPTC_2ndPsDutyFB_IGBT "24.02.06";
BA_ "UserSigValidity" SG_ 326 FHPTC_2ndPsCoreTemp_C 7;
BA_ "Version" SG_ 326 FHPTC_2ndPsCoreTemp_C "24.02.06";
BA_ "GenMsgSendType" BO_ 65 0;
BA_ "GenMsgCycleTime" BO_ 65 500;
BA_ "Description" SG_ 65 HKBD_Typ1 "Bit0 (Climate Display Side):0 ? Left Side /1 ? Right Side

Bit1 (LCD/NON LCD TYPE): 0- NON LCD/1- LCD TYPE

Bit2~3 (Button Type):0 - HardKey (Push-Return)/1- Touch/2- HardKey + Touch/3 - RESERVED 

Bit4~5 (Button Arragement Type):0 ? Single (Blower-Temp-Mode)/1 ? Single (Temp-Mode-Blower)/2 ? Dual ¡¤ 3zone ¡¤ 4zone¡¤Etc. /3 - RESERVED 

Bit6~7 (Mode Button):0 ? 1 Button/1 ?  2 Button/2 ? 3 Button";
BA_ "GenSigSendType" SG_ 65 HKBD_Typ1 4;
BA_ "UserSigValidity" SG_ 65 HKBD_Typ1 7;
BA_REL_ "GenSigTimeoutTime" BU_SG_REL_ L_ATCU SG_ 65 HKBD_Typ1 5000;
BA_ "Version" SG_ 65 HKBD_Typ1 "23.08.13";
BA_ "Description" SG_ 65 HKBD_Typ2 "Bit0 (Mode Def Type):0 ? Symbol Type/1 ? Arrow Type

Bit1 (Air Purifier Button):0 - None/1 - AIR PURIFIER BUTTON APPLIED

Bit2 (Haptic):0 - None/1 - Applied 

Bit3 (Multi Auto Button Type) :  0 - Push / 1 - Tumbler 

Bit4~ 5 (Climate OSD UI Type) : 0 - None (Basic UI Type) / 1 - (TEMP-Blower - Mode - Temp) / 2 - (Temp - Mode (Auto) - Blower - Temp) / 3 - Reserved 

Bit6~7 (Blower Button Type) : 0 - None / 1 - Blower down type / 2 - blower down off type / 3 - Invalid";
BA_ "GenSigSendType" SG_ 65 HKBD_Typ2 4;
BA_ "UserSigValidity" SG_ 65 HKBD_Typ2 7;
BA_REL_ "GenSigTimeoutTime" BU_SG_REL_ L_ATCU SG_ 65 HKBD_Typ2 5000;
BA_ "Version" SG_ 65 HKBD_Typ2 "24.02.01";
BA_ "Description" SG_ 65 HKBD_Typ3 "Bit0~1 : RESERVED

Bit2~3 (Front Multi Auto Text):0 - Multi Auto State Text Not Applied/1 - Multi Auto State Text Display Only Applied/2 - Multi Auto State Text Display & Control Applied/3 ? RESERVED

Bit4~5 : RESERVED

Bit6~7 (Pass Multi Auto Text):0 - Multi Auto State Text Not Applied/1 - Multi Auto State Text Display Only Applied/2 - Multi Auto State Text Display & Control Applied/3 ? RESERVED";
BA_ "GenSigSendType" SG_ 65 HKBD_Typ3 4;
BA_ "UserSigValidity" SG_ 65 HKBD_Typ3 7;
BA_REL_ "GenSigTimeoutTime" BU_SG_REL_ L_ATCU SG_ 65 HKBD_Typ3 5000;
BA_ "Version" SG_ 65 HKBD_Typ3 "24.02.01";
BA_ "GenSigSendType" SG_ 65 HKBD_SW_Ver1 4;
BA_ "UserSigValidity" SG_ 65 HKBD_SW_Ver1 7;
BA_REL_ "GenSigTimeoutTime" BU_SG_REL_ L_ATCU_vMON SG_ 65 HKBD_SW_Ver1 5000;
BA_ "Version" SG_ 65 HKBD_SW_Ver1 "25.05.04";
BA_ "GenSigSendType" SG_ 65 HKBD_SW_Ver2 4;
BA_ "UserSigValidity" SG_ 65 HKBD_SW_Ver2 7;
BA_REL_ "GenSigTimeoutTime" BU_SG_REL_ L_ATCU_vMON SG_ 65 HKBD_SW_Ver2 5000;
BA_ "Version" SG_ 65 HKBD_SW_Ver2 "25.05.04";
BA_ "GenSigSendType" SG_ 65 HKBD_SW_Ver3 4;
BA_ "UserSigValidity" SG_ 65 HKBD_SW_Ver3 7;
BA_REL_ "GenSigTimeoutTime" BU_SG_REL_ L_ATCU_vMON SG_ 65 HKBD_SW_Ver3 5000;
BA_ "Version" SG_ 65 HKBD_SW_Ver3 "25.05.04";
BA_ "GenMsgSendType" BO_ 66 0;
BA_ "GenSigSendType" SG_ 66 HKBD_Fr_DrModDnSw 4;
BA_ "UserSigValidity" SG_ 66 HKBD_Fr_DrModDnSw 7;
BA_REL_ "GenSigTimeoutTime" BU_SG_REL_ L_ATCU SG_ 66 HKBD_Fr_DrModDnSw 1500;
BA_ "Version" SG_ 66 HKBD_Fr_DrModDnSw "23.08.13";
BA_ "GenSigSendType" SG_ 66 HKBD_Fr_DrModUpSw 4;
BA_ "UserSigValidity" SG_ 66 HKBD_Fr_DrModUpSw 7;
BA_REL_ "GenSigTimeoutTime" BU_SG_REL_ L_ATCU SG_ 66 HKBD_Fr_DrModUpSw 1500;
BA_ "Version" SG_ 66 HKBD_Fr_DrModUpSw "23.08.13";
BA_ "GenSigSendType" SG_ 66 HKBD_Fr_DrMultiAutoSw 4;
BA_ "GenSigStartValue" SG_ 66 HKBD_Fr_DrMultiAutoSw 7;
BA_ "UserSigValidity" SG_ 66 HKBD_Fr_DrMultiAutoSw 7;
BA_REL_ "GenSigTimeoutTime" BU_SG_REL_ L_ATCU SG_ 66 HKBD_Fr_DrMultiAutoSw 1500;
BA_ "Version" SG_ 66 HKBD_Fr_DrMultiAutoSw "24.05.08";
BA_ "GenSigSendType" SG_ 66 HKBD_Fr_PsAutoSw 4;
BA_ "UserSigValidity" SG_ 66 HKBD_Fr_PsAutoSw 7;
BA_REL_ "GenSigTimeoutTime" BU_SG_REL_ L_ATCU SG_ 66 HKBD_Fr_PsAutoSw 1500;
BA_ "Version" SG_ 66 HKBD_Fr_PsAutoSw "23.08.13";
BA_ "GenSigSendType" SG_ 66 HKBD_Fr_PsMultiAutoSw 4;
BA_ "GenSigStartValue" SG_ 66 HKBD_Fr_PsMultiAutoSw 7;
BA_ "UserSigValidity" SG_ 66 HKBD_Fr_PsMultiAutoSw 7;
BA_REL_ "GenSigTimeoutTime" BU_SG_REL_ L_ATCU SG_ 66 HKBD_Fr_PsMultiAutoSw 1500;
BA_ "Version" SG_ 66 HKBD_Fr_PsMultiAutoSw "24.05.08";
BA_ "GenSigSendType" SG_ 66 HKBD_Fr_AcSw 4;
BA_ "UserSigValidity" SG_ 66 HKBD_Fr_AcSw 7;
BA_REL_ "GenSigTimeoutTime" BU_SG_REL_ L_ATCU SG_ 66 HKBD_Fr_AcSw 1500;
BA_ "Version" SG_ 66 HKBD_Fr_AcSw "23.08.13";
BA_ "GenSigSendType" SG_ 66 HKBD_Fr_DefSw 4;
BA_ "UserSigValidity" SG_ 66 HKBD_Fr_DefSw 7;
BA_REL_ "GenSigTimeoutTime" BU_SG_REL_ L_ATCU SG_ 66 HKBD_Fr_DefSw 1500;
BA_ "Version" SG_ 66 HKBD_Fr_DefSw "23.08.13";
BA_ "GenSigSendType" SG_ 66 HKBD_Fr_RecSw 4;
BA_ "UserSigValidity" SG_ 66 HKBD_Fr_RecSw 7;
BA_REL_ "GenSigTimeoutTime" BU_SG_REL_ L_ATCU SG_ 66 HKBD_Fr_RecSw 1500;
BA_ "Version" SG_ 66 HKBD_Fr_RecSw "23.08.13";
BA_ "GenSigSendType" SG_ 66 HKBD_Fr_DrModVntSw 4;
BA_ "UserSigValidity" SG_ 66 HKBD_Fr_DrModVntSw 7;
BA_REL_ "GenSigTimeoutTime" BU_SG_REL_ L_ATCU SG_ 66 HKBD_Fr_DrModVntSw 1500;
BA_ "Version" SG_ 66 HKBD_Fr_DrModVntSw "23.08.13";
BA_ "GenSigSendType" SG_ 66 HKBD_Fr_FreSw 4;
BA_ "UserSigValidity" SG_ 66 HKBD_Fr_FreSw 7;
BA_REL_ "GenSigTimeoutTime" BU_SG_REL_ L_ATCU SG_ 66 HKBD_Fr_FreSw 1500;
BA_ "Version" SG_ 66 HKBD_Fr_FreSw "23.08.13";
BA_ "GenSigSendType" SG_ 66 HKBD_Fr_IntakeTglSw 4;
BA_ "UserSigValidity" SG_ 66 HKBD_Fr_IntakeTglSw 7;
BA_REL_ "GenSigTimeoutTime" BU_SG_REL_ L_ATCU SG_ 66 HKBD_Fr_IntakeTglSw 1500;
BA_ "Version" SG_ 66 HKBD_Fr_IntakeTglSw "23.08.13";
BA_ "GenSigSendType" SG_ 66 HKBD_Fr_OffSw 4;
BA_ "UserSigValidity" SG_ 66 HKBD_Fr_OffSw 7;
BA_REL_ "GenSigTimeoutTime" BU_SG_REL_ L_ATCU SG_ 66 HKBD_Fr_OffSw 1500;
BA_ "Version" SG_ 66 HKBD_Fr_OffSw "23.08.13";
BA_ "GenSigSendType" SG_ 66 HKBD_Fr_SyncSw 4;
BA_ "UserSigValidity" SG_ 66 HKBD_Fr_SyncSw 7;
BA_REL_ "GenSigTimeoutTime" BU_SG_REL_ L_ATCU SG_ 66 HKBD_Fr_SyncSw 1500;
BA_ "Version" SG_ 66 HKBD_Fr_SyncSw "23.08.13";
BA_ "GenSigSendType" SG_ 66 HKBD_Fr_RrDefInd 4;
BA_ "UserSigValidity" SG_ 66 HKBD_Fr_RrDefInd 7;
BA_REL_ "GenSigTimeoutTime" BU_SG_REL_ L_ATCU SG_ 66 HKBD_Fr_RrDefInd 1500;
BA_ "Version" SG_ 66 HKBD_Fr_RrDefInd "23.08.13";
BA_ "GenSigSendType" SG_ 66 HKBD_Fr_RrDefSw 4;
BA_ "UserSigValidity" SG_ 66 HKBD_Fr_RrDefSw 7;
BA_REL_ "GenSigTimeoutTime" BU_SG_REL_ L_ATCU SG_ 66 HKBD_Fr_RrDefSw 1500;
BA_ "Version" SG_ 66 HKBD_Fr_RrDefSw "23.08.13";
BA_ "GenSigSendType" SG_ 66 HKBD_Fr_ArclnSw 4;
BA_ "UserSigValidity" SG_ 66 HKBD_Fr_ArclnSw 7;
BA_REL_ "GenSigTimeoutTime" BU_SG_REL_ L_ATCU SG_ 66 HKBD_Fr_ArclnSw 1500;
BA_ "Version" SG_ 66 HKBD_Fr_ArclnSw "23.08.13";
BA_ "GenSigSendType" SG_ 66 HKBD_Fr_DrOnlySw 4;
BA_ "UserSigValidity" SG_ 66 HKBD_Fr_DrOnlySw 7;
BA_REL_ "GenSigTimeoutTime" BU_SG_REL_ L_ATCU SG_ 66 HKBD_Fr_DrOnlySw 1500;
BA_ "Version" SG_ 66 HKBD_Fr_DrOnlySw "23.08.13";
BA_ "GenSigSendType" SG_ 66 HKBD_Fr_ClimateSw 4;
BA_ "UserSigValidity" SG_ 66 HKBD_Fr_ClimateSw 7;
BA_REL_ "GenSigTimeoutTime" BU_SG_REL_ L_ATCU SG_ 66 HKBD_Fr_ClimateSw 1500;
BA_ "Version" SG_ 66 HKBD_Fr_ClimateSw "23.08.13";
BA_ "GenSigSendType" SG_ 66 HKBD_Fr_PerfumeSw 4;
BA_ "UserSigValidity" SG_ 66 HKBD_Fr_PerfumeSw 7;
BA_REL_ "GenSigTimeoutTime" BU_SG_REL_ L_ATCU SG_ 66 HKBD_Fr_PerfumeSw 1500;
BA_ "Version" SG_ 66 HKBD_Fr_PerfumeSw "23.08.13";
BA_ "GenSigSendType" SG_ 66 HKBD_Fr_DrModFlrSw 4;
BA_ "UserSigValidity" SG_ 66 HKBD_Fr_DrModFlrSw 7;
BA_REL_ "GenSigTimeoutTime" BU_SG_REL_ L_ATCU SG_ 66 HKBD_Fr_DrModFlrSw 1500;
BA_ "Version" SG_ 66 HKBD_Fr_DrModFlrSw "23.08.13";
BA_ "GenSigSendType" SG_ 66 HKBD_Fr_HptIntnstySta 4;
BA_ "UserSigValidity" SG_ 66 HKBD_Fr_HptIntnstySta 7;
BA_REL_ "GenSigTimeoutTime" BU_SG_REL_ L_ATCU SG_ 66 HKBD_Fr_HptIntnstySta 1500;
BA_ "Version" SG_ 66 HKBD_Fr_HptIntnstySta "23.11.06";
BA_ "GenSigSendType" SG_ 66 HKBD_Fr_StrWhlHeatSw 4;
BA_ "UserSigValidity" SG_ 66 HKBD_Fr_StrWhlHeatSw 7;
BA_REL_ "GenSigTimeoutTime" BU_SG_REL_ L_ATCU SG_ 66 HKBD_Fr_StrWhlHeatSw 1500;
BA_ "Version" SG_ 66 HKBD_Fr_StrWhlHeatSw "23.08.13";
BA_ "GenSigSendType" SG_ 66 HKBD_FLStHeatSw 4;
BA_ "UserSigValidity" SG_ 66 HKBD_FLStHeatSw 7;
BA_REL_ "GenSigTimeoutTime" BU_SG_REL_ L_ATCU SG_ 66 HKBD_FLStHeatSw 1500;
BA_ "Version" SG_ 66 HKBD_FLStHeatSw "23.08.13";
BA_ "GenSigSendType" SG_ 66 HKBD_FLStVentSw 4;
BA_ "UserSigValidity" SG_ 66 HKBD_FLStVentSw 7;
BA_REL_ "GenSigTimeoutTime" BU_SG_REL_ L_ATCU SG_ 66 HKBD_FLStVentSw 1500;
BA_ "Version" SG_ 66 HKBD_FLStVentSw "23.08.13";
BA_ "GenSigSendType" SG_ 66 HKBD_FRStHeatSw 4;
BA_ "UserSigValidity" SG_ 66 HKBD_FRStHeatSw 7;
BA_REL_ "GenSigTimeoutTime" BU_SG_REL_ L_ATCU SG_ 66 HKBD_FRStHeatSw 1500;
BA_ "Version" SG_ 66 HKBD_FRStHeatSw "23.08.13";
BA_ "GenSigSendType" SG_ 66 HKBD_FRStVentSw 4;
BA_ "UserSigValidity" SG_ 66 HKBD_FRStVentSw 7;
BA_REL_ "GenSigTimeoutTime" BU_SG_REL_ L_ATCU SG_ 66 HKBD_FRStVentSw 1500;
BA_ "Version" SG_ 66 HKBD_FRStVentSw "23.08.13";
BA_ "GenSigSendType" SG_ 66 HKBD_FLStTumblrSw 4;
BA_ "UserSigValidity" SG_ 66 HKBD_FLStTumblrSw 7;
BA_REL_ "GenSigTimeoutTime" BU_SG_REL_ L_ATCU SG_ 66 HKBD_FLStTumblrSw 1500;
BA_ "Version" SG_ 66 HKBD_FLStTumblrSw "23.08.13";
BA_ "GenSigSendType" SG_ 66 HKBD_Fr_DrModDefSw 4;
BA_ "UserSigValidity" SG_ 66 HKBD_Fr_DrModDefSw 7;
BA_REL_ "GenSigTimeoutTime" BU_SG_REL_ L_ATCU SG_ 66 HKBD_Fr_DrModDefSw 1500;
BA_ "Version" SG_ 66 HKBD_Fr_DrModDefSw "23.08.13";
BA_ "GenSigSendType" SG_ 66 HKBD_FRStTumblrSw 4;
BA_ "UserSigValidity" SG_ 66 HKBD_FRStTumblrSw 7;
BA_REL_ "GenSigTimeoutTime" BU_SG_REL_ L_ATCU SG_ 66 HKBD_FRStTumblrSw 1500;
BA_ "Version" SG_ 66 HKBD_FRStTumblrSw "23.08.13";
BA_ "GenSigSendType" SG_ 66 HKBD_Fr_FrWndShldHtSw 4;
BA_ "UserSigValidity" SG_ 66 HKBD_Fr_FrWndShldHtSw 7;
BA_REL_ "GenSigTimeoutTime" BU_SG_REL_ L_ATCU SG_ 66 HKBD_Fr_FrWndShldHtSw 1500;
BA_ "Version" SG_ 66 HKBD_Fr_FrWndShldHtSw "23.08.13";
BA_ "Description" SG_ 66 HKBD_Fr_DrAutoDnSw "This signal should be used for tumbler type AUTO switch";
BA_ "GenSigSendType" SG_ 66 HKBD_Fr_DrAutoDnSw 4;
BA_ "UserSigValidity" SG_ 66 HKBD_Fr_DrAutoDnSw 7;
BA_REL_ "GenSigTimeoutTime" BU_SG_REL_ L_ATCU SG_ 66 HKBD_Fr_DrAutoDnSw 1500;
BA_ "Version" SG_ 66 HKBD_Fr_DrAutoDnSw "23.08.13";
BA_ "Description" SG_ 66 HKBD_Fr_DrAutoUpSw "This signal should be used for tumbler type AUTO switch";
BA_ "GenSigSendType" SG_ 66 HKBD_Fr_DrAutoUpSw 4;
BA_ "UserSigValidity" SG_ 66 HKBD_Fr_DrAutoUpSw 7;
BA_REL_ "GenSigTimeoutTime" BU_SG_REL_ L_ATCU SG_ 66 HKBD_Fr_DrAutoUpSw 1500;
BA_ "Version" SG_ 66 HKBD_Fr_DrAutoUpSw "23.08.13";
BA_ "GenSigSendType" SG_ 66 HKBD_Fr_DrModSw 4;
BA_ "UserSigValidity" SG_ 66 HKBD_Fr_DrModSw 7;
BA_REL_ "GenSigTimeoutTime" BU_SG_REL_ L_ATCU SG_ 66 HKBD_Fr_DrModSw 1500;
BA_ "Version" SG_ 66 HKBD_Fr_DrModSw "23.08.13";
BA_ "GenSigSendType" SG_ 66 HKBD_Fr_PsModSw 4;
BA_ "UserSigValidity" SG_ 66 HKBD_Fr_PsModSw 7;
BA_REL_ "GenSigTimeoutTime" BU_SG_REL_ L_ATCU SG_ 66 HKBD_Fr_PsModSw 1500;
BA_ "Version" SG_ 66 HKBD_Fr_PsModSw "23.08.13";
BA_ "Description" SG_ 66 HKBD_DisplayTheme "Feedback for the HKBD Display Theme state information";
BA_ "GenSigSendType" SG_ 66 HKBD_DisplayTheme 4;
BA_ "GenSigStartValue" SG_ 66 HKBD_DisplayTheme 3;
BA_ "UserSigValidity" SG_ 66 HKBD_DisplayTheme 7;
BA_REL_ "GenSigTimeoutTime" BU_SG_REL_ L_ATCU SG_ 66 HKBD_DisplayTheme 1500;
BA_ "Version" SG_ 66 HKBD_DisplayTheme "24.01.00";
BA_ "GenSigSendType" SG_ 66 HKBD_Fr_PsModDnSw 4;
BA_ "UserSigValidity" SG_ 66 HKBD_Fr_PsModDnSw 7;
BA_REL_ "GenSigTimeoutTime" BU_SG_REL_ L_ATCU SG_ 66 HKBD_Fr_PsModDnSw 1500;
BA_ "Version" SG_ 66 HKBD_Fr_PsModDnSw "23.08.13";
BA_ "Description" SG_ 66 HKBD_Fr_SmartZoneSW "Smart HVAC SmartZone indicator on/off signal";
BA_ "GenSigSendType" SG_ 66 HKBD_Fr_SmartZoneSW 4;
BA_ "UserSigValidity" SG_ 66 HKBD_Fr_SmartZoneSW 7;
BA_REL_ "GenSigTimeoutTime" BU_SG_REL_ L_ATCU SG_ 66 HKBD_Fr_SmartZoneSW 1500;
BA_ "Version" SG_ 66 HKBD_Fr_SmartZoneSW "24.11.00";
BA_ "GenSigSendType" SG_ 66 HKBD_Fr_ModSet 4;
BA_ "UserSigValidity" SG_ 66 HKBD_Fr_ModSet 7;
BA_REL_ "GenSigTimeoutTime" BU_SG_REL_ L_ATCU SG_ 66 HKBD_Fr_ModSet 1500;
BA_ "Version" SG_ 66 HKBD_Fr_ModSet "25.05.04";
BA_ "GenSigSendType" SG_ 66 HKBD_Fr_MTCTempLvlSet 4;
BA_ "UserSigValidity" SG_ 66 HKBD_Fr_MTCTempLvlSet 7;
BA_REL_ "GenSigTimeoutTime" BU_SG_REL_ L_ATCU SG_ 66 HKBD_Fr_MTCTempLvlSet 1500;
BA_ "Version" SG_ 66 HKBD_Fr_MTCTempLvlSet "25.05.04";
BA_ "GenSigSendType" SG_ 66 HKBD_Fr_PsModUpSw 4;
BA_ "UserSigValidity" SG_ 66 HKBD_Fr_PsModUpSw 7;
BA_REL_ "GenSigTimeoutTime" BU_SG_REL_ L_ATCU SG_ 66 HKBD_Fr_PsModUpSw 1500;
BA_ "Version" SG_ 66 HKBD_Fr_PsModUpSw "23.08.13";
BA_ "GenSigSendType" SG_ 66 HKBD_Fr_PsModVntSw 4;
BA_ "UserSigValidity" SG_ 66 HKBD_Fr_PsModVntSw 7;
BA_REL_ "GenSigTimeoutTime" BU_SG_REL_ L_ATCU SG_ 66 HKBD_Fr_PsModVntSw 1500;
BA_ "Version" SG_ 66 HKBD_Fr_PsModVntSw "23.08.13";
BA_ "GenSigSendType" SG_ 66 HKBD_Fr_PsModFlrSw 4;
BA_ "UserSigValidity" SG_ 66 HKBD_Fr_PsModFlrSw 7;
BA_REL_ "GenSigTimeoutTime" BU_SG_REL_ L_ATCU SG_ 66 HKBD_Fr_PsModFlrSw 1500;
BA_ "Version" SG_ 66 HKBD_Fr_PsModFlrSw "23.08.13";
BA_ "GenSigSendType" SG_ 66 HKBD_Fr_DrAutoSw 4;
BA_ "UserSigValidity" SG_ 66 HKBD_Fr_DrAutoSw 7;
BA_REL_ "GenSigTimeoutTime" BU_SG_REL_ L_ATCU SG_ 66 HKBD_Fr_DrAutoSw 1500;
BA_ "Version" SG_ 66 HKBD_Fr_DrAutoSw "23.08.13";
BA_ "GenMsgCycleTime" BO_ 67 0;
BA_ "GenSigSendType" SG_ 67 HKBD_Fr_DrTempClickCnt 4;
BA_ "GenSigStartValue" SG_ 67 HKBD_Fr_DrTempClickCnt 255;
BA_ "UserSigValidity" SG_ 67 HKBD_Fr_DrTempClickCnt 7;
BA_REL_ "GenSigTimeoutTime" BU_SG_REL_ L_ATCU SG_ 67 HKBD_Fr_DrTempClickCnt 0;
BA_ "Version" SG_ 67 HKBD_Fr_DrTempClickCnt "24.05.08";
BA_ "GenSigSendType" SG_ 67 HKBD_Fr_RrTempClickCnt 4;
BA_ "GenSigStartValue" SG_ 67 HKBD_Fr_RrTempClickCnt 255;
BA_ "UserSigValidity" SG_ 67 HKBD_Fr_RrTempClickCnt 7;
BA_REL_ "GenSigTimeoutTime" BU_SG_REL_ L_ATCU SG_ 67 HKBD_Fr_RrTempClickCnt 0;
BA_ "Version" SG_ 67 HKBD_Fr_RrTempClickCnt "24.05.08";
BA_ "GenSigSendType" SG_ 67 HKBD_Fr_DrBlwClickCnt 4;
BA_ "GenSigStartValue" SG_ 67 HKBD_Fr_DrBlwClickCnt 255;
BA_ "UserSigValidity" SG_ 67 HKBD_Fr_DrBlwClickCnt 7;
BA_REL_ "GenSigTimeoutTime" BU_SG_REL_ L_ATCU SG_ 67 HKBD_Fr_DrBlwClickCnt 0;
BA_ "Version" SG_ 67 HKBD_Fr_DrBlwClickCnt "24.05.08";
BA_ "GenSigSendType" SG_ 67 HKBD_Fr_PsBlwClickCnt 4;
BA_ "GenSigStartValue" SG_ 67 HKBD_Fr_PsBlwClickCnt 255;
BA_ "UserSigValidity" SG_ 67 HKBD_Fr_PsBlwClickCnt 7;
BA_REL_ "GenSigTimeoutTime" BU_SG_REL_ L_ATCU SG_ 67 HKBD_Fr_PsBlwClickCnt 0;
BA_ "Version" SG_ 67 HKBD_Fr_PsBlwClickCnt "24.05.08";
BA_ "GenSigSendType" SG_ 67 HKBD_FrTempKnobCnt 4;
BA_ "GenSigStartValue" SG_ 67 HKBD_FrTempKnobCnt 3;
BA_ "UserSigValidity" SG_ 67 HKBD_FrTempKnobCnt 7;
BA_REL_ "GenSigTimeoutTime" BU_SG_REL_ L_ATCU SG_ 67 HKBD_FrTempKnobCnt 0;
BA_ "Version" SG_ 67 HKBD_FrTempKnobCnt "24.05.08";
BA_ "GenSigSendType" SG_ 67 HKBD_FrBlwKnobCnt 4;
BA_ "GenSigStartValue" SG_ 67 HKBD_FrBlwKnobCnt 3;
BA_ "UserSigValidity" SG_ 67 HKBD_FrBlwKnobCnt 7;
BA_REL_ "GenSigTimeoutTime" BU_SG_REL_ L_ATCU SG_ 67 HKBD_FrBlwKnobCnt 0;
BA_ "Version" SG_ 67 HKBD_FrBlwKnobCnt "24.05.08";
BA_ "GenSigSendType" SG_ 67 HKBD_Fr_PsTempClickCnt 4;
BA_ "GenSigStartValue" SG_ 67 HKBD_Fr_PsTempClickCnt 255;
BA_ "UserSigValidity" SG_ 67 HKBD_Fr_PsTempClickCnt 7;
BA_REL_ "GenSigTimeoutTime" BU_SG_REL_ L_ATCU SG_ 67 HKBD_Fr_PsTempClickCnt 0;
BA_ "Version" SG_ 67 HKBD_Fr_PsTempClickCnt "24.05.08";
BA_ "GenMsgSendType" BO_ 68 0;
BA_ "GenSigSendType" SG_ 68 HKBD_Fr_DrTempDnSw 4;
BA_ "UserSigValidity" SG_ 68 HKBD_Fr_DrTempDnSw 7;
BA_REL_ "GenSigTimeoutTime" BU_SG_REL_ L_ATCU SG_ 68 HKBD_Fr_DrTempDnSw 1500;
BA_ "Version" SG_ 68 HKBD_Fr_DrTempDnSw "23.08.13";
BA_ "GenSigSendType" SG_ 68 HKBD_Fr_DrTempUpSw 4;
BA_ "UserSigValidity" SG_ 68 HKBD_Fr_DrTempUpSw 7;
BA_REL_ "GenSigTimeoutTime" BU_SG_REL_ L_ATCU SG_ 68 HKBD_Fr_DrTempUpSw 1500;
BA_ "Version" SG_ 68 HKBD_Fr_DrTempUpSw "23.08.13";
BA_ "GenSigSendType" SG_ 68 HKBD_Fr_PsBlwDnSw 4;
BA_ "UserSigValidity" SG_ 68 HKBD_Fr_PsBlwDnSw 7;
BA_REL_ "GenSigTimeoutTime" BU_SG_REL_ L_ATCU SG_ 68 HKBD_Fr_PsBlwDnSw 1500;
BA_ "Version" SG_ 68 HKBD_Fr_PsBlwDnSw "23.08.13";
BA_ "GenSigSendType" SG_ 68 HKBD_Fr_PsBlwDnOffSw 4;
BA_ "UserSigValidity" SG_ 68 HKBD_Fr_PsBlwDnOffSw 7;
BA_REL_ "GenSigTimeoutTime" BU_SG_REL_ L_ATCU SG_ 68 HKBD_Fr_PsBlwDnOffSw 1500;
BA_ "Version" SG_ 68 HKBD_Fr_PsBlwDnOffSw "23.08.13";
BA_ "GenSigSendType" SG_ 68 HKBD_Fr_PsBlwUpSw 4;
BA_ "UserSigValidity" SG_ 68 HKBD_Fr_PsBlwUpSw 7;
BA_REL_ "GenSigTimeoutTime" BU_SG_REL_ L_ATCU SG_ 68 HKBD_Fr_PsBlwUpSw 1500;
BA_ "Version" SG_ 68 HKBD_Fr_PsBlwUpSw "23.08.13";
BA_ "GenSigSendType" SG_ 68 HKBD_Fr_PsBlwSet 4;
BA_ "GenSigStartValue" SG_ 68 HKBD_Fr_PsBlwSet 15;
BA_ "UserSigValidity" SG_ 68 HKBD_Fr_PsBlwSet 7;
BA_REL_ "GenSigTimeoutTime" BU_SG_REL_ L_ATCU SG_ 68 HKBD_Fr_PsBlwSet 1500;
BA_ "Version" SG_ 68 HKBD_Fr_PsBlwSet "23.12.02";
BA_ "GenSigSendType" SG_ 68 HKBD_Fr_RrDrTempDnSw 4;
BA_ "UserSigValidity" SG_ 68 HKBD_Fr_RrDrTempDnSw 7;
BA_REL_ "GenSigTimeoutTime" BU_SG_REL_ L_ATCU SG_ 68 HKBD_Fr_RrDrTempDnSw 1500;
BA_ "Version" SG_ 68 HKBD_Fr_RrDrTempDnSw "23.08.13";
BA_ "GenSigSendType" SG_ 68 HKBD_Fr_RrDrTempUpSw 4;
BA_ "UserSigValidity" SG_ 68 HKBD_Fr_RrDrTempUpSw 7;
BA_REL_ "GenSigTimeoutTime" BU_SG_REL_ L_ATCU SG_ 68 HKBD_Fr_RrDrTempUpSw 1500;
BA_ "Version" SG_ 68 HKBD_Fr_RrDrTempUpSw "23.08.13";
BA_ "GenSigSendType" SG_ 68 HKBD_Fr_PsTempDnSw 4;
BA_ "UserSigValidity" SG_ 68 HKBD_Fr_PsTempDnSw 7;
BA_REL_ "GenSigTimeoutTime" BU_SG_REL_ L_ATCU SG_ 68 HKBD_Fr_PsTempDnSw 1500;
BA_ "Version" SG_ 68 HKBD_Fr_PsTempDnSw "23.08.13";
BA_ "GenSigSendType" SG_ 68 HKBD_Fr_RrDrBlwDnSw 4;
BA_ "UserSigValidity" SG_ 68 HKBD_Fr_RrDrBlwDnSw 7;
BA_REL_ "GenSigTimeoutTime" BU_SG_REL_ L_ATCU SG_ 68 HKBD_Fr_RrDrBlwDnSw 1500;
BA_ "Version" SG_ 68 HKBD_Fr_RrDrBlwDnSw "23.08.13";
BA_ "GenSigSendType" SG_ 68 HKBD_Fr_RrDrBlwDnOffSw 4;
BA_ "UserSigValidity" SG_ 68 HKBD_Fr_RrDrBlwDnOffSw 7;
BA_REL_ "GenSigTimeoutTime" BU_SG_REL_ L_ATCU SG_ 68 HKBD_Fr_RrDrBlwDnOffSw 1500;
BA_ "Version" SG_ 68 HKBD_Fr_RrDrBlwDnOffSw "23.08.13";
BA_ "GenSigSendType" SG_ 68 HKBD_Fr_RrDrBlwUpSw 4;
BA_ "UserSigValidity" SG_ 68 HKBD_Fr_RrDrBlwUpSw 7;
BA_REL_ "GenSigTimeoutTime" BU_SG_REL_ L_ATCU SG_ 68 HKBD_Fr_RrDrBlwUpSw 1500;
BA_ "Version" SG_ 68 HKBD_Fr_RrDrBlwUpSw "23.08.13";
BA_ "GenSigSendType" SG_ 68 HKBD_Fr_RrDrBlwSet 4;
BA_ "GenSigStartValue" SG_ 68 HKBD_Fr_RrDrBlwSet 15;
BA_ "UserSigValidity" SG_ 68 HKBD_Fr_RrDrBlwSet 7;
BA_REL_ "GenSigTimeoutTime" BU_SG_REL_ L_ATCU SG_ 68 HKBD_Fr_RrDrBlwSet 1500;
BA_ "Version" SG_ 68 HKBD_Fr_RrDrBlwSet "23.12.02";
BA_ "GenSigSendType" SG_ 68 HKBD_Fr_RrDrModDnSw 4;
BA_ "UserSigValidity" SG_ 68 HKBD_Fr_RrDrModDnSw 7;
BA_REL_ "GenSigTimeoutTime" BU_SG_REL_ L_ATCU SG_ 68 HKBD_Fr_RrDrModDnSw 1500;
BA_ "Version" SG_ 68 HKBD_Fr_RrDrModDnSw "23.08.13";
BA_ "GenSigSendType" SG_ 68 HKBD_Fr_RrDrModUpSw 4;
BA_ "UserSigValidity" SG_ 68 HKBD_Fr_RrDrModUpSw 7;
BA_REL_ "GenSigTimeoutTime" BU_SG_REL_ L_ATCU SG_ 68 HKBD_Fr_RrDrModUpSw 1500;
BA_ "Version" SG_ 68 HKBD_Fr_RrDrModUpSw "23.08.13";
BA_ "GenSigSendType" SG_ 68 HKBD_Fr_RrDrModVntSw 4;
BA_ "UserSigValidity" SG_ 68 HKBD_Fr_RrDrModVntSw 7;
BA_REL_ "GenSigTimeoutTime" BU_SG_REL_ L_ATCU SG_ 68 HKBD_Fr_RrDrModVntSw 1500;
BA_ "Version" SG_ 68 HKBD_Fr_RrDrModVntSw "23.08.13";
BA_ "GenSigSendType" SG_ 68 HKBD_Fr_PsTempUpSw 4;
BA_ "UserSigValidity" SG_ 68 HKBD_Fr_PsTempUpSw 7;
BA_REL_ "GenSigTimeoutTime" BU_SG_REL_ L_ATCU SG_ 68 HKBD_Fr_PsTempUpSw 1500;
BA_ "Version" SG_ 68 HKBD_Fr_PsTempUpSw "23.08.13";
BA_ "GenSigSendType" SG_ 68 HKBD_Fr_RrDrModFlrSw 4;
BA_ "UserSigValidity" SG_ 68 HKBD_Fr_RrDrModFlrSw 7;
BA_REL_ "GenSigTimeoutTime" BU_SG_REL_ L_ATCU SG_ 68 HKBD_Fr_RrDrModFlrSw 1500;
BA_ "Version" SG_ 68 HKBD_Fr_RrDrModFlrSw "23.08.13";
BA_ "GenSigSendType" SG_ 68 HKBD_Fr_RrDrModBiLvlSw 4;
BA_ "UserSigValidity" SG_ 68 HKBD_Fr_RrDrModBiLvlSw 7;
BA_REL_ "GenSigTimeoutTime" BU_SG_REL_ L_ATCU SG_ 68 HKBD_Fr_RrDrModBiLvlSw 1500;
BA_ "Version" SG_ 68 HKBD_Fr_RrDrModBiLvlSw "23.08.13";
BA_ "GenSigSendType" SG_ 68 HKBD_Fr_RrDrAutoSw 4;
BA_ "UserSigValidity" SG_ 68 HKBD_Fr_RrDrAutoSw 7;
BA_REL_ "GenSigTimeoutTime" BU_SG_REL_ L_ATCU SG_ 68 HKBD_Fr_RrDrAutoSw 1500;
BA_ "Version" SG_ 68 HKBD_Fr_RrDrAutoSw "23.08.13";
BA_ "GenSigSendType" SG_ 68 HKBD_Fr_RrDrMultiAutoSw 4;
BA_ "GenSigStartValue" SG_ 68 HKBD_Fr_RrDrMultiAutoSw 15;
BA_ "UserSigValidity" SG_ 68 HKBD_Fr_RrDrMultiAutoSw 7;
BA_REL_ "GenSigTimeoutTime" BU_SG_REL_ L_ATCU SG_ 68 HKBD_Fr_RrDrMultiAutoSw 1500;
BA_ "Version" SG_ 68 HKBD_Fr_RrDrMultiAutoSw "23.12.02";
BA_ "GenSigSendType" SG_ 68 HKBD_Fr_RrOffSw 4;
BA_ "UserSigValidity" SG_ 68 HKBD_Fr_RrOffSw 7;
BA_REL_ "GenSigTimeoutTime" BU_SG_REL_ L_ATCU SG_ 68 HKBD_Fr_RrOffSw 1500;
BA_ "Version" SG_ 68 HKBD_Fr_RrOffSw "23.08.13";
BA_ "GenSigSendType" SG_ 68 HKBD_Fr_RrSyncSw 4;
BA_ "UserSigValidity" SG_ 68 HKBD_Fr_RrSyncSw 7;
BA_REL_ "GenSigTimeoutTime" BU_SG_REL_ L_ATCU SG_ 68 HKBD_Fr_RrSyncSw 1500;
BA_ "Version" SG_ 68 HKBD_Fr_RrSyncSw "23.08.13";
BA_ "GenSigSendType" SG_ 68 HKBD_Fr_RLStHeatSw 4;
BA_ "UserSigValidity" SG_ 68 HKBD_Fr_RLStHeatSw 7;
BA_REL_ "GenSigTimeoutTime" BU_SG_REL_ L_ATCU SG_ 68 HKBD_Fr_RLStHeatSw 1500;
BA_ "Version" SG_ 68 HKBD_Fr_RLStHeatSw "23.08.13";
BA_ "GenSigSendType" SG_ 68 HKBD_Fr_RLStVentSw 4;
BA_ "UserSigValidity" SG_ 68 HKBD_Fr_RLStVentSw 7;
BA_REL_ "GenSigTimeoutTime" BU_SG_REL_ L_ATCU SG_ 68 HKBD_Fr_RLStVentSw 1500;
BA_ "Version" SG_ 68 HKBD_Fr_RLStVentSw "23.08.13";
BA_ "GenSigSendType" SG_ 68 HKBD_Fr_DrBlwDnSw 4;
BA_ "UserSigValidity" SG_ 68 HKBD_Fr_DrBlwDnSw 7;
BA_REL_ "GenSigTimeoutTime" BU_SG_REL_ L_ATCU SG_ 68 HKBD_Fr_DrBlwDnSw 1500;
BA_ "Version" SG_ 68 HKBD_Fr_DrBlwDnSw "23.08.13";
BA_ "GenSigSendType" SG_ 68 HKBD_Fr_RRStHeatSw 4;
BA_ "UserSigValidity" SG_ 68 HKBD_Fr_RRStHeatSw 7;
BA_REL_ "GenSigTimeoutTime" BU_SG_REL_ L_ATCU SG_ 68 HKBD_Fr_RRStHeatSw 1500;
BA_ "Version" SG_ 68 HKBD_Fr_RRStHeatSw "23.08.13";
BA_ "GenSigSendType" SG_ 68 HKBD_Fr_RRStVentSw 4;
BA_ "UserSigValidity" SG_ 68 HKBD_Fr_RRStVentSw 7;
BA_REL_ "GenSigTimeoutTime" BU_SG_REL_ L_ATCU SG_ 68 HKBD_Fr_RRStVentSw 1500;
BA_ "Version" SG_ 68 HKBD_Fr_RRStVentSw "23.08.13";
BA_ "GenSigSendType" SG_ 68 HKBD_Fr_RLStTumblrSw 4;
BA_ "UserSigValidity" SG_ 68 HKBD_Fr_RLStTumblrSw 7;
BA_REL_ "GenSigTimeoutTime" BU_SG_REL_ L_ATCU SG_ 68 HKBD_Fr_RLStTumblrSw 1500;
BA_ "Version" SG_ 68 HKBD_Fr_RLStTumblrSw "23.08.13";
BA_ "GenSigSendType" SG_ 68 HKBD_Fr_RRStTumblrSw 4;
BA_ "UserSigValidity" SG_ 68 HKBD_Fr_RRStTumblrSw 7;
BA_REL_ "GenSigTimeoutTime" BU_SG_REL_ L_ATCU SG_ 68 HKBD_Fr_RRStTumblrSw 1500;
BA_ "Version" SG_ 68 HKBD_Fr_RRStTumblrSw "23.08.13";
BA_ "GenSigSendType" SG_ 68 HKBD_Fr_RrPsModDnSw 4;
BA_ "UserSigValidity" SG_ 68 HKBD_Fr_RrPsModDnSw 7;
BA_REL_ "GenSigTimeoutTime" BU_SG_REL_ L_ATCU SG_ 68 HKBD_Fr_RrPsModDnSw 1500;
BA_ "Version" SG_ 68 HKBD_Fr_RrPsModDnSw "23.08.13";
BA_ "GenSigSendType" SG_ 68 HKBD_Fr_RrPsModUpSw 4;
BA_ "UserSigValidity" SG_ 68 HKBD_Fr_RrPsModUpSw 7;
BA_REL_ "GenSigTimeoutTime" BU_SG_REL_ L_ATCU SG_ 68 HKBD_Fr_RrPsModUpSw 1500;
BA_ "Version" SG_ 68 HKBD_Fr_RrPsModUpSw "23.08.13";
BA_ "GenSigSendType" SG_ 68 HKBD_Fr_RrPsModVntSw 4;
BA_ "UserSigValidity" SG_ 68 HKBD_Fr_RrPsModVntSw 7;
BA_REL_ "GenSigTimeoutTime" BU_SG_REL_ L_ATCU SG_ 68 HKBD_Fr_RrPsModVntSw 1500;
BA_ "Version" SG_ 68 HKBD_Fr_RrPsModVntSw "23.08.13";
BA_ "GenSigSendType" SG_ 68 HKBD_Fr_RrPsModFlrSw 4;
BA_ "UserSigValidity" SG_ 68 HKBD_Fr_RrPsModFlrSw 7;
BA_REL_ "GenSigTimeoutTime" BU_SG_REL_ L_ATCU SG_ 68 HKBD_Fr_RrPsModFlrSw 1500;
BA_ "Version" SG_ 68 HKBD_Fr_RrPsModFlrSw "23.08.13";
BA_ "GenSigSendType" SG_ 68 HKBD_Fr_DrBlwDnOffSw 4;
BA_ "UserSigValidity" SG_ 68 HKBD_Fr_DrBlwDnOffSw 7;
BA_REL_ "GenSigTimeoutTime" BU_SG_REL_ L_ATCU SG_ 68 HKBD_Fr_DrBlwDnOffSw 1500;
BA_ "Version" SG_ 68 HKBD_Fr_DrBlwDnOffSw "23.08.13";
BA_ "GenSigSendType" SG_ 68 HKBD_Fr_RrLockSw 4;
BA_ "UserSigValidity" SG_ 68 HKBD_Fr_RrLockSw 7;
BA_REL_ "GenSigTimeoutTime" BU_SG_REL_ L_ATCU SG_ 68 HKBD_Fr_RrLockSw 1500;
BA_ "Version" SG_ 68 HKBD_Fr_RrLockSw "23.08.13";
BA_ "GenSigSendType" SG_ 68 HKBD_Fr_RrPsModBiLvlSw 4;
BA_ "UserSigValidity" SG_ 68 HKBD_Fr_RrPsModBiLvlSw 7;
BA_REL_ "GenSigTimeoutTime" BU_SG_REL_ L_ATCU SG_ 68 HKBD_Fr_RrPsModBiLvlSw 1500;
BA_ "Version" SG_ 68 HKBD_Fr_RrPsModBiLvlSw "23.08.13";
BA_ "GenSigSendType" SG_ 68 HKBD_Fr_RrDrModSw 4;
BA_ "UserSigValidity" SG_ 68 HKBD_Fr_RrDrModSw 7;
BA_REL_ "GenSigTimeoutTime" BU_SG_REL_ L_ATCU SG_ 68 HKBD_Fr_RrDrModSw 1500;
BA_ "Version" SG_ 68 HKBD_Fr_RrDrModSw "23.08.13";
BA_ "GenSigSendType" SG_ 68 HKBD_Fr_RrPsModSw 4;
BA_ "UserSigValidity" SG_ 68 HKBD_Fr_RrPsModSw 7;
BA_REL_ "GenSigTimeoutTime" BU_SG_REL_ L_ATCU SG_ 68 HKBD_Fr_RrPsModSw 1500;
BA_ "Version" SG_ 68 HKBD_Fr_RrPsModSw "23.08.13";
BA_ "GenSigSendType" SG_ 68 HKBD_Fr_RrPsBlwSet 4;
BA_ "GenSigStartValue" SG_ 68 HKBD_Fr_RrPsBlwSet 15;
BA_ "UserSigValidity" SG_ 68 HKBD_Fr_RrPsBlwSet 7;
BA_REL_ "GenSigTimeoutTime" BU_SG_REL_ L_ATCU SG_ 68 HKBD_Fr_RrPsBlwSet 1500;
BA_ "Version" SG_ 68 HKBD_Fr_RrPsBlwSet "23.12.02";
BA_ "GenSigSendType" SG_ 68 HKBD_Fr_RrPsBlwUpSw 4;
BA_ "UserSigValidity" SG_ 68 HKBD_Fr_RrPsBlwUpSw 7;
BA_REL_ "GenSigTimeoutTime" BU_SG_REL_ L_ATCU SG_ 68 HKBD_Fr_RrPsBlwUpSw 1500;
BA_ "Version" SG_ 68 HKBD_Fr_RrPsBlwUpSw "23.08.13";
BA_ "GenSigSendType" SG_ 68 HKBD_Fr_RrPsBlwDnSw 4;
BA_ "UserSigValidity" SG_ 68 HKBD_Fr_RrPsBlwDnSw 7;
BA_REL_ "GenSigTimeoutTime" BU_SG_REL_ L_ATCU SG_ 68 HKBD_Fr_RrPsBlwDnSw 1500;
BA_ "Version" SG_ 68 HKBD_Fr_RrPsBlwDnSw "23.08.13";
BA_ "GenSigSendType" SG_ 68 HKBD_Fr_DrBlwUpSw 4;
BA_ "UserSigValidity" SG_ 68 HKBD_Fr_DrBlwUpSw 7;
BA_REL_ "GenSigTimeoutTime" BU_SG_REL_ L_ATCU SG_ 68 HKBD_Fr_DrBlwUpSw 1500;
BA_ "Version" SG_ 68 HKBD_Fr_DrBlwUpSw "23.08.13";
BA_ "GenSigSendType" SG_ 68 HKBD_Fr_RrPsBlwDnOffSw 4;
BA_ "UserSigValidity" SG_ 68 HKBD_Fr_RrPsBlwDnOffSw 7;
BA_REL_ "GenSigTimeoutTime" BU_SG_REL_ L_ATCU SG_ 68 HKBD_Fr_RrPsBlwDnOffSw 1500;
BA_ "Version" SG_ 68 HKBD_Fr_RrPsBlwDnOffSw "23.08.13";
BA_ "GenSigSendType" SG_ 68 HKBD_Fr_RrPsTempDnSw 4;
BA_ "UserSigValidity" SG_ 68 HKBD_Fr_RrPsTempDnSw 7;
BA_REL_ "GenSigTimeoutTime" BU_SG_REL_ L_ATCU SG_ 68 HKBD_Fr_RrPsTempDnSw 1500;
BA_ "Version" SG_ 68 HKBD_Fr_RrPsTempDnSw "23.08.13";
BA_ "GenSigSendType" SG_ 68 HKBD_Fr_RrPsTempUpSw 4;
BA_ "UserSigValidity" SG_ 68 HKBD_Fr_RrPsTempUpSw 7;
BA_REL_ "GenSigTimeoutTime" BU_SG_REL_ L_ATCU SG_ 68 HKBD_Fr_RrPsTempUpSw 1500;
BA_ "Version" SG_ 68 HKBD_Fr_RrPsTempUpSw "23.08.13";
BA_ "GenSigSendType" SG_ 68 HKBD_Fr_DrBlwSet 4;
BA_ "GenSigStartValue" SG_ 68 HKBD_Fr_DrBlwSet 15;
BA_ "UserSigValidity" SG_ 68 HKBD_Fr_DrBlwSet 7;
BA_REL_ "GenSigTimeoutTime" BU_SG_REL_ L_ATCU SG_ 68 HKBD_Fr_DrBlwSet 1500;
BA_ "Version" SG_ 68 HKBD_Fr_DrBlwSet "23.12.02";
BA_ "GenMsgSendType" BO_ 69 0;
BA_ "GenSigSendType" SG_ 69 HKBD_Fr_3rdRrTempDnSw 4;
BA_ "UserSigValidity" SG_ 69 HKBD_Fr_3rdRrTempDnSw 7;
BA_REL_ "GenSigTimeoutTime" BU_SG_REL_ L_ATCU SG_ 69 HKBD_Fr_3rdRrTempDnSw 1500;
BA_ "Version" SG_ 69 HKBD_Fr_3rdRrTempDnSw "23.08.13";
BA_ "GenSigSendType" SG_ 69 HKBD_Fr_3rdRrTempUpSw 4;
BA_ "UserSigValidity" SG_ 69 HKBD_Fr_3rdRrTempUpSw 7;
BA_REL_ "GenSigTimeoutTime" BU_SG_REL_ L_ATCU SG_ 69 HKBD_Fr_3rdRrTempUpSw 1500;
BA_ "Version" SG_ 69 HKBD_Fr_3rdRrTempUpSw "23.08.13";
BA_ "GenSigSendType" SG_ 69 HKBD_Fr_3rdRrModUpSw 4;
BA_ "UserSigValidity" SG_ 69 HKBD_Fr_3rdRrModUpSw 7;
BA_REL_ "GenSigTimeoutTime" BU_SG_REL_ L_ATCU SG_ 69 HKBD_Fr_3rdRrModUpSw 1500;
BA_ "Version" SG_ 69 HKBD_Fr_3rdRrModUpSw "23.08.13";
BA_ "GenSigSendType" SG_ 69 HKBD_Fr_3rdRrModVntSw 4;
BA_ "UserSigValidity" SG_ 69 HKBD_Fr_3rdRrModVntSw 7;
BA_REL_ "GenSigTimeoutTime" BU_SG_REL_ L_ATCU SG_ 69 HKBD_Fr_3rdRrModVntSw 1500;
BA_ "Version" SG_ 69 HKBD_Fr_3rdRrModVntSw "23.08.13";
BA_ "GenSigSendType" SG_ 69 HKBD_Fr_3rdRrModFlrSw 4;
BA_ "UserSigValidity" SG_ 69 HKBD_Fr_3rdRrModFlrSw 7;
BA_REL_ "GenSigTimeoutTime" BU_SG_REL_ L_ATCU SG_ 69 HKBD_Fr_3rdRrModFlrSw 1500;
BA_ "Version" SG_ 69 HKBD_Fr_3rdRrModFlrSw "23.08.13";
BA_ "GenSigSendType" SG_ 69 HKBD_Fr_3rdRrAutoSw 4;
BA_ "UserSigValidity" SG_ 69 HKBD_Fr_3rdRrAutoSw 7;
BA_REL_ "GenSigTimeoutTime" BU_SG_REL_ L_ATCU SG_ 69 HKBD_Fr_3rdRrAutoSw 1500;
BA_ "Version" SG_ 69 HKBD_Fr_3rdRrAutoSw "23.08.13";
BA_ "GenSigSendType" SG_ 69 HKBD_Fr_3rdRrMultiAutoSw 4;
BA_ "GenSigStartValue" SG_ 69 HKBD_Fr_3rdRrMultiAutoSw 7;
BA_ "UserSigValidity" SG_ 69 HKBD_Fr_3rdRrMultiAutoSw 7;
BA_REL_ "GenSigTimeoutTime" BU_SG_REL_ L_ATCU SG_ 69 HKBD_Fr_3rdRrMultiAutoSw 1500;
BA_ "Version" SG_ 69 HKBD_Fr_3rdRrMultiAutoSw "23.12.02";
BA_ "GenSigSendType" SG_ 69 HKBD_Fr_3rdRrOffSw 4;
BA_ "UserSigValidity" SG_ 69 HKBD_Fr_3rdRrOffSw 7;
BA_REL_ "GenSigTimeoutTime" BU_SG_REL_ L_ATCU SG_ 69 HKBD_Fr_3rdRrOffSw 1500;
BA_ "Version" SG_ 69 HKBD_Fr_3rdRrOffSw "23.08.13";
BA_ "GenSigSendType" SG_ 69 HKBD_Fr_3rdRrSyncSw 4;
BA_ "UserSigValidity" SG_ 69 HKBD_Fr_3rdRrSyncSw 7;
BA_REL_ "GenSigTimeoutTime" BU_SG_REL_ L_ATCU SG_ 69 HKBD_Fr_3rdRrSyncSw 1500;
BA_ "Version" SG_ 69 HKBD_Fr_3rdRrSyncSw "23.08.13";
BA_ "GenSigSendType" SG_ 69 HKBD_Fr_3rdRrLockSw 4;
BA_ "UserSigValidity" SG_ 69 HKBD_Fr_3rdRrLockSw 7;
BA_REL_ "GenSigTimeoutTime" BU_SG_REL_ L_ATCU SG_ 69 HKBD_Fr_3rdRrLockSw 1500;
BA_ "Version" SG_ 69 HKBD_Fr_3rdRrLockSw "23.08.13";
BA_ "GenSigSendType" SG_ 69 HKBD_Fr_3rdRrBlwDnSw 4;
BA_ "UserSigValidity" SG_ 69 HKBD_Fr_3rdRrBlwDnSw 7;
BA_REL_ "GenSigTimeoutTime" BU_SG_REL_ L_ATCU SG_ 69 HKBD_Fr_3rdRrBlwDnSw 1500;
BA_ "Version" SG_ 69 HKBD_Fr_3rdRrBlwDnSw "23.08.13";
BA_ "GenSigSendType" SG_ 69 HKBD_Fr_3rdRrModBiLvlSw 4;
BA_ "UserSigValidity" SG_ 69 HKBD_Fr_3rdRrModBiLvlSw 7;
BA_REL_ "GenSigTimeoutTime" BU_SG_REL_ L_ATCU SG_ 69 HKBD_Fr_3rdRrModBiLvlSw 1500;
BA_ "Version" SG_ 69 HKBD_Fr_3rdRrModBiLvlSw "23.08.13";
BA_ "GenSigSendType" SG_ 69 HKBD_FrRrTglSet 4;
BA_ "UserSigValidity" SG_ 69 HKBD_FrRrTglSet 7;
BA_REL_ "GenSigTimeoutTime" BU_SG_REL_ L_ATCU SG_ 69 HKBD_FrRrTglSet 1500;
BA_ "Version" SG_ 69 HKBD_FrRrTglSet "23.11.06";
BA_ "GenSigSendType" SG_ 69 HKBD_Fr_RrScrnSet 4;
BA_ "UserSigValidity" SG_ 69 HKBD_Fr_RrScrnSet 7;
BA_REL_ "GenSigTimeoutTime" BU_SG_REL_ L_ATCU SG_ 69 HKBD_Fr_RrScrnSet 1500;
BA_ "Version" SG_ 69 HKBD_Fr_RrScrnSet "23.12.02";
BA_ "GenSigSendType" SG_ 69 HKBD_Fr_OnOffSet 4;
BA_ "UserSigValidity" SG_ 69 HKBD_Fr_OnOffSet 7;
BA_REL_ "GenSigTimeoutTime" BU_SG_REL_ L_ATCU SG_ 69 HKBD_Fr_OnOffSet 1500;
BA_ "Version" SG_ 69 HKBD_Fr_OnOffSet "23.08.13";
BA_ "GenSigSendType" SG_ 69 HKBD_Fr_RrOnOffSet 4;
BA_ "UserSigValidity" SG_ 69 HKBD_Fr_RrOnOffSet 7;
BA_REL_ "GenSigTimeoutTime" BU_SG_REL_ L_ATCU SG_ 69 HKBD_Fr_RrOnOffSet 1500;
BA_ "Version" SG_ 69 HKBD_Fr_RrOnOffSet "23.08.13";
BA_ "GenSigSendType" SG_ 69 HKBD_Fr_3rdRrOnOffSet 4;
BA_ "UserSigValidity" SG_ 69 HKBD_Fr_3rdRrOnOffSet 7;
BA_REL_ "GenSigTimeoutTime" BU_SG_REL_ L_ATCU SG_ 69 HKBD_Fr_3rdRrOnOffSet 1500;
BA_ "Version" SG_ 69 HKBD_Fr_3rdRrOnOffSet "23.12.02";
BA_ "GenSigSendType" SG_ 69 HKBD_Fr_3rdRrBlwDnOffSw 4;
BA_ "UserSigValidity" SG_ 69 HKBD_Fr_3rdRrBlwDnOffSw 7;
BA_REL_ "GenSigTimeoutTime" BU_SG_REL_ L_ATCU SG_ 69 HKBD_Fr_3rdRrBlwDnOffSw 1500;
BA_ "Version" SG_ 69 HKBD_Fr_3rdRrBlwDnOffSw "23.08.13";
BA_ "GenSigSendType" SG_ 69 HKBD_Fr_RrPsAutoSw 4;
BA_ "UserSigValidity" SG_ 69 HKBD_Fr_RrPsAutoSw 7;
BA_REL_ "GenSigTimeoutTime" BU_SG_REL_ L_ATCU SG_ 69 HKBD_Fr_RrPsAutoSw 1500;
BA_ "Version" SG_ 69 HKBD_Fr_RrPsAutoSw "23.08.13";
BA_ "GenSigSendType" SG_ 69 HKBD_Fr_RrPsMultiAutoSw 4;
BA_ "GenSigStartValue" SG_ 69 HKBD_Fr_RrPsMultiAutoSw 7;
BA_ "UserSigValidity" SG_ 69 HKBD_Fr_RrPsMultiAutoSw 7;
BA_REL_ "GenSigTimeoutTime" BU_SG_REL_ L_ATCU SG_ 69 HKBD_Fr_RrPsMultiAutoSw 1500;
BA_ "Version" SG_ 69 HKBD_Fr_RrPsMultiAutoSw "23.12.02";
BA_ "GenSigSendType" SG_ 69 HKBD_Fr_3rdRrModSw 4;
BA_ "UserSigValidity" SG_ 69 HKBD_Fr_3rdRrModSw 7;
BA_REL_ "GenSigTimeoutTime" BU_SG_REL_ L_ATCU SG_ 69 HKBD_Fr_3rdRrModSw 1500;
BA_ "Version" SG_ 69 HKBD_Fr_3rdRrModSw "23.08.13";
BA_ "GenSigSendType" SG_ 69 HKBD_Fr_RrModSet 4;
BA_ "UserSigValidity" SG_ 69 HKBD_Fr_RrModSet 7;
BA_REL_ "GenSigTimeoutTime" BU_SG_REL_ L_ATCU SG_ 69 HKBD_Fr_RrModSet 1500;
BA_ "Version" SG_ 69 HKBD_Fr_RrModSet "25.05.04";
BA_ "GenSigSendType" SG_ 69 HKBD_Fr_3rdRrBlwUpSw 4;
BA_ "UserSigValidity" SG_ 69 HKBD_Fr_3rdRrBlwUpSw 7;
BA_REL_ "GenSigTimeoutTime" BU_SG_REL_ L_ATCU SG_ 69 HKBD_Fr_3rdRrBlwUpSw 1500;
BA_ "Version" SG_ 69 HKBD_Fr_3rdRrBlwUpSw "23.08.13";
BA_ "GenSigSendType" SG_ 69 HKBD_Fr_3rdModSet 4;
BA_ "UserSigValidity" SG_ 69 HKBD_Fr_3rdModSet 7;
BA_REL_ "GenSigTimeoutTime" BU_SG_REL_ L_ATCU SG_ 69 HKBD_Fr_3rdModSet 1500;
BA_ "Version" SG_ 69 HKBD_Fr_3rdModSet "25.05.04";
BA_ "GenSigSendType" SG_ 69 HKBD_Fr_DrblwUpMaxSw 4;
BA_ "UserSigValidity" SG_ 69 HKBD_Fr_DrblwUpMaxSw 7;
BA_REL_ "GenSigTimeoutTime" BU_SG_REL_ L_ATCU SG_ 69 HKBD_Fr_DrblwUpMaxSw 1500;
BA_ "Version" SG_ 69 HKBD_Fr_DrblwUpMaxSw "25.05.04";
BA_ "GenSigSendType" SG_ 69 HKBD_Fr_PsblwUpMaxSw 4;
BA_ "UserSigValidity" SG_ 69 HKBD_Fr_PsblwUpMaxSw 7;
BA_REL_ "GenSigTimeoutTime" BU_SG_REL_ L_ATCU SG_ 69 HKBD_Fr_PsblwUpMaxSw 1500;
BA_ "Version" SG_ 69 HKBD_Fr_PsblwUpMaxSw "25.05.04";
BA_ "GenSigSendType" SG_ 69 HKBD_Fr_3rdRrBlwSet 4;
BA_ "GenSigStartValue" SG_ 69 HKBD_Fr_3rdRrBlwSet 15;
BA_ "UserSigValidity" SG_ 69 HKBD_Fr_3rdRrBlwSet 7;
BA_REL_ "GenSigTimeoutTime" BU_SG_REL_ L_ATCU SG_ 69 HKBD_Fr_3rdRrBlwSet 1500;
BA_ "Version" SG_ 69 HKBD_Fr_3rdRrBlwSet "23.12.02";
BA_ "GenSigSendType" SG_ 69 HKBD_Fr_3rdRrModDnSw 4;
BA_ "UserSigValidity" SG_ 69 HKBD_Fr_3rdRrModDnSw 7;
BA_REL_ "GenSigTimeoutTime" BU_SG_REL_ L_ATCU SG_ 69 HKBD_Fr_3rdRrModDnSw 1500;
BA_ "Version" SG_ 69 HKBD_Fr_3rdRrModDnSw "23.08.13";
BA_ "GenMsgSendType" BO_ 70 0;
BA_ "GenMsgCycleTime" BO_ 70 500;
BA_ "Description" SG_ 70 HKBD_SwBtnTyp "Each bit for button type is defined as

0-None/1-Hardkey/2-Touch(Used Beep)/3-Touch(Not Used Beep)

Bit 0~1 (Temp Button)/Bit 2~3 (Blower Button)/Bit 4~5 (Mode Button)/

Bit 6~7 (Auto Button)/Bit 8~9 (A/C Button)/Bit 10~11 (Def Button)/

Bit 12~13 (Intake Button)/Bit 14~15 (Sync Button)/Bit 16~17 (RrDef Button)/

Bit 18~19 (DrOnly Button)/Bit 20~21 (AirCln Button)/Bit 22~23 (StHeatVnt Button)/

Bit 24~25 (StrWhlHeat Button)/Bit 26~27 (FrWndShldHt Button)/

Bit 28~29 (Diffuser Button)/Bit 30~31 (OFF Button)/Bit 32~33 (Climate Button)

Bit 34~35 (FrRrTgl Button)

Bit36~37 (SmartZone Button) : 0 ? None / 1 ? HardKey / 2 ? Touch(Used Beep) / 3 ? Touch (Not Used Beep)

Bit 38~39 : Reserved";
BA_ "GenSigSendType" SG_ 70 HKBD_SwBtnTyp 4;
BA_ "UserSigValidity" SG_ 70 HKBD_SwBtnTyp 7;
BA_REL_ "GenSigTimeoutTime" BU_SG_REL_ L_ATCU SG_ 70 HKBD_SwBtnTyp 5000;
BA_ "Version" SG_ 70 HKBD_SwBtnTyp "24.11.00";
BA_ "Description" SG_ 70 L_HKBD_ResetOpSta "This signal indicates whether the reset operation has been completed or not";
BA_ "GenSigSendType" SG_ 70 L_HKBD_ResetOpSta 4;
BA_ "UserSigValidity" SG_ 70 L_HKBD_ResetOpSta 0;
BA_REL_ "GenSigTimeoutTime" BU_SG_REL_ L_ATCU SG_ 70 L_HKBD_ResetOpSta 1000;
BA_ "Version" SG_ 70 L_HKBD_ResetOpSta "24.10.05";
BA_ "GenMsgCycleTime" BO_ 71 0;
BA_ "GenSigSendType" SG_ 71 HKBD_Fr_RrDrTempClickCnt 4;
BA_ "GenSigStartValue" SG_ 71 HKBD_Fr_RrDrTempClickCnt 255;
BA_ "UserSigValidity" SG_ 71 HKBD_Fr_RrDrTempClickCnt 7;
BA_REL_ "GenSigTimeoutTime" BU_SG_REL_ L_ATCU SG_ 71 HKBD_Fr_RrDrTempClickCnt 0;
BA_ "Version" SG_ 71 HKBD_Fr_RrDrTempClickCnt "23.12.02";
BA_ "GenSigSendType" SG_ 71 HKBD_Fr_RrPsTempClickCnt 4;
BA_ "GenSigStartValue" SG_ 71 HKBD_Fr_RrPsTempClickCnt 255;
BA_ "UserSigValidity" SG_ 71 HKBD_Fr_RrPsTempClickCnt 7;
BA_REL_ "GenSigTimeoutTime" BU_SG_REL_ L_ATCU SG_ 71 HKBD_Fr_RrPsTempClickCnt 0;
BA_ "Version" SG_ 71 HKBD_Fr_RrPsTempClickCnt "23.12.02";
BA_ "GenSigSendType" SG_ 71 HKBD_Fr_RrPsBlwClickCnt 4;
BA_ "GenSigStartValue" SG_ 71 HKBD_Fr_RrPsBlwClickCnt 255;
BA_ "UserSigValidity" SG_ 71 HKBD_Fr_RrPsBlwClickCnt 7;
BA_REL_ "GenSigTimeoutTime" BU_SG_REL_ L_ATCU SG_ 71 HKBD_Fr_RrPsBlwClickCnt 0;
BA_ "Version" SG_ 71 HKBD_Fr_RrPsBlwClickCnt "23.12.02";
BA_ "GenSigSendType" SG_ 71 HKBD_Fr_3rdRrTempClickCnt 4;
BA_ "GenSigStartValue" SG_ 71 HKBD_Fr_3rdRrTempClickCnt 255;
BA_ "UserSigValidity" SG_ 71 HKBD_Fr_3rdRrTempClickCnt 7;
BA_REL_ "GenSigTimeoutTime" BU_SG_REL_ L_ATCU SG_ 71 HKBD_Fr_3rdRrTempClickCnt 0;
BA_ "Version" SG_ 71 HKBD_Fr_3rdRrTempClickCnt "23.12.02";
BA_ "GenSigSendType" SG_ 71 HKBD_Fr_3rdRrBlwClickCnt 4;
BA_ "GenSigStartValue" SG_ 71 HKBD_Fr_3rdRrBlwClickCnt 255;
BA_ "UserSigValidity" SG_ 71 HKBD_Fr_3rdRrBlwClickCnt 7;
BA_REL_ "GenSigTimeoutTime" BU_SG_REL_ L_ATCU SG_ 71 HKBD_Fr_3rdRrBlwClickCnt 0;
BA_ "Version" SG_ 71 HKBD_Fr_3rdRrBlwClickCnt "23.12.02";
BA_ "GenSigSendType" SG_ 71 HKBD_Fr_RrTempKnobCnt 4;
BA_ "GenSigStartValue" SG_ 71 HKBD_Fr_RrTempKnobCnt 3;
BA_ "UserSigValidity" SG_ 71 HKBD_Fr_RrTempKnobCnt 7;
BA_REL_ "GenSigTimeoutTime" BU_SG_REL_ L_ATCU SG_ 71 HKBD_Fr_RrTempKnobCnt 0;
BA_ "Version" SG_ 71 HKBD_Fr_RrTempKnobCnt "23.12.02";
BA_ "GenSigSendType" SG_ 71 HKBD_Fr_RrBlwKnobCnt 4;
BA_ "GenSigStartValue" SG_ 71 HKBD_Fr_RrBlwKnobCnt 3;
BA_ "UserSigValidity" SG_ 71 HKBD_Fr_RrBlwKnobCnt 7;
BA_REL_ "GenSigTimeoutTime" BU_SG_REL_ L_ATCU SG_ 71 HKBD_Fr_RrBlwKnobCnt 0;
BA_ "Version" SG_ 71 HKBD_Fr_RrBlwKnobCnt "23.12.02";
BA_ "GenSigSendType" SG_ 71 HKBD_Fr_3rdTempKnobCnt 4;
BA_ "GenSigStartValue" SG_ 71 HKBD_Fr_3rdTempKnobCnt 3;
BA_ "UserSigValidity" SG_ 71 HKBD_Fr_3rdTempKnobCnt 7;
BA_REL_ "GenSigTimeoutTime" BU_SG_REL_ L_ATCU SG_ 71 HKBD_Fr_3rdTempKnobCnt 0;
BA_ "Version" SG_ 71 HKBD_Fr_3rdTempKnobCnt "23.12.02";
BA_ "GenSigSendType" SG_ 71 HKBD_Fr_3rdBlwKnobCnt 4;
BA_ "GenSigStartValue" SG_ 71 HKBD_Fr_3rdBlwKnobCnt 3;
BA_ "UserSigValidity" SG_ 71 HKBD_Fr_3rdBlwKnobCnt 7;
BA_REL_ "GenSigTimeoutTime" BU_SG_REL_ L_ATCU SG_ 71 HKBD_Fr_3rdBlwKnobCnt 0;
BA_ "Version" SG_ 71 HKBD_Fr_3rdBlwKnobCnt "23.12.02";
BA_ "Description" SG_ 71 L_HKBD_HVACPnlBckLight_Res "Vehicle API HVAC Control Panel BackLight Response";
BA_ "GenSigSendType" SG_ 71 L_HKBD_HVACPnlBckLight_Res 4;
BA_ "UserSigValidity" SG_ 71 L_HKBD_HVACPnlBckLight_Res 7;
BA_REL_ "GenSigTimeoutTime" BU_SG_REL_ L_ATCU SG_ 71 L_HKBD_HVACPnlBckLight_Res 0;
BA_ "Version" SG_ 71 L_HKBD_HVACPnlBckLight_Res "25.08.06";
BA_ "GenSigSendType" SG_ 71 HKBD_Fr_RrDrBlwClickCnt 4;
BA_ "GenSigStartValue" SG_ 71 HKBD_Fr_RrDrBlwClickCnt 255;
BA_ "UserSigValidity" SG_ 71 HKBD_Fr_RrDrBlwClickCnt 7;
BA_REL_ "GenSigTimeoutTime" BU_SG_REL_ L_ATCU SG_ 71 HKBD_Fr_RrDrBlwClickCnt 0;
BA_ "Version" SG_ 71 HKBD_Fr_RrDrBlwClickCnt "23.12.02";
BA_ "GenMsgSendType" BO_ 72 0;
BA_ "GenMsgCycleTime" BO_ 72 20;
BA_ "GenMsgCycleTimeFast" BO_ 72 0;
BA_ "GenMsgNrOfRepetition" BO_ 72 0;
BA_ "GenMsgDelayTime" BO_ 72 0;
BA_ "UserSigValidity" SG_ 72 HKBD_Fr_IncarRaw 7;
BA_ "Version" SG_ 72 HKBD_Fr_IncarRaw "23.08.13";
BA_ "GenMsgSendType" BO_ 336 0;
BA_ "GenMsgCycleTime" BO_ 336 20;
BA_ "GenMsgCycleTimeFast" BO_ 336 0;
BA_ "GenMsgNrOfRepetition" BO_ 336 0;
BA_ "GenMsgDelayTime" BO_ 336 0;
BA_ "UserSigValidity" SG_ 336 RHPTC_Zone1RdySta 7;
BA_ "Version" SG_ 336 RHPTC_Zone1RdySta "24.02.06";
BA_ "UserSigValidity" SG_ 336 RHPTC_Zone1OpSta 7;
BA_ "Version" SG_ 336 RHPTC_Zone1OpSta "24.02.06";
BA_ "UserSigValidity" SG_ 336 RHPTC_Zone1CnsmptPwr_W 7;
BA_ "Version" SG_ 336 RHPTC_Zone1CnsmptPwr_W "24.02.06";
BA_ "UserSigValidity" SG_ 336 RHPTC_Zone1Voltage_V 7;
BA_ "Version" SG_ 336 RHPTC_Zone1Voltage_V "24.02.06";
BA_ "UserSigValidity" SG_ 336 RHPTC_Zone1CtrlTyp 7;
BA_ "Version" SG_ 336 RHPTC_Zone1CtrlTyp "24.02.06";
BA_ "UserSigValidity" SG_ 336 RHPTC_Zone1Current_A 7;
BA_ "Version" SG_ 336 RHPTC_Zone1Current_A "24.02.06";
BA_ "Description" SG_ 336 RHPTC_Zone1DutyFB_Pec "Duty Conversion to PTC Consumption power value, 40w~6kw -> 10%~95%";
BA_ "UserSigValidity" SG_ 336 RHPTC_Zone1DutyFB_Pec 7;
BA_ "Version" SG_ 336 RHPTC_Zone1DutyFB_Pec "24.02.06";
BA_ "Description" SG_ 336 RHPTC_Zone1DutyFB_IGBT "PWM DUTY of PTC IGBT (0~100%)";
BA_ "UserSigValidity" SG_ 336 RHPTC_Zone1DutyFB_IGBT 7;
BA_ "Version" SG_ 336 RHPTC_Zone1DutyFB_IGBT "24.02.06";
BA_ "UserSigValidity" SG_ 336 RHPTC_Zone1CoreTemp_C 7;
BA_ "Version" SG_ 336 RHPTC_Zone1CoreTemp_C "24.02.06";
BA_ "GenMsgSendType" BO_ 337 0;
BA_ "GenMsgCycleTime" BO_ 337 20;
BA_ "GenMsgCycleTimeFast" BO_ 337 0;
BA_ "GenMsgNrOfRepetition" BO_ 337 0;
BA_ "GenMsgDelayTime" BO_ 337 0;
BA_ "UserSigValidity" SG_ 337 RHPTC_Zone1Flt 7;
BA_ "Version" SG_ 337 RHPTC_Zone1Flt "24.02.06";
BA_ "UserSigValidity" SG_ 337 RHPTC_Zone1FltLVLow 7;
BA_ "Version" SG_ 337 RHPTC_Zone1FltLVLow "24.02.06";
BA_ "UserSigValidity" SG_ 337 RHPTC_Zone1FailLVSnr 7;
BA_ "Version" SG_ 337 RHPTC_Zone1FailLVSnr "24.02.06";
BA_ "UserSigValidity" SG_ 337 RHPTC_Zone1FailCurrentSnr 7;
BA_ "Version" SG_ 337 RHPTC_Zone1FailCurrentSnr "24.02.06";
BA_ "UserSigValidity" SG_ 337 RHPTC_Zone1FailCoreTempSnr 7;
BA_ "Version" SG_ 337 RHPTC_Zone1FailCoreTempSnr "24.02.06";
BA_ "UserSigValidity" SG_ 337 RHPTC_Zone1FailPcbTempSnr 7;
BA_ "Version" SG_ 337 RHPTC_Zone1FailPcbTempSnr "24.02.06";
BA_ "UserSigValidity" SG_ 337 RHPTC_Zone1FailIGBT 7;
BA_ "Version" SG_ 337 RHPTC_Zone1FailIGBT "24.02.06";
BA_ "UserSigValidity" SG_ 337 RHPTC_Zone1FailOpenLoad 7;
BA_ "Version" SG_ 337 RHPTC_Zone1FailOpenLoad "24.02.06";
BA_ "UserSigValidity" SG_ 337 RHPTC_Zone1LtdOpCause 7;
BA_ "Version" SG_ 337 RHPTC_Zone1LtdOpCause "24.02.06";
BA_ "UserSigValidity" SG_ 337 RHPTC_Zone1FltLVHigh 7;
BA_ "Version" SG_ 337 RHPTC_Zone1FltLVHigh "24.02.06";
BA_ "UserSigValidity" SG_ 337 RHPTC_Zone1SwVer 7;
BA_ "Version" SG_ 337 RHPTC_Zone1SwVer "24.02.06";
BA_ "UserSigValidity" SG_ 337 RHPTC_Zone1FltHVLow 7;
BA_ "Version" SG_ 337 RHPTC_Zone1FltHVLow "24.02.06";
BA_ "Description" SG_ 337 RHPTC_CnsmptPwrTtl_W "Total Power Consumption Value = RHPTC_RoofConsumptionPower_W + RHPTC_flrConsumptionPower_W";
BA_ "UserSigValidity" SG_ 337 RHPTC_CnsmptPwrTtl_W 7;
BA_ "Version" SG_ 337 RHPTC_CnsmptPwrTtl_W "24.02.06";
BA_ "UserSigValidity" SG_ 337 RHPTC_Zone1FltHVHigh 7;
BA_ "Version" SG_ 337 RHPTC_Zone1FltHVHigh "24.02.06";
BA_ "UserSigValidity" SG_ 337 RHPTC_IntlkSta 7;
BA_ "Version" SG_ 337 RHPTC_IntlkSta "25.04.02";
BA_ "UserSigValidity" SG_ 337 RHPTC_Zone1FltOverCurrent 7;
BA_ "Version" SG_ 337 RHPTC_Zone1FltOverCurrent "24.02.06";
BA_ "UserSigValidity" SG_ 337 RHPTC_Zone1FltThermalShutDn 7;
BA_ "Version" SG_ 337 RHPTC_Zone1FltThermalShutDn "24.02.06";
BA_ "UserSigValidity" SG_ 337 RHPTC_Zone1FltPcbThermalShutDn 7;
BA_ "Version" SG_ 337 RHPTC_Zone1FltPcbThermalShutDn "24.02.06";
BA_ "UserSigValidity" SG_ 337 RHPTC_Zone1FltMsgTmOutATCU 7;
BA_ "Version" SG_ 337 RHPTC_Zone1FltMsgTmOutATCU "24.02.06";
BA_ "UserSigValidity" SG_ 337 RHPTC_Zone1FailHVSnr 7;
BA_ "Version" SG_ 337 RHPTC_Zone1FailHVSnr "24.02.06";
BA_ "GenMsgSendType" BO_ 338 0;
BA_ "GenMsgCycleTime" BO_ 338 20;
BA_ "GenMsgCycleTimeFast" BO_ 338 0;
BA_ "GenMsgNrOfRepetition" BO_ 338 0;
BA_ "GenMsgDelayTime" BO_ 338 0;
BA_ "UserSigValidity" SG_ 338 RHPTC_Zone2RdySta 7;
BA_ "Version" SG_ 338 RHPTC_Zone2RdySta "24.02.06";
BA_ "UserSigValidity" SG_ 338 RHPTC_Zone2OpSta 7;
BA_ "Version" SG_ 338 RHPTC_Zone2OpSta "24.02.06";
BA_ "UserSigValidity" SG_ 338 RHPTC_Zone2CnsmptPwr_W 7;
BA_ "Version" SG_ 338 RHPTC_Zone2CnsmptPwr_W "24.02.06";
BA_ "UserSigValidity" SG_ 338 RHPTC_Zone2CtrlTyp 7;
BA_ "Version" SG_ 338 RHPTC_Zone2CtrlTyp "24.02.06";
BA_ "UserSigValidity" SG_ 338 RHPTC_Zone2Voltage_V 7;
BA_ "Version" SG_ 338 RHPTC_Zone2Voltage_V "24.02.06";
BA_ "UserSigValidity" SG_ 338 RHPTC_Zone2Current_A 7;
BA_ "Version" SG_ 338 RHPTC_Zone2Current_A "24.02.06";
BA_ "Description" SG_ 338 RHPTC_Zone2DutyFB_Pec "Duty Conversion to PTC Consumption power value, 40w~6kw -> 10%~95%";
BA_ "UserSigValidity" SG_ 338 RHPTC_Zone2DutyFB_Pec 7;
BA_ "Version" SG_ 338 RHPTC_Zone2DutyFB_Pec "24.02.06";
BA_ "Description" SG_ 338 RHPTC_Zone2DutyFB_IGBT "PWM DUTY of PTC IGBT (0~100%)";
BA_ "UserSigValidity" SG_ 338 RHPTC_Zone2DutyFB_IGBT 7;
BA_ "Version" SG_ 338 RHPTC_Zone2DutyFB_IGBT "24.02.06";
BA_ "UserSigValidity" SG_ 338 RHPTC_Zone2CoreTemp_C 7;
BA_ "Version" SG_ 338 RHPTC_Zone2CoreTemp_C "24.02.06";
BA_ "GenMsgSendType" BO_ 339 0;
BA_ "GenMsgCycleTime" BO_ 339 20;
BA_ "GenMsgCycleTimeFast" BO_ 339 0;
BA_ "GenMsgNrOfRepetition" BO_ 339 0;
BA_ "GenMsgDelayTime" BO_ 339 0;
BA_ "UserSigValidity" SG_ 339 RHPTC_Zone2Flt 7;
BA_ "Version" SG_ 339 RHPTC_Zone2Flt "24.02.06";
BA_ "UserSigValidity" SG_ 339 RHPTC_Zone2FltLVLow 7;
BA_ "Version" SG_ 339 RHPTC_Zone2FltLVLow "24.02.06";
BA_ "UserSigValidity" SG_ 339 RHPTC_Zone2FailLVSnr 7;
BA_ "Version" SG_ 339 RHPTC_Zone2FailLVSnr "24.02.06";
BA_ "UserSigValidity" SG_ 339 RHPTC_Zone2FailCurrentSnr 7;
BA_ "Version" SG_ 339 RHPTC_Zone2FailCurrentSnr "24.02.06";
BA_ "UserSigValidity" SG_ 339 RHPTC_Zone2FailCoreTempSnr 7;
BA_ "Version" SG_ 339 RHPTC_Zone2FailCoreTempSnr "24.02.06";
BA_ "UserSigValidity" SG_ 339 RHPTC_Zone2FailPcbTempSnr 7;
BA_ "Version" SG_ 339 RHPTC_Zone2FailPcbTempSnr "24.02.06";
BA_ "UserSigValidity" SG_ 339 RHPTC_Zone2FailIGBT 7;
BA_ "Version" SG_ 339 RHPTC_Zone2FailIGBT "24.02.06";
BA_ "UserSigValidity" SG_ 339 RHPTC_Zone2FailOpenLoad 7;
BA_ "Version" SG_ 339 RHPTC_Zone2FailOpenLoad "24.02.06";
BA_ "UserSigValidity" SG_ 339 RHPTC_Zone2LtdOpCause 7;
BA_ "Version" SG_ 339 RHPTC_Zone2LtdOpCause "24.02.06";
BA_ "UserSigValidity" SG_ 339 RHPTC_Zone2FltLVHigh 7;
BA_ "Version" SG_ 339 RHPTC_Zone2FltLVHigh "24.02.06";
BA_ "UserSigValidity" SG_ 339 RHPTC_Zone2SwrVer 7;
BA_ "Version" SG_ 339 RHPTC_Zone2SwrVer "24.02.06";
BA_ "UserSigValidity" SG_ 339 RHPTC_Zone2FltHVLow 7;
BA_ "Version" SG_ 339 RHPTC_Zone2FltHVLow "24.02.06";
BA_ "UserSigValidity" SG_ 339 RHPTC_Zone2FltHVHigh 7;
BA_ "Version" SG_ 339 RHPTC_Zone2FltHVHigh "24.02.06";
BA_ "UserSigValidity" SG_ 339 RHPTC_Zone2FltOverCurrent 7;
BA_ "Version" SG_ 339 RHPTC_Zone2FltOverCurrent "24.02.06";
BA_ "UserSigValidity" SG_ 339 RHPTC_Zone2FltThermalShutDn 7;
BA_ "Version" SG_ 339 RHPTC_Zone2FltThermalShutDn "24.02.06";
BA_ "UserSigValidity" SG_ 339 RHPTC_Zone2FltPcbThermalShutDn 7;
BA_ "Version" SG_ 339 RHPTC_Zone2FltPcbThermalShutDn "24.02.06";
BA_ "UserSigValidity" SG_ 339 RHPTC_Zone2FltMsgTmOutATCU 7;
BA_ "Version" SG_ 339 RHPTC_Zone2FltMsgTmOutATCU "24.02.06";
BA_ "UserSigValidity" SG_ 339 RHPTC_Zone2FailHVSnr 7;
BA_ "Version" SG_ 339 RHPTC_Zone2FailHVSnr "24.02.06";
VAL_ 864 L_ATCU_Lib_MngrDEFBuf0 0 "KeyOff" 1 "FloorPuge" 2 "Mode" 3 "Num" 4 "RESERVED" 5 "RESERVED" 6 "RESERVED" 7 "RESERVED" ;
VAL_ 864 L_ATCU_Lib_MngrACBuf0 0 "DEF" 1 "RemoteFATC_DEF" 2 "SMKRemoteFATC" 3 "Washer" 4 "MIX" 5 "AirPurify" 6 "ADS" 7 "ManualSw" 8 "MAXCool" 9 "Auto" 10 "Num" 11 "RESERVED" 12 "RESERVED" 13 "RESERVED" 14 "RESERVED" 15 "RESERVED" ;
VAL_ 864 L_ATCU_Lib_MngrACBuf1 0 "DEF" 1 "RemoteFATC_DEF" 2 "SMKRemoteFATC" 3 "Washer" 4 "MIX" 5 "AirPurify" 6 "ADS" 7 "ManualSw" 8 "MAXCool" 9 "Auto" 10 "Num" 11 "RESERVED" 12 "RESERVED" 13 "RESERVED" 14 "RESERVED" 15 "RESERVED" ;
VAL_ 864 L_ATCU_Lib_MngrACBuf2 0 "DEF" 1 "RemoteFATC_DEF" 2 "SMKRemoteFATC" 3 "Washer" 4 "MIX" 5 "AirPurify" 6 "ADS" 7 "ManualSw" 8 "MAXCool" 9 "Auto" 10 "Num" 11 "RESERVED" 12 "RESERVED" 13 "RESERVED" 14 "RESERVED" 15 "RESERVED" ;
VAL_ 864 L_ATCU_Lib_MngrACBuf3 0 "DEF" 1 "RemoteFATC_DEF" 2 "SMKRemoteFATC" 3 "Washer" 4 "MIX" 5 "AirPurify" 6 "ADS" 7 "ManualSw" 8 "MAXCool" 9 "Auto" 10 "Num" 11 "RESERVED" 12 "RESERVED" 13 "RESERVED" 14 "RESERVED" 15 "RESERVED" ;
VAL_ 864 L_ATCU_Lib_MngrACBuf4 0 "DEF" 1 "RemoteFATC_DEF" 2 "SMKRemoteFATC" 3 "Washer" 4 "MIX" 5 "AirPurify" 6 "ADS" 7 "ManualSw" 8 "MAXCool" 9 "Auto" 10 "Num" 11 "RESERVED" 12 "RESERVED" 13 "RESERVED" 14 "RESERVED" 15 "RESERVED" ;
VAL_ 864 L_ATCU_Lib_MngrDEFBuf1 0 "KeyOff" 1 "FloorPuge" 2 "Mode" 3 "Num" 4 "RESERVED" 5 "RESERVED" 6 "RESERVED" 7 "RESERVED" ;
VAL_ 864 L_ATCU_Lib_MngrACBuf5 0 "DEF" 1 "RemoteFATC_DEF" 2 "SMKRemoteFATC" 3 "Washer" 4 "MIX" 5 "AirPurify" 6 "ADS" 7 "ManualSw" 8 "MAXCool" 9 "Auto" 10 "Num" 11 "RESERVED" 12 "RESERVED" 13 "RESERVED" 14 "RESERVED" 15 "RESERVED" ;
VAL_ 864 L_ATCU_Lib_MngrACBuf6 0 "DEF" 1 "RemoteFATC_DEF" 2 "SMKRemoteFATC" 3 "Washer" 4 "MIX" 5 "AirPurify" 6 "ADS" 7 "ManualSw" 8 "MAXCool" 9 "Auto" 10 "Num" 11 "RESERVED" 12 "RESERVED" 13 "RESERVED" 14 "RESERVED" 15 "RESERVED" ;
VAL_ 864 L_ATCU_Lib_MngrACBuf7 0 "DEF" 1 "RemoteFATC_DEF" 2 "SMKRemoteFATC" 3 "Washer" 4 "MIX" 5 "AirPurify" 6 "ADS" 7 "ManualSw" 8 "MAXCool" 9 "Auto" 10 "Num" 11 "RESERVED" 12 "RESERVED" 13 "RESERVED" 14 "RESERVED" 15 "RESERVED" ;
VAL_ 864 L_ATCU_Lib_MngrDEFBufLow1 0 "ADS" 1 "SmrtVent" 2 "Num" 3 "RESERVED" ;
VAL_ 864 L_ATCU_Lib_MngrTempBufLow1 0 "EvapDry" 1 "ADS" 2 "PECbyDEF" 3 "Num" ;
VAL_ 864 L_ATCU_Lib_MngrTempBufLow0 0 "EvapDry" 1 "ADS" 2 "PECbyDEF" 3 "Num" ;
VAL_ 864 L_ATCU_Lib_MngrIntakeBufHi0 0 "BATCooling" 1 "HighSpeed" 2 "Num" 3 "RESERVED" ;
VAL_ 864 L_ATCU_Lib_MngrIntakeBufHi1 0 "BATCooling" 1 "HighSpeed" 2 "Num" 3 "RESERVED" ;
VAL_ 864 L_ATCU_Lib_MngrIntakeBufLow2 0 "PTG" 1 "PartialIntake" 2 "ISG" 3 "RESERVED" ;
VAL_ 864 L_ATCU_Lib_MngrDEFBufLow0 0 "ADS" 1 "SmrtVent" 2 "Num" 3 "RESERVED" ;
VAL_ 864 L_ATCU_Lib_MngrDEFBuf2 0 "KeyOff" 1 "FloorPuge" 2 "Mode" 3 "Num" 4 "RESERVED" 5 "RESERVED" 6 "RESERVED" 7 "RESERVED" ;
VAL_ 776 MON_AutoDrvModState 0 "Off" 1 "Floor" 2 "Vent" 3 "BL" 4 "Def_EU" 5 "Mix" 6 "Def_Vent" 7 "All" 8 "Vent_Bleed" 9 "Floor_100" 10 "Warm_Floor" 11 "Cool_Mix" 12 "Def" 13 "RESERVED" 14 "RESERVED" 15 "None" ;
VAL_ 776 MON_AutoIntakeState 0 "FRE(0.0%)" 1 "1~0x3E7:Intake(0.1~99.9%)" 999 "1~0x3E7:Intake(0.1~99.9%)" 1000 "REC(100.0%)" 1001 "RESERVED" 1002 "RESERVED" 1003 "RESERVED" 1004 "RESERVED" 1005 "RESERVED" 1006 "RESERVED" 1007 "RESERVED" 1008 "RESERVED" 1009 "RESERVED" 1010 "RESERVED" 1011 "RESERVED" 1012 "RESERVED" 1013 "RESERVED" 1014 "RESERVED" 1015 "RESERVED" 1016 "RESERVED" 1017 "RESERVED" 1018 "RESERVED" 1019 "RESERVED" 1020 "RESERVED" 1021 "RESERVED" 1022 "RESERVED" 1023 "None" ;
VAL_ 776 MON_AutoACState 0 "Off" 1 "On" 2 "Reserved" 3 "Invalid" ;
VAL_ 776 MON_AutoEvapTargetTemp 0 "0x0~0x258:-20.0~40.0¡É" 600 "0x0~0x258:-20.0~40.0¡É" 601 "259~0xFFFE:RESERVED" 65534 "259~0xFFFE:RESERVED" 65535 "Invalid" ;
VAL_ 776 MON_AutoBlrVtgVal 0 "0x0~0x34BC:0~13.500V" 13500 "0x0~0x34BC:0~13.500V" 13501 "34BD~0xFFFE:RESERVED" 65534 "34BD~0xFFFE:RESERVED" 65535 "None" ;
VAL_ 777 MON_AutoAstTargetTempVal 0 "0x0~0x3EB:-40.0~60.0¡É" 1003 "0x0~0x3EB:-40.0~60.0¡É" 1004 "3EC~0xFFFE:RESERVED" 65534 "3EC~0xFFFE:RESERVED" 65535 "Invalid" ;
VAL_ 777 MON_AutoAstTempDrState 0 "0x0~0x3E8:0~100.0%" 1000 "0x0~0x3E8:0~100.0%" 1001 "RESERVED" 1002 "RESERVED" 1003 "RESERVED" 1004 "RESERVED" 1005 "RESERVED" 1006 "RESERVED" 1007 "RESERVED" 1008 "RESERVED" 1009 "RESERVED" 1010 "RESERVED" 1011 "RESERVED" 1012 "RESERVED" 1013 "RESERVED" 1014 "RESERVED" 1015 "RESERVED" 1016 "RESERVED" 1017 "RESERVED" 1018 "RESERVED" 1019 "RESERVED" 1020 "RESERVED" 1021 "RESERVED" 1022 "RESERVED" 1023 "None" ;
VAL_ 777 MON_AutoDrvTargetTempVal 0 "0x0~0x3EB:-40.0~60.0¡É" 1003 "0x0~0x3EB:-40.0~60.0¡É" 1004 "3EC~0xFFFE:RESERVED" 65534 "3EC~0xFFFE:RESERVED" 65535 "Invalid" ;
VAL_ 777 MON_AutoDrvTempDrState 0 "0x0~0x3E8:0~100.0%" 1000 "0x0~0x3E8:0~100.0%" 1001 "RESERVED" 1002 "RESERVED" 1003 "RESERVED" 1004 "RESERVED" 1005 "RESERVED" 1006 "RESERVED" 1007 "RESERVED" 1008 "RESERVED" 1009 "RESERVED" 1010 "RESERVED" 1011 "RESERVED" 1012 "RESERVED" 1013 "RESERVED" 1014 "RESERVED" 1015 "RESERVED" 1016 "RESERVED" 1017 "RESERVED" 1018 "RESERVED" 1019 "RESERVED" 1020 "RESERVED" 1021 "RESERVED" 1022 "RESERVED" 1023 "None" ;
VAL_ 1025 L_EVNT_HU_FrDrEVntSidePtDisp_X 0 "Default" 1 "001~0x780:PHY=HEX*1 + 0" 1920 "001~0x780:PHY=HEX*1 + 0" 1921 "781~0x7FE:RESERVED" 2046 "781~0x7FE:RESERVED" 2047 "Invalid" ;
VAL_ 1025 L_EVNT_HU_FrDrEVntSidePtDisp_Y 0 "Default" 1 "001~0x780:PHY=HEX*1 + 0" 1920 "001~0x780:PHY=HEX*1 + 0" 1921 "781~0x7FE:RESERVED" 2046 "781~0x7FE:RESERVED" 2047 "Invalid" ;
VAL_ 1025 L_EVNT_HU_FrDrEVntCtrPtDisp_X 0 "Default" 1 "001~0x780:PHY=HEX*1 + 0" 1920 "001~0x780:PHY=HEX*1 + 0" 1921 "781~0x7FE:RESERVED" 2046 "781~0x7FE:RESERVED" 2047 "Invalid" ;
VAL_ 1025 L_EVNT_HU_FrDrEVntCtrPtDisp_Y 0 "Default" 1 "001~0x780:PHY=HEX*1 + 0" 1920 "001~0x780:PHY=HEX*1 + 0" 1921 "781~0x7FE:RESERVED" 2046 "781~0x7FE:RESERVED" 2047 "Invalid" ;
VAL_ 1026 L_EVNT_HU_FrPsEVntSidePtDisp_X 0 "Default" 1 "001~0x780:PHY=HEX*1 + 0" 1920 "001~0x780:PHY=HEX*1 + 0" 1921 "781~0x7FE:RESERVED" 2046 "781~0x7FE:RESERVED" 2047 "Invalid" ;
VAL_ 1026 L_EVNT_HU_FrPsEVntSidePtDisp_Y 0 "Default" 1 "001~0x780:PHY=HEX*1 + 0" 1920 "001~0x780:PHY=HEX*1 + 0" 1921 "781~0x7FE:RESERVED" 2046 "781~0x7FE:RESERVED" 2047 "Invalid" ;
VAL_ 1026 L_EVNT_HU_FrPsEVntCtrPtDisp_X 0 "Default" 1 "001~0x780:PHY=HEX*1 + 0" 1920 "001~0x780:PHY=HEX*1 + 0" 1921 "781~0x7FE:RESERVED" 2046 "781~0x7FE:RESERVED" 2047 "Invalid" ;
VAL_ 1026 L_EVNT_HU_FrPsEVntCtrPtDisp_Y 0 "Default" 1 "001~0x780:PHY=HEX*1 + 0" 1920 "001~0x780:PHY=HEX*1 + 0" 1921 "781~0x7FE:RESERVED" 2046 "781~0x7FE:RESERVED" 2047 "Invalid" ;
VAL_ 1027 L_EVNT_HU_RrDrEVntConsPtDisp_X 0 "Default" 1 "001~0x780:PHY=HEX*1 + 0" 1920 "001~0x780:PHY=HEX*1 + 0" 1921 "781~0x7FE:RESERVED" 2046 "781~0x7FE:RESERVED" 2047 "Invalid" ;
VAL_ 1027 L_EVNT_HU_RrDrEVntConsPtDisp_Y 0 "Default" 1 "001~0x780:PHY=HEX*1 + 0" 1920 "001~0x780:PHY=HEX*1 + 0" 1921 "781~0x7FE:RESERVED" 2046 "781~0x7FE:RESERVED" 2047 "Invalid" ;
VAL_ 1027 L_EVNT_HU_RrPsEVntConsPtDisp_X 0 "Default" 1 "001~0x780:PHY=HEX*1 + 0" 1920 "001~0x780:PHY=HEX*1 + 0" 1921 "781~0x7FE:RESERVED" 2046 "781~0x7FE:RESERVED" 2047 "Invalid" ;
VAL_ 1027 L_EVNT_HU_RrPsEVntConsPtDisp_Y 0 "Default" 1 "001~0x780:PHY=HEX*1 + 0" 1920 "001~0x780:PHY=HEX*1 + 0" 1921 "781~0x7FE:RESERVED" 2046 "781~0x7FE:RESERVED" 2047 "Invalid" ;
VAL_ 1027 L_EVNT_FrDrEVntSideFlt 0 "Default" 1 "No Error" 2 "Error" 3 "Error Indicator" ;
VAL_ 1027 L_EVNT_FrDrEVntCtrFlt 0 "Default" 1 "No Error" 2 "Error" 3 "Error Indicator" ;
VAL_ 1027 L_EVNT_FrPsEVntSideFlt 0 "Default" 1 "No Error" 2 "Error" 3 "Error Indicator" ;
VAL_ 1027 L_EVNT_FrPsEVntCtrFlt 0 "Default" 1 "No Error" 2 "Error" 3 "Error Indicator" ;
VAL_ 1027 L_EVNT_RrDrEVntConsFlt 0 "Default" 1 "No Error" 2 "Error" 3 "Error Indicator" ;
VAL_ 1027 L_EVNT_RrPsEVntConsFlt 0 "Default" 1 "No Error" 2 "Error" 3 "Error Indicator" ;
VAL_ 1028 L_EVNT_FrDrEVntModeSet_Disp 0 "Default" 1 "FOCUS Mode" 2 "SPREAD Mode" 3 "CYCLE Mode" 4 "FREE Mode" 5 "OFF" 6 "RESERVED" 7 "RESERVED" 8 "RESERVED" 9 "RESERVED" 10 "RESERVED" 11 "RESERVED" 12 "RESERVED" 13 "RESERVED" 14 "RESERVED" 15 "Invalid" ;
VAL_ 1028 L_EVNT_RrPsEVntModeSet_Disp 0 "Default" 1 "FOCUS Mode" 2 "SPREAD Mode" 3 "CYCLE Mode" 4 "FREE Mode" 5 "OFF" 6 "RESERVED" 7 "RESERVED" 8 "RESERVED" 9 "RESERVED" 10 "RESERVED" 11 "RESERVED" 12 "RESERVED" 13 "RESERVED" 14 "RESERVED" 15 "Invalid" ;
VAL_ 1028 L_EVNT_FrDrEVntSideOpnClsDisp 0 "Default" 1 "OPEN" 2 "CLOSE" 3 "Invalid" ;
VAL_ 1028 L_EVNT_FrDrEVntCtrOpnClsDisp 0 "Default" 1 "OPEN" 2 "CLOSE" 3 "Invalid" ;
VAL_ 1028 L_EVNT_FrPsEVntSideOpnClsDisp 0 "Default" 1 "OPEN" 2 "CLOSE" 3 "Invalid" ;
VAL_ 1028 L_EVNT_FrPsEVntCtrOpnClsDisp 0 "Default" 1 "OPEN" 2 "CLOSE" 3 "Invalid" ;
VAL_ 1028 L_EVNT_RrDrEVntConsOpnClsDisp 0 "Default" 1 "OPEN" 2 "CLOSE" 3 "Invalid" ;
VAL_ 1028 L_EVNT_RrPsEVntConsOpnClsDisp 0 "Default" 1 "OPEN" 2 "CLOSE" 3 "Invalid" ;
VAL_ 1028 L_EVNT_EVntTouchInform_HU 0 "Default" 1 "APPLY" 2 "NOT APPLY" 3 "Invalid" ;
VAL_ 1028 L_EVNT_EVntTouchInform_CTS 0 "Default" 1 "APPLY" 2 "NOT APPLY" 3 "Invalid" ;
VAL_ 1028 L_EVNT_FrtEvntFocusLvlSta 0 "Default" 1 "1 Level" 2 "2 Level" 3 "3 Level" 4 "4 Level" 5 "5 Level" 6 "RESERVED" 7 "RESERVED" ;
VAL_ 1028 L_EVNT_RrEvntFocusLvlSta 0 "Default" 1 "1 Level" 2 "2 Level" 3 "3 Level" 4 "4 Level" 5 "5 Level" 6 "RESERVED" 7 "RESERVED" ;
VAL_ 1028 L_EVNT_DrVntOpt 0 "Default" 1 "APPLY" 2 "NOT APPLY" 3 "Invalid" ;
VAL_ 1028 L_EVNT_FrPsEVntModeSet_Disp 0 "Default" 1 "FOCUS Mode" 2 "SPREAD Mode" 3 "CYCLE Mode" 4 "FREE Mode" 5 "OFF" 6 "RESERVED" 7 "RESERVED" 8 "RESERVED" 9 "RESERVED" 10 "RESERVED" 11 "RESERVED" 12 "RESERVED" 13 "RESERVED" 14 "RESERVED" 15 "Invalid" ;
VAL_ 1028 L_EVNT_AstVntOpt 0 "Default" 1 "APPLY" 2 "NOT APPLY" 3 "Invalid" ;
VAL_ 1028 L_EVNT_RrDrVntOpt 0 "Default" 1 "APPLY" 2 "NOT APPLY" 3 "Invalid" ;
VAL_ 1028 L_EVNT_RrAstVntOpt 0 "Default" 1 "APPLY" 2 "NOT APPLY" 3 "Invalid" ;
VAL_ 1028 L_EVNT_EVntAutoAirFlowHotKeyOpt 0 "Default" 1 "APPLY" 2 "NOT APPLY" 3 "Invalid" ;
VAL_ 1028 L_EVNT_RrDrEVntModeSet_Disp 0 "Default" 1 "FOCUS Mode" 2 "SPREAD Mode" 3 "CYCLE Mode" 4 "FREE Mode" 5 "OFF" 6 "RESERVED" 7 "RESERVED" 8 "RESERVED" 9 "RESERVED" 10 "RESERVED" 11 "RESERVED" 12 "RESERVED" 13 "RESERVED" 14 "RESERVED" 15 "Invalid" ;
VAL_ 1029 L_EVNT_CTS_FrDrEVntSidePtDisp_X 0 "Default" 1 "001~0x780:PHY=HEX*1 + 0" 1920 "001~0x780:PHY=HEX*1 + 0" 1921 "781~0x7FE:RESERVED" 2046 "781~0x7FE:RESERVED" 2047 "Invalid" ;
VAL_ 1029 L_EVNT_CTS_FrDrEVntSidePtDisp_Y 0 "Default" 1 "001~0x780:PHY=HEX*1 + 0" 1920 "001~0x780:PHY=HEX*1 + 0" 1921 "781~0x7FE:RESERVED" 2046 "781~0x7FE:RESERVED" 2047 "Invalid" ;
VAL_ 1029 L_EVNT_CTS_FrDrEVntCtrPtDisp_X 0 "Default" 1 "001~0x780:PHY=HEX*1 + 0" 1920 "001~0x780:PHY=HEX*1 + 0" 1921 "781~0x7FE:RESERVED" 2046 "781~0x7FE:RESERVED" 2047 "Invalid" ;
VAL_ 1029 L_EVNT_CTS_FrDrEVntCtrPtDisp_Y 0 "Default" 1 "001~0x780:PHY=HEX*1 + 0" 1920 "001~0x780:PHY=HEX*1 + 0" 1921 "781~0x7FE:RESERVED" 2046 "781~0x7FE:RESERVED" 2047 "Invalid" ;
VAL_ 1030 L_EVNT_CTS_FrPsEVntSidePtDisp_X 0 "Default" 1 "001~0x780:PHY=HEX*1 + 0" 1920 "001~0x780:PHY=HEX*1 + 0" 1921 "781~0x7FE:RESERVED" 2046 "781~0x7FE:RESERVED" 2047 "Invalid" ;
VAL_ 1030 L_EVNT_CTS_FrPsEVntSidePtDisp_Y 0 "Default" 1 "001~0x780:PHY=HEX*1 + 0" 1920 "001~0x780:PHY=HEX*1 + 0" 1921 "781~0x7FE:RESERVED" 2046 "781~0x7FE:RESERVED" 2047 "Invalid" ;
VAL_ 1030 L_EVNT_CTS_FrPsEVntCtrPtDisp_X 0 "Default" 1 "001~0x780:PHY=HEX*1 + 0" 1920 "001~0x780:PHY=HEX*1 + 0" 1921 "781~0x7FE:RESERVED" 2046 "781~0x7FE:RESERVED" 2047 "Invalid" ;
VAL_ 1030 L_EVNT_CTS_FrPsEVntCtrPtDisp_Y 0 "Default" 1 "001~0x780:PHY=HEX*1 + 0" 1920 "001~0x780:PHY=HEX*1 + 0" 1921 "781~0x7FE:RESERVED" 2046 "781~0x7FE:RESERVED" 2047 "Invalid" ;
VAL_ 1031 L_EVNT_CTS_RrDrEVntConsPtDisp_X 0 "Default" 1 "001~0x780:PHY=HEX*1 + 0" 1920 "001~0x780:PHY=HEX*1 + 0" 1921 "781~0x7FE:RESERVED" 2046 "781~0x7FE:RESERVED" 2047 "Invalid" ;
VAL_ 1031 L_EVNT_CTS_RrDrEVntConsPtDisp_Y 0 "Default" 1 "001~0x780:PHY=HEX*1 + 0" 1920 "001~0x780:PHY=HEX*1 + 0" 1921 "781~0x7FE:RESERVED" 2046 "781~0x7FE:RESERVED" 2047 "Invalid" ;
VAL_ 1031 L_EVNT_CTS_RrPsEVntConsPtDisp_X 0 "Default" 1 "001~0x780:PHY=HEX*1 + 0" 1920 "001~0x780:PHY=HEX*1 + 0" 1921 "781~0x7FE:RESERVED" 2046 "781~0x7FE:RESERVED" 2047 "Invalid" ;
VAL_ 1031 L_EVNT_CTS_RrPsEVntConsPtDisp_Y 0 "Default" 1 "001~0x780:PHY=HEX*1 + 0" 1920 "001~0x780:PHY=HEX*1 + 0" 1921 "781~0x7FE:RESERVED" 2046 "781~0x7FE:RESERVED" 2047 "Invalid" ;
VAL_ 1032 L_EVNT_ATCUComFlt 0 "Default" 1 "No Error" 2 "Error" 3 "Error Indicator" ;
VAL_ 1032 L_EVNT_DrvCntrHorComFlt 0 "Default" 1 "No Error" 2 "Error" 3 "Error Indicator" ;
VAL_ 1032 L_EVNT_AstSdVertComFlt 0 "Default" 1 "No Error" 2 "Error" 3 "Error Indicator" ;
VAL_ 1032 L_EVNT_AstSdHorComFlt 0 "Default" 1 "No Error" 2 "Error" 3 "Error Indicator" ;
VAL_ 1032 L_EVNT_AstCntrVertComFlt 0 "Default" 1 "No Error" 2 "Error" 3 "Error Indicator" ;
VAL_ 1032 L_EVNT_AstCntrHorComFlt 0 "Default" 1 "No Error" 2 "Error" 3 "Error Indicator" ;
VAL_ 1032 L_EVNT_EVNTFlt 0 "Default" 1 "No Error" 2 "Error" 3 "Error Indicator" ;
VAL_ 1032 L_EVNT_RrDrvCnslVertComFlt 0 "Default" 1 "No Error" 2 "Error" 3 "Error Indicator" ;
VAL_ 1032 L_EVNT_RrDrvCnslHorComFlt 0 "Default" 1 "No Error" 2 "Error" 3 "Error Indicator" ;
VAL_ 1032 L_EVNT_RrAstCnslVertComFlt 0 "Default" 1 "No Error" 2 "Error" 3 "Error Indicator" ;
VAL_ 1032 L_EVNT_RrAstCnslHorComFlt 0 "Default" 1 "No Error" 2 "Error" 3 "Error Indicator" ;
VAL_ 1032 L_EVNT_DrvSdVertIntFlt 0 "Default" 1 "No Error" 2 "Error" 3 "Error Indicator" ;
VAL_ 1032 L_EVNT_DrvSdHorIntFlt 0 "Default" 1 "No Error" 2 "Error" 3 "Error Indicator" ;
VAL_ 1032 L_EVNT_DrvCntrVertIntFlt 0 "Default" 1 "No Error" 2 "Error" 3 "Error Indicator" ;
VAL_ 1032 L_EVNT_DrvCntrHorIntFlt 0 "Default" 1 "No Error" 2 "Error" 3 "Error Indicator" ;
VAL_ 1032 L_EVNT_AstSdVertIntFlt 0 "Default" 1 "No Error" 2 "Error" 3 "Error Indicator" ;
VAL_ 1032 L_EVNT_AstSdHorIntFlt 0 "Default" 1 "No Error" 2 "Error" 3 "Error Indicator" ;
VAL_ 1032 L_EVNT_DrvSdVertComFlt 0 "Default" 1 "No Error" 2 "Error" 3 "Error Indicator" ;
VAL_ 1032 L_EVNT_AstCntrVertIntFlt 0 "Default" 1 "No Error" 2 "Error" 3 "Error Indicator" ;
VAL_ 1032 L_EVNT_AstCntrHorIntFlt 0 "Default" 1 "No Error" 2 "Error" 3 "Error Indicator" ;
VAL_ 1032 L_EVNT_RrDrvCnslVertIntFlt 0 "Default" 1 "No Error" 2 "Error" 3 "Error Indicator" ;
VAL_ 1032 L_EVNT_RrDrvCnslHorIntFlt 0 "Default" 1 "No Error" 2 "Error" 3 "Error Indicator" ;
VAL_ 1032 L_EVNT_RrAstCnslVertIntFlt 0 "Default" 1 "No Error" 2 "Error" 3 "Error Indicator" ;
VAL_ 1032 L_EVNT_RrAstCnslHorIntFlt 0 "Default" 1 "No Error" 2 "Error" 3 "Error Indicator" ;
VAL_ 1032 L_EVNT_DrvSdVertExtFlt 0 "Default" 1 "No Error" 2 "Error" 3 "Error Indicator" ;
VAL_ 1032 L_EVNT_DrvSdHorExtFlt 0 "Default" 1 "No Error" 2 "Error" 3 "Error Indicator" ;
VAL_ 1032 L_EVNT_DrvCntrVertExtFlt 0 "Default" 1 "No Error" 2 "Error" 3 "Error Indicator" ;
VAL_ 1032 L_EVNT_DrvCntrHorExtFlt 0 "Default" 1 "No Error" 2 "Error" 3 "Error Indicator" ;
VAL_ 1032 L_EVNT_DrvSdHorComFlt 0 "Default" 1 "No Error" 2 "Error" 3 "Error Indicator" ;
VAL_ 1032 L_EVNT_AstSdVertExtFlt 0 "Default" 1 "No Error" 2 "Error" 3 "Error Indicator" ;
VAL_ 1032 L_EVNT_AstSdHorExtFlt 0 "Default" 1 "No Error" 2 "Error" 3 "Error Indicator" ;
VAL_ 1032 L_EVNT_DrvCntrVertComFlt 0 "Default" 1 "No Error" 2 "Error" 3 "Error Indicator" ;
VAL_ 1033 L_EVNT_AstCntrVertExtFlt 0 "Default" 1 "No Error" 2 "Error" 3 "Error Indicator" ;
VAL_ 1033 L_EVNT_RrAstCnslHorExtFlt 0 "Default" 1 "No Error" 2 "Error" 3 "Error Indicator" ;
VAL_ 1033 L_EVNT_AstCntrHorExtFlt 0 "Default" 1 "No Error" 2 "Error" 3 "Error Indicator" ;
VAL_ 1033 L_EVNT_AllResetOpSta 0 "Normal" 1 "Reset Complete" 2 "Reset Fail" 3 "RESERVED" ;
VAL_ 1033 L_EVNT_DrvSdVertResetOpSta 0 "Normal" 1 "Reset Complete" 2 "Reset Fail" 3 "RESERVED" ;
VAL_ 1033 L_EVNT_RrDrvCnslVertExtFlt 0 "Default" 1 "No Error" 2 "Error" 3 "Error Indicator" ;
VAL_ 1033 L_EVNT_DrvSdHorResetOpSta 0 "Normal" 1 "Reset Complete" 2 "Reset Fail" 3 "RESERVED" ;
VAL_ 1033 L_EVNT_DrvCntrVertResetOpSta 0 "Normal" 1 "Reset Complete" 2 "Reset Fail" 3 "RESERVED" ;
VAL_ 1033 L_EVNT_DrvCntrHorResetOpSta 0 "Normal" 1 "Reset Complete" 2 "Reset Fail" 3 "RESERVED" ;
VAL_ 1033 L_EVNT_AstSdVertResetOpSta 0 "Normal" 1 "Reset Complete" 2 "Reset Fail" 3 "RESERVED" ;
VAL_ 1033 L_EVNT_AstSdHorResetOpSta 0 "Normal" 1 "Reset Complete" 2 "Reset Fail" 3 "RESERVED" ;
VAL_ 1033 L_EVNT_AstCntrVertResetOpSta 0 "Normal" 1 "Reset Complete" 2 "Reset Fail" 3 "RESERVED" ;
VAL_ 1033 L_EVNT_AstCntrHorResetOpSta 0 "Normal" 1 "Reset Complete" 2 "Reset Fail" 3 "RESERVED" ;
VAL_ 1033 L_EVNT_RrDrvCnslVertResetOpSta 0 "Normal" 1 "Reset Complete" 2 "Reset Fail" 3 "RESERVED" ;
VAL_ 1033 L_EVNT_RrDrvCnslHorResetOpSta 0 "Normal" 1 "Reset Complete" 2 "Reset Fail" 3 "RESERVED" ;
VAL_ 1033 L_EVNT_RrAstCnslVertResetOpSta 0 "Normal" 1 "Reset Complete" 2 "Reset Fail" 3 "RESERVED" ;
VAL_ 1033 L_EVNT_RrDrvCnslHorExtFlt 0 "Default" 1 "No Error" 2 "Error" 3 "Error Indicator" ;
VAL_ 1033 L_EVNT_RrAstCnslHorResetOpSta 0 "Normal" 1 "Reset Complete" 2 "Reset Fail" 3 "RESERVED" ;
VAL_ 1033 L_EVNT_ResetOpSta 0 "Normal" 1 "Reset Complete" 2 "Reset Fail" 3 "RESERVED" ;
VAL_ 1033 L_EVNT_RrAstCnslVertExtFlt 0 "Default" 1 "No Error" 2 "Error" 3 "Error Indicator" ;
VAL_ 326 FHPTC_2ndPsRdySta 0 "Not Ready(Disable to control)" 1 "Ready (Enable to Control)" ;
VAL_ 326 FHPTC_2ndPsOpSta 0 "Stop Mode" 1 "Operation Mode" 2 "Failure Mode" 3 "Limited operation Mode" ;
VAL_ 326 FHPTC_2ndPsCnsmptPwr_W 0 "0x0~0x2710:Power" 10000 "0x0~0x2710:Power" 65535 "ERROR" ;
VAL_ 326 FHPTC_2ndPsCtrlTyp 0 "Single PTC & Single Control" 1 "Dual PTC & Single Control" 2 "Dual PTC & Dual Control" ;
VAL_ 326 FHPTC_2ndPsVoltage_V 0 "0x0~0xFA:Voltage" 250 "0x0~0xFA:Voltage" 251 "RESERVED0xFF:ERROR" 252 "RESERVED0xFF:ERROR" 253 "RESERVED0xFF:ERROR" 254 "RESERVED0xFF:ERROR" ;
VAL_ 326 FHPTC_2ndPsCurrent_A 0 "0x0~0xFA:Current" 250 "0x0~0xFA:Current" 251 "RESERVED" 252 "RESERVED" 253 "RESERVED" 254 "RESERVED" 255 "ERROR" ;
VAL_ 326 FHPTC_2ndPsDutyFB_Pec 0 "0x0~0xC8:Duty" 200 "0x0~0xC8:Duty" 201 "RESERVED" 202 "RESERVED" 203 "RESERVED" 204 "RESERVED" 205 "RESERVED" 206 "RESERVED" 207 "RESERVED" 208 "RESERVED" 209 "RESERVED" 210 "RESERVED" 211 "RESERVED" 212 "RESERVED" 213 "RESERVED" 214 "RESERVED" 215 "RESERVED" 216 "RESERVED" 217 "RESERVED" 218 "RESERVED" 219 "RESERVED" 220 "RESERVED" 221 "RESERVED" 222 "RESERVED" 223 "RESERVED" 224 "RESERVED" 225 "RESERVED" 226 "RESERVED" 227 "RESERVED" 228 "RESERVED" 229 "RESERVED" 230 "RESERVED" 231 "RESERVED" 232 "RESERVED" 233 "RESERVED" 234 "RESERVED" 235 "RESERVED" 236 "RESERVED" 237 "RESERVED" 238 "RESERVED" 239 "RESERVED" 240 "RESERVED" 241 "RESERVED" 242 "RESERVED" 243 "RESERVED" 244 "RESERVED" 245 "RESERVED" 246 "RESERVED" 247 "RESERVED" 248 "RESERVED" 249 "RESERVED" 250 "RESERVED" 251 "RESERVED" 252 "RESERVED" 253 "RESERVED" 254 "RESERVED" 255 "ERROR" ;
VAL_ 326 FHPTC_2ndPsDutyFB_IGBT 0 "0x0~0xC8:Duty" 200 "0x0~0xC8:Duty" 201 "RESERVED" 202 "RESERVED" 203 "RESERVED" 204 "RESERVED" 205 "RESERVED" 206 "RESERVED" 207 "RESERVED" 208 "RESERVED" 209 "RESERVED" 210 "RESERVED" 211 "RESERVED" 212 "RESERVED" 213 "RESERVED" 214 "RESERVED" 215 "RESERVED" 216 "RESERVED" 217 "RESERVED" 218 "RESERVED" 219 "RESERVED" 220 "RESERVED" 221 "RESERVED" 222 "RESERVED" 223 "RESERVED" 224 "RESERVED" 225 "RESERVED" 226 "RESERVED" 227 "RESERVED" 228 "RESERVED" 229 "RESERVED" 230 "RESERVED" 231 "RESERVED" 232 "RESERVED" 233 "RESERVED" 234 "RESERVED" 235 "RESERVED" 236 "RESERVED" 237 "RESERVED" 238 "RESERVED" 239 "RESERVED" 240 "RESERVED" 241 "RESERVED" 242 "RESERVED" 243 "RESERVED" 244 "RESERVED" 245 "RESERVED" 246 "RESERVED" 247 "RESERVED" 248 "RESERVED" 249 "RESERVED" 250 "RESERVED" 251 "RESERVED" 252 "RESERVED" 253 "RESERVED" 254 "RESERVED" 255 "ERROR" ;
VAL_ 326 FHPTC_2ndPsCoreTemp_C 0 "0x0~0xF0:Temperature" 240 "0x0~0xF0:Temperature" 241 "RESERVED/0XFD:The thermister is open" 242 "RESERVED/0XFD:The thermister is open" 243 "RESERVED/0XFD:The thermister is open" 244 "RESERVED/0XFD:The thermister is open" 245 "RESERVED/0XFD:The thermister is open" 246 "RESERVED/0XFD:The thermister is open" 247 "RESERVED/0XFD:The thermister is open" 248 "RESERVED/0XFD:The thermister is open" 249 "RESERVED/0XFD:The thermister is open" 250 "RESERVED/0XFD:The thermister is open" 251 "RESERVED/0XFD:The thermister is open" 252 "RESERVED/0XFD:The thermister is open" 254 "The thermister is short" 255 "ERROR" ;
VAL_ 65 HKBD_SW_Ver1 0 "0x00~0x7E:ASCII value" 126 "0x00~0x7E:ASCII value" 127 "Invalid" ;
VAL_ 65 HKBD_SW_Ver2 0 "0x00~0x7E:ASCII value" 126 "0x00~0x7E:ASCII value" 127 "Invalid" ;
VAL_ 65 HKBD_SW_Ver3 0 "0x00~0x7E:ASCII value" 126 "0x00~0x7E:ASCII value" 127 "Invalid" ;
VAL_ 66 HKBD_Fr_DrModDnSw 0 "Off" 1 "On" ;
VAL_ 66 HKBD_Fr_DrModUpSw 0 "Off" 1 "On" ;
VAL_ 66 HKBD_Fr_DrMultiAutoSw 0 "RESERVED" 1 "Low" 2 "Medium" 3 "High" 4 "RESERVED" 5 "RESERVED" 6 "RESERVED" 7 "Invalid" ;
VAL_ 66 HKBD_Fr_PsAutoSw 0 "Off" 1 "On" ;
VAL_ 66 HKBD_Fr_PsMultiAutoSw 0 "RESERVED" 1 "Low" 2 "Medium" 3 "High" 4 "RESERVED" 5 "RESERVED" 6 "RESERVED" 7 "Invalid" ;
VAL_ 66 HKBD_Fr_AcSw 0 "Off" 1 "On" ;
VAL_ 66 HKBD_Fr_DefSw 0 "Off" 1 "On" ;
VAL_ 66 HKBD_Fr_RecSw 0 "Off" 1 "On" ;
VAL_ 66 HKBD_Fr_DrModVntSw 0 "Off" 1 "On" ;
VAL_ 66 HKBD_Fr_FreSw 0 "Off" 1 "On" ;
VAL_ 66 HKBD_Fr_IntakeTglSw 0 "Off" 1 "On" ;
VAL_ 66 HKBD_Fr_OffSw 0 "Off" 1 "On" ;
VAL_ 66 HKBD_Fr_SyncSw 0 "Off" 1 "On" ;
VAL_ 66 HKBD_Fr_RrDefInd 0 "Off" 1 "On" ;
VAL_ 66 HKBD_Fr_RrDefSw 0 "Off" 1 "On" ;
VAL_ 66 HKBD_Fr_ArclnSw 0 "Off" 1 "On" ;
VAL_ 66 HKBD_Fr_DrOnlySw 0 "Off" 1 "On" ;
VAL_ 66 HKBD_Fr_ClimateSw 0 "Off" 1 "On" ;
VAL_ 66 HKBD_Fr_PerfumeSw 0 "Off" 1 "On" ;
VAL_ 66 HKBD_Fr_DrModFlrSw 0 "Off" 1 "On" ;
VAL_ 66 HKBD_Fr_HptIntnstySta 0 "Default" 1 "Haptic OFF" 2 "Haptic Intensity Level 1" 3 "Haptic Intensity Level 2" 4 "Haptic Intensity Level 3" 5 "Haptic Intensity Level 4" 6 "Haptic Intensity Level 5" 7 "RESERVED" 8 "RESERVED" 9 "RESERVED" 10 "RESERVED" 11 "RESERVED" 12 "RESERVED" 13 "RESERVED" 14 "RESERVED" 15 "Invalid" ;
VAL_ 66 HKBD_Fr_StrWhlHeatSw 0 "Off" 1 "On" ;
VAL_ 66 HKBD_FLStHeatSw 0 "Off" 1 "On" ;
VAL_ 66 HKBD_FLStVentSw 0 "Off" 1 "On" ;
VAL_ 66 HKBD_FRStHeatSw 0 "Off" 1 "On" ;
VAL_ 66 HKBD_FRStVentSw 0 "Off" 1 "On" ;
VAL_ 66 HKBD_FLStTumblrSw 0 "Default" 1 "Up" 2 "Down" 3 "Error Indicator" ;
VAL_ 66 HKBD_Fr_DrModDefSw 0 "Off" 1 "On" ;
VAL_ 66 HKBD_FRStTumblrSw 0 "Default" 1 "Up" 2 "Down" 3 "Error Indicator" ;
VAL_ 66 HKBD_Fr_FrWndShldHtSw 0 "Off" 1 "On" ;
VAL_ 66 HKBD_Fr_DrAutoDnSw 0 "Off" 1 "On" ;
VAL_ 66 HKBD_Fr_DrAutoUpSw 0 "Off" 1 "On" ;
VAL_ 66 HKBD_Fr_DrModSw 0 "Off" 1 "On" ;
VAL_ 66 HKBD_Fr_PsModSw 0 "Off" 1 "On" ;
VAL_ 66 HKBD_DisplayTheme 0 "Default" 1 "White Theme" 2 "Black Theme" 3 "Invalid" ;
VAL_ 66 HKBD_Fr_PsModDnSw 0 "Off" 1 "On" ;
VAL_ 66 HKBD_Fr_SmartZoneSW 0 "Default(Off)" 1 "On" ;
VAL_ 66 HKBD_Fr_ModSet 0 "Default" 1 "VENT" 2 "B_L" 3 "FLOOR" 4 "MIX" 5 "DEF (MAX DEF)" 6 "RESERVED" 7 "7 Mode DEF_VENT" 8 "RESERVED" 9 "7 Mode DEF_VENT_FLOOR" 10 "7 Mode DEF" 11 "RESERVED" 12 "RESERVED" 13 "RESERVED" 14 "RESERVED" 15 "Error Indicator" ;
VAL_ 66 HKBD_Fr_MTCTempLvlSet 0 "Default" 1 "Max AC" 2 "0step" 3 "1step" 4 "2step" 5 "3step" 6 "4step" 7 "5step" 8 "6step" 9 "7step" 10 "8step" 11 "9step" 12 "10step" 13 "11step" 14 "12step" 15 "13step" 16 "14step" 17 "15step" 18 "16step" 19 "RESERVED" 20 "RESERVED" 21 "RESERVED" 22 "RESERVED" 23 "RESERVED" 24 "RESERVED" 25 "RESERVED" 26 "RESERVED" 27 "RESERVED" 28 "RESERVED" 29 "RESERVED" 30 "RESERVED" 31 "Error Indicator" ;
VAL_ 66 HKBD_Fr_PsModUpSw 0 "Off" 1 "On" ;
VAL_ 66 HKBD_Fr_PsModVntSw 0 "Off" 1 "On" ;
VAL_ 66 HKBD_Fr_PsModFlrSw 0 "Off" 1 "On" ;
VAL_ 66 HKBD_Fr_DrAutoSw 0 "Off" 1 "On" ;
VAL_ 67 HKBD_Fr_DrTempClickCnt 0 "RESERVED" 1 "1~0x7F:clockwise" 127 "1~0x7F:clockwise" 128 "80~0xFE:Counterclockwise" 254 "80~0xFE:Counterclockwise" 255 "Invalid" ;
VAL_ 67 HKBD_Fr_RrTempClickCnt 0 "RESERVED" 1 "1~0x7F:clockwise" 127 "1~0x7F:clockwise" 128 "80~0xFE:Counterclockwise" 254 "80~0xFE:Counterclockwise" 255 "Invalid" ;
VAL_ 67 HKBD_Fr_DrBlwClickCnt 0 "RESERVED" 1 "1~0x7F:clockwise" 127 "1~0x7F:clockwise" 128 "80~0xFE:Counterclockwise" 254 "80~0xFE:Counterclockwise" 255 "Invalid" ;
VAL_ 67 HKBD_Fr_PsBlwClickCnt 0 "RESERVED" 1 "1~0x7F:clockwise" 127 "1~0x7F:clockwise" 128 "80~0xFE:Counterclockwise" 254 "80~0xFE:Counterclockwise" 255 "Invalid" ;
VAL_ 67 HKBD_FrTempKnobCnt 0 "0" 1 "1" 2 "2" 3 "invalid" ;
VAL_ 67 HKBD_FrBlwKnobCnt 0 "0" 1 "1" 2 "2" 3 "invalid" ;
VAL_ 67 HKBD_Fr_PsTempClickCnt 0 "RESERVED" 1 "1~0x7F:clockwise" 127 "1~0x7F:clockwise" 128 "80~0xFE:Counterclockwise" 254 "80~0xFE:Counterclockwise" 255 "Invalid" ;
VAL_ 68 HKBD_Fr_DrTempDnSw 0 "Off" 1 "On" ;
VAL_ 68 HKBD_Fr_DrTempUpSw 0 "Off" 1 "On" ;
VAL_ 68 HKBD_Fr_PsBlwDnSw 0 "Off" 1 "On" ;
VAL_ 68 HKBD_Fr_PsBlwDnOffSw 0 "Off" 1 "On" ;
VAL_ 68 HKBD_Fr_PsBlwUpSw 0 "Off" 1 "On" ;
VAL_ 68 HKBD_Fr_PsBlwSet 0 "Off" 1 "0 Level" 2 "1 Level" 3 "2 Level" 4 "3 Level" 5 "4 Level" 6 "5 Level" 7 "6 Level" 8 "7 Level" 9 "8 Level" 15 "Invalid" ;
VAL_ 68 HKBD_Fr_RrDrTempDnSw 0 "Off" 1 "On" ;
VAL_ 68 HKBD_Fr_RrDrTempUpSw 0 "Off" 1 "On" ;
VAL_ 68 HKBD_Fr_PsTempDnSw 0 "Off" 1 "On" ;
VAL_ 68 HKBD_Fr_RrDrBlwDnSw 0 "Off" 1 "On" ;
VAL_ 68 HKBD_Fr_RrDrBlwDnOffSw 0 "Off" 1 "On" ;
VAL_ 68 HKBD_Fr_RrDrBlwUpSw 0 "Off" 1 "On" ;
VAL_ 68 HKBD_Fr_RrDrBlwSet 0 "Off" 1 "0 Level" 2 "1 Level" 3 "2 Level" 4 "3 Level" 5 "4 Level" 6 "5 Level" 7 "6 Level" 8 "7 Level" 9 "8 Level" 15 "Invalid" ;
VAL_ 68 HKBD_Fr_RrDrModDnSw 0 "Off" 1 "On" ;
VAL_ 68 HKBD_Fr_RrDrModUpSw 0 "Off" 1 "On" ;
VAL_ 68 HKBD_Fr_RrDrModVntSw 0 "Off" 1 "On" ;
VAL_ 68 HKBD_Fr_PsTempUpSw 0 "Off" 1 "On" ;
VAL_ 68 HKBD_Fr_RrDrModFlrSw 0 "Off" 1 "On" ;
VAL_ 68 HKBD_Fr_RrDrModBiLvlSw 0 "Off" 1 "On" ;
VAL_ 68 HKBD_Fr_RrDrAutoSw 0 "Off" 1 "On" ;
VAL_ 68 HKBD_Fr_RrDrMultiAutoSw 0 "RESERVED" 1 "Low" 2 "Medium" 3 "High" 4 "RESERVED" 5 "RESERVED" 6 "RESERVED" 7 "Invalid" ;
VAL_ 68 HKBD_Fr_RrOffSw 0 "Off" 1 "On" ;
VAL_ 68 HKBD_Fr_RrSyncSw 0 "Off" 1 "On" ;
VAL_ 68 HKBD_Fr_RLStHeatSw 0 "Off" 1 "On" ;
VAL_ 68 HKBD_Fr_RLStVentSw 0 "Off" 1 "On" ;
VAL_ 68 HKBD_Fr_DrBlwDnSw 0 "Off" 1 "On" ;
VAL_ 68 HKBD_Fr_RRStHeatSw 0 "Off" 1 "On" ;
VAL_ 68 HKBD_Fr_RRStVentSw 0 "Off" 1 "On" ;
VAL_ 68 HKBD_Fr_RLStTumblrSw 0 "Default" 1 "Up" 2 "Down" 3 "Error Indicator" ;
VAL_ 68 HKBD_Fr_RRStTumblrSw 0 "Default" 1 "Up" 2 "Down" 3 "Error Indicator" ;
VAL_ 68 HKBD_Fr_RrPsModDnSw 0 "Off" 1 "On" ;
VAL_ 68 HKBD_Fr_RrPsModUpSw 0 "Off" 1 "On" ;
VAL_ 68 HKBD_Fr_RrPsModVntSw 0 "Off" 1 "On" ;
VAL_ 68 HKBD_Fr_RrPsModFlrSw 0 "Off" 1 "On" ;
VAL_ 68 HKBD_Fr_DrBlwDnOffSw 0 "Off" 1 "On" ;
VAL_ 68 HKBD_Fr_RrLockSw 0 "Off" 1 "On" ;
VAL_ 68 HKBD_Fr_RrPsModBiLvlSw 0 "Off" 1 "On" ;
VAL_ 68 HKBD_Fr_RrDrModSw 0 "Off" 1 "On" ;
VAL_ 68 HKBD_Fr_RrPsModSw 0 "Off" 1 "On" ;
VAL_ 68 HKBD_Fr_RrPsBlwSet 0 "Off" 1 "0 Level" 2 "1 Level" 3 "2 Level" 4 "3 Level" 5 "4 Level" 6 "5 Level" 7 "6 Level" 8 "7 Level" 9 "8 Level" 15 "Invalid" ;
VAL_ 68 HKBD_Fr_RrPsBlwUpSw 0 "Off" 1 "On" ;
VAL_ 68 HKBD_Fr_RrPsBlwDnSw 0 "Off" 1 "On" ;
VAL_ 68 HKBD_Fr_DrBlwUpSw 0 "Off" 1 "On" ;
VAL_ 68 HKBD_Fr_RrPsBlwDnOffSw 0 "Off" 1 "On" ;
VAL_ 68 HKBD_Fr_RrPsTempDnSw 0 "Off" 1 "On" ;
VAL_ 68 HKBD_Fr_RrPsTempUpSw 0 "Off" 1 "On" ;
VAL_ 68 HKBD_Fr_DrBlwSet 0 "Off" 1 "0 Level" 2 "1 Level" 3 "2 Level" 4 "3 Level" 5 "4 Level" 6 "5 Level" 7 "6 Level" 8 "7 Level" 9 "8 Level" 15 "Invalid" ;
VAL_ 69 HKBD_Fr_3rdRrTempDnSw 0 "Off" 1 "On" ;
VAL_ 69 HKBD_Fr_3rdRrTempUpSw 0 "Off" 1 "On" ;
VAL_ 69 HKBD_Fr_3rdRrModUpSw 0 "Off" 1 "On" ;
VAL_ 69 HKBD_Fr_3rdRrModVntSw 0 "Off" 1 "On" ;
VAL_ 69 HKBD_Fr_3rdRrModFlrSw 0 "Off" 1 "On" ;
VAL_ 69 HKBD_Fr_3rdRrAutoSw 0 "Off" 1 "On" ;
VAL_ 69 HKBD_Fr_3rdRrMultiAutoSw 0 "RESERVED" 1 "Low" 2 "Medium" 3 "High" 4 "RESERVED" 5 "RESERVED" 6 "RESERVED" 7 "Invalid" ;
VAL_ 69 HKBD_Fr_3rdRrOffSw 0 "Off" 1 "On" ;
VAL_ 69 HKBD_Fr_3rdRrSyncSw 0 "Off" 1 "On" ;
VAL_ 69 HKBD_Fr_3rdRrLockSw 0 "Off" 1 "On" ;
VAL_ 69 HKBD_Fr_3rdRrBlwDnSw 0 "Off" 1 "On" ;
VAL_ 69 HKBD_Fr_3rdRrModBiLvlSw 0 "Off" 1 "On" ;
VAL_ 69 HKBD_FrRrTglSet 0 "Default" 1 "On" 2 "Off" 3 "Invalid" ;
VAL_ 69 HKBD_Fr_RrScrnSet 0 "Default" 1 "On" 2 "Off" 3 "Invalid" ;
VAL_ 69 HKBD_Fr_OnOffSet 0 "Default" 1 "On" 2 "Off" 3 "Invalid" ;
VAL_ 69 HKBD_Fr_RrOnOffSet 0 "Default" 1 "On" 2 "Off" 3 "Invalid" ;
VAL_ 69 HKBD_Fr_3rdRrOnOffSet 0 "Default" 1 "On" 2 "Off" 3 "Invalid" ;
VAL_ 69 HKBD_Fr_3rdRrBlwDnOffSw 0 "Off" 1 "On" ;
VAL_ 69 HKBD_Fr_RrPsAutoSw 0 "Off" 1 "On" ;
VAL_ 69 HKBD_Fr_RrPsMultiAutoSw 0 "RESERVED" 1 "Low" 2 "Medium" 3 "High" 4 "RESERVED" 5 "RESERVED" 6 "RESERVED" 7 "Invalid" ;
VAL_ 69 HKBD_Fr_3rdRrModSw 0 "Off" 1 "On" ;
VAL_ 69 HKBD_Fr_RrModSet 0 "Default" 1 "VENT" 2 "B_L" 3 "FLOOR" 4 "RESERVED" 5 "RESERVED" 6 "RESERVED" 7 "RESERVED" 8 "RESERVED" 9 "RESERVED" 10 "RESERVED" 11 "RESERVED" 12 "RESERVED" 13 "RESERVED" 14 "RESERVED" 15 "Error Indicator" ;
VAL_ 69 HKBD_Fr_3rdRrBlwUpSw 0 "Off" 1 "On" ;
VAL_ 69 HKBD_Fr_3rdModSet 0 "Default" 1 "VENT" 2 "B_L" 3 "FLOOR" 4 "RESERVED" 5 "RESERVED" 6 "RESERVED" 7 "RESERVED" 8 "RESERVED" 9 "RESERVED" 10 "RESERVED" 11 "RESERVED" 12 "RESERVED" 13 "RESERVED" 14 "RESERVED" 15 "Error Indicator" ;
VAL_ 69 HKBD_Fr_DrblwUpMaxSw 0 "Off" 1 "On" ;
VAL_ 69 HKBD_Fr_PsblwUpMaxSw 0 "Off" 1 "On" ;
VAL_ 69 HKBD_Fr_3rdRrBlwSet 0 "Off" 1 "0 Level" 2 "1 Level" 3 "2 Level" 4 "3 Level" 5 "4 Level" 6 "5 Level" 7 "6 Level" 8 "7 Level" 9 "8 Level" 15 "Invalid" ;
VAL_ 69 HKBD_Fr_3rdRrModDnSw 0 "Off" 1 "On" ;
VAL_ 70 L_HKBD_ResetOpSta 0 "Normal" 1 "Reser Complete" 2 "Reset Fail" 3 "RESERVED" ;
VAL_ 71 HKBD_Fr_RrDrTempClickCnt 0 "RESERVED" 1 "1~0x7F:clockwise" 127 "1~0x7F:clockwise" 128 "80~0xFE:Counterclockwise" 254 "80~0xFE:Counterclockwise" 255 "Invalid" ;
VAL_ 71 HKBD_Fr_RrPsTempClickCnt 0 "RESERVED" 1 "1~0x7F:clockwise" 127 "1~0x7F:clockwise" 128 "80~0xFE:Counterclockwise" 254 "80~0xFE:Counterclockwise" 255 "Invalid" ;
VAL_ 71 HKBD_Fr_RrPsBlwClickCnt 0 "RESERVED" 1 "1~0x7F:clockwise" 127 "1~0x7F:clockwise" 128 "80~0xFE:Counterclockwise" 254 "80~0xFE:Counterclockwise" 255 "Invalid" ;
VAL_ 71 HKBD_Fr_3rdRrTempClickCnt 0 "RESERVED" 1 "1~0x7F:clockwise" 127 "1~0x7F:clockwise" 128 "80~0xFE:Counterclockwise" 254 "80~0xFE:Counterclockwise" 255 "Invalid" ;
VAL_ 71 HKBD_Fr_3rdRrBlwClickCnt 0 "RESERVED" 1 "1~0x7F:clockwise" 127 "1~0x7F:clockwise" 128 "80~0xFE:Counterclockwise" 254 "80~0xFE:Counterclockwise" 255 "Invalid" ;
VAL_ 71 HKBD_Fr_RrTempKnobCnt 0 "0" 1 "1" 2 "2" 3 "invalid" ;
VAL_ 71 HKBD_Fr_RrBlwKnobCnt 0 "0" 1 "1" 2 "2" 3 "invalid" ;
VAL_ 71 HKBD_Fr_3rdTempKnobCnt 0 "0" 1 "1" 2 "2" 3 "invalid" ;
VAL_ 71 HKBD_Fr_3rdBlwKnobCnt 0 "0" 1 "1" 2 "2" 3 "invalid" ;
VAL_ 71 L_HKBD_HVACPnlBckLight_Res 0 "Invalid(Default)" 1 "On" 2 "Off" 3 "RESERVED" ;
VAL_ 71 HKBD_Fr_RrDrBlwClickCnt 0 "RESERVED" 1 "1~0x7F:clockwise" 127 "1~0x7F:clockwise" 128 "80~0xFE:Counterclockwise" 254 "80~0xFE:Counterclockwise" 255 "Invalid" ;
VAL_ 72 HKBD_Fr_IncarRaw 1023 "Error Indicator" ;
VAL_ 336 RHPTC_Zone1RdySta 0 "Not Ready(Disable to control)" 1 "Ready (Enable to Control)" ;
VAL_ 336 RHPTC_Zone1OpSta 0 "Stop Mode" 1 "Operation Mode" 2 "Failure Mode" 3 "Limited operation Mode" ;
VAL_ 336 RHPTC_Zone1CnsmptPwr_W 0 "0x0~0x2710:Power" 10000 "0x0~0x2710:Power" 65535 "ERROR" ;
VAL_ 336 RHPTC_Zone1Voltage_V 0 "0x0~0xFA:Voltage" 250 "0x0~0xFA:Voltage" 251 "RESERVED" 252 "RESERVED" 253 "RESERVED" 254 "RESERVED" 255 "ERROR" ;
VAL_ 336 RHPTC_Zone1CtrlTyp 0 "Single PTC & Single Control" 1 "Dual PTC & Single Control" 2 "Dual PTC & Dual Control" 3 "RESERVED" 4 "RESERVED" 5 "RESERVED" 6 "RESERVED" 7 "RESERVED" ;
VAL_ 336 RHPTC_Zone1Current_A 0 "0x0~0xFA:Current" 250 "0x0~0xFA:Current" 251 "RESERVED" 252 "RESERVED" 253 "RESERVED" 254 "RESERVED" 255 "ERROR" ;
VAL_ 336 RHPTC_Zone1DutyFB_Pec 0 "0x0~0xC8:Duty" 200 "0x0~0xC8:Duty" 201 "resreved" 202 "resreved" 203 "resreved" 204 "resreved" 205 "resreved" 206 "resreved" 207 "resreved" 208 "resreved" 209 "resreved" 210 "resreved" 211 "resreved" 212 "resreved" 213 "resreved" 214 "resreved" 215 "resreved" 216 "resreved" 217 "resreved" 218 "resreved" 219 "resreved" 220 "resreved" 221 "resreved" 222 "resreved" 223 "resreved" 224 "resreved" 225 "resreved" 226 "resreved" 227 "resreved" 228 "resreved" 229 "resreved" 230 "resreved" 231 "resreved" 232 "resreved" 233 "resreved" 234 "resreved" 235 "resreved" 236 "resreved" 237 "resreved" 238 "resreved" 239 "resreved" 240 "resreved" 241 "resreved" 242 "resreved" 243 "resreved" 244 "resreved" 245 "resreved" 246 "resreved" 247 "resreved" 248 "resreved" 249 "resreved" 250 "resreved" 251 "resreved" 252 "resreved" 253 "resreved" 254 "resreved" 255 "ERROR" ;
VAL_ 336 RHPTC_Zone1DutyFB_IGBT 0 "0x0~0xC8:Duty" 200 "0x0~0xC8:Duty" 201 "RESERVED" 202 "RESERVED" 203 "RESERVED" 204 "RESERVED" 205 "RESERVED" 206 "RESERVED" 207 "RESERVED" 208 "RESERVED" 209 "RESERVED" 210 "RESERVED" 211 "RESERVED" 212 "RESERVED" 213 "RESERVED" 214 "RESERVED" 215 "RESERVED" 216 "RESERVED" 217 "RESERVED" 218 "RESERVED" 219 "RESERVED" 220 "RESERVED" 221 "RESERVED" 222 "RESERVED" 223 "RESERVED" 224 "RESERVED" 225 "RESERVED" 226 "RESERVED" 227 "RESERVED" 228 "RESERVED" 229 "RESERVED" 230 "RESERVED" 231 "RESERVED" 232 "RESERVED" 233 "RESERVED" 234 "RESERVED" 235 "RESERVED" 236 "RESERVED" 237 "RESERVED" 238 "RESERVED" 239 "RESERVED" 240 "RESERVED" 241 "RESERVED" 242 "RESERVED" 243 "RESERVED" 244 "RESERVED" 245 "RESERVED" 246 "RESERVED" 247 "RESERVED" 248 "RESERVED" 249 "RESERVED" 250 "RESERVED" 251 "RESERVED" 252 "RESERVED" 253 "RESERVED" 254 "RESERVED" 255 "ERROR" ;
VAL_ 336 RHPTC_Zone1CoreTemp_C 0 "Temperature" 1 "Temperature" 2 "Temperature" 3 "Temperature" 4 "Temperature" 5 "Temperature" 6 "Temperature" 7 "Temperature" 8 "Temperature" 9 "Temperature" 10 "Temperature" 11 "Temperature" 12 "Temperature" 13 "Temperature" 14 "Temperature" 15 "Temperature" 241 "RESERVED" 242 "RESERVED" 243 "RESERVED" 244 "RESERVED" 245 "RESERVED" 246 "RESERVED" 247 "RESERVED" 248 "RESERVED" 249 "RESERVED" 250 "RESERVED" 251 "RESERVED" 252 "RESERVED" 253 "The thermister is open" 254 "The thermister is short" 255 "Error" ;
VAL_ 337 RHPTC_Zone1Flt 0 "Normal" 1 "Fault" ;
VAL_ 337 RHPTC_Zone1FltLVLow 0 "Normal" 1 "Fault" ;
VAL_ 337 RHPTC_Zone1FailLVSnr 0 "Normal" 1 "Fault(Open or Short)" ;
VAL_ 337 RHPTC_Zone1FailCurrentSnr 0 "Normal" 1 "Fault(Open or Short)" ;
VAL_ 337 RHPTC_Zone1FailCoreTempSnr 0 "Normal" 1 "Fault(Open or Short)" ;
VAL_ 337 RHPTC_Zone1FailPcbTempSnr 0 "Normal" 1 "Fault(Open or Short)" ;
VAL_ 337 RHPTC_Zone1FailIGBT 0 "Normal" 1 "Fault" ;
VAL_ 337 RHPTC_Zone1FailOpenLoad 0 "Normal" 1 "Fault" ;
VAL_ 337 RHPTC_Zone1LtdOpCause 0 "Normal Operation" 1 "Ltd Operation by LVLowDr" 2 "Ltd Operation by LVHighDr" 3 "Ltd Operation by HVLowDr" 4 "Ltd Operation by HVHighDr" 5 "Ltd Operation by OverCurrentDr" 8 "Ltd Operation by ThermalShutDnDr" 9 "Ltd Operation by PCBThermalShutDnDr" 10 "A~0xFF:RESERVED" 255 "A~0xFF:RESERVED" ;
VAL_ 337 RHPTC_Zone1FltLVHigh 0 "Normal" 1 "Fault" ;
VAL_ 337 RHPTC_Zone1SwVer 0 "0x0~0xFF" 255 "0x0~0xFF" ;
VAL_ 337 RHPTC_Zone1FltHVLow 0 "Normal" 1 "Fault" ;
VAL_ 337 RHPTC_CnsmptPwrTtl_W 0 "0x0~0x2710:Power" 10000 "0x0~0x2710:Power" 65535 "ERROR" ;
VAL_ 337 RHPTC_Zone1FltHVHigh 0 "Normal" 1 "Fault" ;
VAL_ 337 RHPTC_IntlkSta 0 "Disconnect" 1 "Connect" 2 "Default" 3 "Error Indicator" ;
VAL_ 337 RHPTC_Zone1FltOverCurrent 0 "Normal" 1 "Fault" ;
VAL_ 337 RHPTC_Zone1FltThermalShutDn 0 "Normal" 1 "Fault" ;
VAL_ 337 RHPTC_Zone1FltPcbThermalShutDn 0 "Normal" 1 "Fault" ;
VAL_ 337 RHPTC_Zone1FltMsgTmOutATCU 0 "Normal" 1 "Message Timeout" ;
VAL_ 337 RHPTC_Zone1FailHVSnr 0 "Normal" 1 "Fault(Open or Short)" ;
VAL_ 338 RHPTC_Zone2RdySta 0 "Not Ready(Disable to control)" 1 "Ready (Enable to Control)" ;
VAL_ 338 RHPTC_Zone2OpSta 0 "Stop Mode" 1 "Operation Mode" 2 "Failure Mode" 3 "Limited operation Mode" ;
VAL_ 338 RHPTC_Zone2CnsmptPwr_W 0 "Single PTC & Single Control" 1 "Dual PTC & Single Control" 2 "Dual PTC & Dual Control" 3 "RESERVED" 4 "RESERVED" 5 "RESERVED" 6 "RESERVED" 7 "RESERVED" ;
VAL_ 338 RHPTC_Zone2CtrlTyp 0 "Not Ready(Disable to control)" 1 "Ready (Enable to Control)" ;
VAL_ 338 RHPTC_Zone2Voltage_V 0 "Temperature" 1 "Temperature" 2 "Temperature" 3 "Temperature" 4 "Temperature" 5 "Temperature" 6 "Temperature" 7 "Temperature" 8 "Temperature" 9 "Temperature" 10 "Temperature" 11 "Temperature" 12 "Temperature" 13 "Temperature" 14 "Temperature" 15 "Temperature" 241 "RESERVED" 242 "RESERVED" 243 "RESERVED" 244 "RESERVED" 245 "RESERVED" 246 "RESERVED" 247 "RESERVED" 248 "RESERVED" 249 "RESERVED" 250 "RESERVED" 251 "RESERVED" 252 "RESERVED" 253 "The thermister is open" 254 "The thermister is short" 255 "Error" ;
VAL_ 338 RHPTC_Zone2Current_A 255 "ERROR" ;
VAL_ 338 RHPTC_Zone2DutyFB_Pec 0 "0x0~0xFA:Voltage" 250 "0x0~0xFA:Voltage" 251 "RESERVED" 252 "RESERVED" 253 "RESERVED" 254 "RESERVED" 255 "ERROR" ;
VAL_ 338 RHPTC_Zone2DutyFB_IGBT 0 "0x0~0xFA:Current" 250 "0x0~0xFA:Current" 251 "RESERVED" 252 "RESERVED" 253 "RESERVED" 254 "RESERVED" 255 "ERROR" ;
VAL_ 338 RHPTC_Zone2CoreTemp_C 0 "Stop Mode" 1 "Operation Mode" 2 "Failure Mode" 3 "Limited operation Mode" ;
VAL_ 339 RHPTC_Zone2Flt 0 "Normal" 1 "Fault" ;
VAL_ 339 RHPTC_Zone2FltLVLow 0 "Normal" 1 "Fault" ;
VAL_ 339 RHPTC_Zone2FailLVSnr 0 "Normal" 1 "Message Timeout" ;
VAL_ 339 RHPTC_Zone2FailCurrentSnr 0 "Normal" 1 "Fault(Open or Short)" ;
VAL_ 339 RHPTC_Zone2FailCoreTempSnr 0 "Normal" 1 "Fault(Open or Short)" ;
VAL_ 339 RHPTC_Zone2FailPcbTempSnr 0 "Normal" 1 "Fault(Open or Short)" ;
VAL_ 339 RHPTC_Zone2FailIGBT 0 "Normal" 1 "Fault(Open or Short)" ;
VAL_ 339 RHPTC_Zone2FailOpenLoad 0 "Normal" 1 "Fault(Open or Short)" ;
VAL_ 339 RHPTC_Zone2LtdOpCause 0 "Normal" 1 "Fault" ;
VAL_ 339 RHPTC_Zone2FltLVHigh 0 "Normal" 1 "Fault" ;
VAL_ 339 RHPTC_Zone2SwrVer 0 "Normal" 1 "Fault" ;
VAL_ 339 RHPTC_Zone2FltHVLow 0 "Normal" 1 "Fault" ;
VAL_ 339 RHPTC_Zone2FltHVHigh 0 "Normal" 1 "Fault" ;
VAL_ 339 RHPTC_Zone2FltOverCurrent 0 "Normal" 1 "Fault" ;
VAL_ 339 RHPTC_Zone2FltThermalShutDn 0 "Normal" 1 "Fault" ;
VAL_ 339 RHPTC_Zone2FltPcbThermalShutDn 0 "Normal" 1 "Fault" ;
VAL_ 339 RHPTC_Zone2FltMsgTmOutATCU 0 "Normal" 1 "Fault" ;
VAL_ 339 RHPTC_Zone2FailHVSnr 0 "Normal" 1 "Fault" ;
